VERSION "HNNBNNNYNNNNNNNNNNNNNNNNNNNNNNNNNNNNNNNNNN/4/%%%/4/'%**4NNN///"

NS_ :

BS_:

BU_: BAP_Tester Gateway_Max Getriebe_DQ Motor_konv Parksperre Schaltbetaetigung

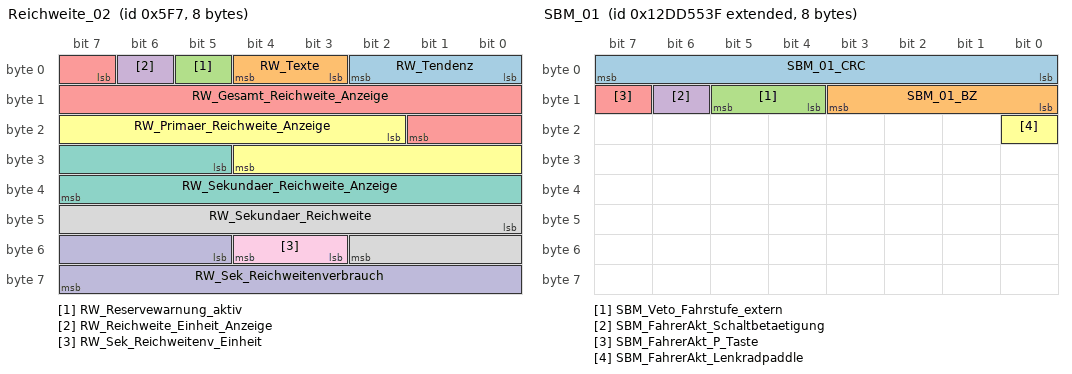
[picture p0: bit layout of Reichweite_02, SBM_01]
BO_ 1527 Reichweite_02: 8 Gateway_Max
 SG_ RW_Tendenz : 0|3@1+ (1.0,0.0) [0.0|7] ""  Vector__XXX
 SG_ RW_Texte : 3|2@1+ (1.0,0.0) [0.0|3] ""  Vector__XXX
 SG_ RW_Reservewarnung_aktiv : 5|1@1+ (1.0,0.0) [0.0|1] ""  Vector__XXX
 SG_ RW_Reichweite_Einheit_Anzeige : 6|1@1+ (1.0,0.0) [0.0|1] ""  Vector__XXX
 SG_ RW_Gesamt_Reichweite_Anzeige : 7|11@1+ (1,0) [0|2044] "Unit_None"  Vector__XXX
 SG_ RW_Primaer_Reichweite_Anzeige : 18|11@1+ (1,0) [0|2044] "Unit_None"  Vector__XXX
 SG_ RW_Sekundaer_Reichweite_Anzeige : 29|11@1+ (1,0) [0|2044] "Unit_None"  Vector__XXX
 SG_ RW_Sekundaer_Reichweite : 40|11@1+ (1,0) [0|2044] "Unit_KiloMeter"  Vector__XXX
 SG_ RW_Sek_Reichweitenv_Einheit : 51|2@1+ (1.0,0.0) [0.0|3] ""  Vector__XXX
 SG_ RW_Sek_Reichweitenverbrauch : 53|11@1+ (0.1,0) [0.0|204.4] "Unit_None"  Vector__XXX

BO_ 2264486920 RHP_01: 32 Gateway_Max
 SG_ RHP_01_CRC : 0|8@1+ (1,0) [0|255] ""  Motor_konv
 SG_ RHP_01_BZ : 8|4@1+ (1,0) [0|15] ""  Motor_konv
 SG_ RHP_QFK_AnfStat : 12|4@1+ (1.0,0.0) [0.0|15] ""  Vector__XXX
 SG_ RHP_QFK_Spuerb : 16|8@1+ (0.4,0) [0.0|100.0] "Unit_PerCent"  Vector__XXX
 SG_ RHP_QFK_KruemmSoll : 24|15@1+ (0.0000067,0) [0E-7|0.2195389] "Unit_MeterInver"  Vector__XXX
 SG_ RHP_TV_Trigger : 39|1@1+ (1.0,0.0) [0.0|1] ""  Vector__XXX
 SG_ RHP_QFK_Signal1 : 40|10@1+ (1,0) [0|1023] ""  Vector__XXX
 SG_ RHP_QFK_Art1 : 50|3@1+ (1,0) [0|7] ""  Vector__XXX
 SG_ RHP_QFK_Art2 : 53|3@1+ (1,0) [0|7] ""  Vector__XXX
 SG_ RHP_QFK_Signal2 : 56|10@1+ (1,0) [0|1023] ""  Vector__XXX
 SG_ RHP_QFK_KruemmSoll_VZ : 66|1@1+ (1.0,0.0) [0.0|1] ""  Vector__XXX
 SG_ RHP_Status_Long : 67|3@1+ (1.0,0.0) [0.0|7] ""  Vector__XXX
 SG_ RHP_Ruckfreigabe : 70|1@1+ (1.0,0.0) [0.0|1] ""  Vector__XXX
 SG_ RHP_Warnruckeln_Anf : 71|3@1+ (1.0,0.0) [0.0|7] ""  Vector__XXX
 SG_ RHP_Anf_ASIL : 74|3@1+ (1.0,0.0) [0.0|7] ""  Vector__XXX
 SG_ RHP_Anforderung_HMS : 77|3@1+ (1.0,0.0) [0.0|7] ""  Vector__XXX
 SG_ RHP_pos_Sollbeschl_Grad : 80|8@1+ (0.05,0) [0.00|12.75] "Unit_MeterPerCubicSecon"  Motor_konv
 SG_ RHP_neg_Sollbeschl_Grad : 88|8@1+ (0.05,0) [0.00|12.75] "Unit_MeterPerCubicSecon"  Motor_konv
 SG_ RHP_Sollbeschleunigung : 96|11@1+ (0.005,-7.22) [-7.220|3.005] "Unit_MeterPerSeconSquar"  Motor_konv
 SG_ RHP_zul_Regelabw_oben : 107|5@1+ (0.0625,0) [0.0000|1.9375] "Unit_MeterPerSeconSquar"  Motor_konv
 SG_ RHP_zul_Regelabw_unten : 112|6@1+ (0.024,0) [0.000|1.512] "Unit_MeterPerSeconSquar"  Motor_konv
 SG_ RHP_TSK_Status : 118|3@1+ (1.0,0.0) [0.0|7] ""  Motor_konv
 SG_ RHP_Minimale_Bremsung : 121|1@1+ (1.0,0.0) [0.0|1] ""  Motor_konv
 SG_ RHP_Uss_Anforderung : 122|2@1+ (1.0,0.0) [0.0|3] ""  Vector__XXX
 SG_ RHP_Verz_Anf : 124|10@1+ (0.024,-20.016) [-20.016|4.512] "Unit_MeterPerSeconSquar"  Vector__XXX
 SG_ RHP_Verz_Freigabe : 134|1@1+ (1.0,0.0) [0.0|1] ""  Vector__XXX
 SG_ RHP_Status_Lat : 135|3@1+ (1.0,0.0) [0.0|7] ""  Vector__XXX
 SG_ RHP_StartStopp_Info : 138|2@1+ (1.0,0.0) [0.0|3] ""  Motor_konv
 SG_ RHP_nachtr_Stopp_Anf : 140|1@1+ (1.0,0.0) [0.0|1] ""  Motor_konv
 SG_ RHP_Freilaufstrategie_TSK : 141|1@1+ (1.0,0.0) [0.0|1] ""  Motor_konv
 SG_ RHP_SCAM_HeatingRequest : 142|2@1+ (1.0,0.0) [0.0|3] ""  Vector__XXX
 SG_ RHP_Fahrzeughupe_Anf : 144|1@1+ (1.0,0.0) [0.0|1] ""  Vector__XXX
 SG_ RHP_HOS : 145|2@1+ (1.0,0.0) [0.0|3] ""  Vector__XXX
 SG_ RHP_Status_Function : 147|3@1+ (1.0,0.0) [0.0|7] ""  Motor_konv
 SG_ RHP_EA_AnfStat : 150|2@1+ (1.0,0.0) [0.0|3] ""  Vector__XXX
 SG_ RHP_QFK_KrSoll : 152|16@1+ (0.0000067,0) [0E-7|0.4390845] "Unit_MeterInver"  Vector__XXX
 SG_ RHP_QFK_KrSoll_VZ : 168|1@1+ (1.0,0.0) [0.0|1] ""  Vector__XXX
 SG_ RHP_Warnblinken : 169|1@1+ (1.0,0.0) [0.0|1] ""  Vector__XXX
 SG_ RHP_Innenraumlicht_Anf : 170|1@1+ (1.0,0.0) [0.0|1] ""  Vector__XXX
 SG_ RHP_Spurwechsel_Ready : 171|3@1+ (1.0,0.0) [0.0|7] ""  Vector__XXX
 SG_ RHP_RBF_Available : 174|2@1+ (1.0,0.0) [0.0|3] ""  Vector__XXX
 SG_ RHP_PreCrash_Anf : 176|3@1+ (1.0,0.0) [0.0|7] ""  Vector__XXX
 SG_ RHP_EA_PreCrash : 179|3@1+ (1.0,0.0) [0.0|7] ""  Vector__XXX
 SG_ RHP_Parking_St : 182|2@1+ (1.0,0.0) [0.0|3] ""  Vector__XXX
 SG_ RHP_EA_Innenraumlicht : 184|1@1+ (1.0,0.0) [0.0|1] ""  Vector__XXX
 SG_ RHP_EA_eCall : 185|1@1+ (1.0,0.0) [0.0|1] ""  Vector__XXX
 SG_ RHP_OPSEnable : 186|2@1+ (1.0,0.0) [0.0|3] ""  Vector__XXX
 SG_ RHP_eCall_Anf : 188|1@1+ (1.0,0.0) [0.0|1] ""  Vector__XXX
 SG_ RHP_EA_Tueren : 189|1@1+ (1.0,0.0) [0.0|1] ""  Vector__XXX

BO_ 2463978815 SBM_01: 8 Getriebe_DQ
 SG_ SBM_01_CRC : 0|8@1+ (1,0) [0|255] ""  Gateway_Max
 SG_ SBM_01_BZ : 8|4@1+ (1,0) [0|15] ""  Gateway_Max
 SG_ SBM_Veto_Fahrstufe_extern : 12|2@1+ (1.0,0.0) [0.0|3] ""  Gateway_Max
 SG_ SBM_FahrerAkt_Schaltbetaetigung : 14|1@1+ (1.0,0.0) [0.0|1] ""  Gateway_Max
 SG_ SBM_FahrerAkt_P_Taste : 15|1@1+ (1.0,0.0) [0.0|1] ""  Gateway_Max
 SG_ SBM_FahrerAkt_Lenkradpaddle : 16|1@1+ (1.0,0.0) [0.0|1] ""  Gateway_Max

BO_ 980 SMLS_01: 8 Gateway_Max
 SG_ SMLS_01_CRC : 0|8@1+ (1,0) [0|255] ""  Vector__XXX
 SG_ SMLS_01_BZ : 8|4@1+ (1,0) [0|15] ""  Vector__XXX
 SG_ BH_Blinker_li : 12|1@1+ (1.0,0.0) [0.0|1] ""  Motor_konv
 SG_ BH_Blinker_re : 13|1@1+ (1.0,0.0) [0.0|1] ""  Motor_konv
 SG_ BH_Lichthupe : 14|1@1+ (1.0,0.0) [0.0|1] ""  Vector__XXX
 SG_ BH_Fernlicht : 15|1@1+ (1.0,0.0) [0.0|1] ""  Vector__XXX
 SG_ WH_Tipwischen : 16|1@1+ (1.0,0.0) [0.0|1] ""  Vector__XXX
 SG_ WH_Intervall : 17|1@1+ (1.0,0.0) [0.0|1] ""  Vector__XXX
 SG_ WH_WischerStufe1 : 18|1@1+ (1.0,0.0) [0.0|1] ""  Vector__XXX
 SG_ WH_WischerStufe2 : 19|1@1+ (1.0,0.0) [0.0|1] ""  Vector__XXX
 SG_ WH_Frontwaschen : 20|1@1+ (1.0,0.0) [0.0|1] ""  Vector__XXX
 SG_ WH_Heckintervall : 21|1@1+ (1.0,0.0) [0.0|1] ""  Vector__XXX
 SG_ WH_Heckwaschen : 22|1@1+ (1.0,0.0) [0.0|1] ""  Vector__XXX
 SG_ WH_Intervallstufen : 23|4@1+ (1.0,0.0) [0.0|15] ""  Vector__XXX
 SG_ FAS_Taster : 27|1@1+ (1.0,0.0) [0.0|1] ""  Vector__XXX
 SG_ FAS_Taster_Fehler : 28|1@1+ (1.0,0.0) [0.0|1] ""  Vector__XXX
 SG_ SMLS_Hupe : 29|1@1+ (1.0,0.0) [0.0|1] ""  Vector__XXX
 SG_ LRH_On_Off : 30|2@1+ (1.0,0.0) [0.0|3] ""  Vector__XXX
 SG_ LSS_Tastencode : 32|8@1+ (1.0,0.0) [0.0|255] ""  Vector__XXX
 SG_ LRH_aktiv : 40|1@1+ (1.0,0.0) [0.0|1] ""  Vector__XXX
 SG_ SMLS_P_verriegelt : 41|2@1+ (1.0,0.0) [0.0|3] ""  Vector__XXX
 SG_ SMLS_P_verriegelt_plausibel : 43|1@1+ (1.0,0.0) [0.0|1] ""  Vector__XXX
 SG_ WH_SRA : 44|1@1+ (1.0,0.0) [0.0|1] ""  Vector__XXX
 SG_ WH_Wischer_Fehler : 45|1@1+ (1.0,0.0) [0.0|1] ""  Vector__XXX
 SG_ BH_Blinker_Fehler : 46|1@1+ (1.0,0.0) [0.0|1] ""  Vector__XXX
 SG_ SMLS_PTT : 47|1@1+ (1.0,0.0) [0.0|1] ""  Vector__XXX
 SG_ WH_Tipwischen_lang : 48|1@1+ (1.0,0.0) [0.0|1] ""  Vector__XXX

BO_ 2589283756 SOK_NoAuthenticTime_01: 8 Gateway_Max
 SG_ SOK_ungeschuetzte_Zeit : 8|56@1+ (1,0) [1|72057594037927935] "Unit_None"  Getriebe_DQ,Motor_konv

BO_ 2464153724 SOK_Zeit_EMotor_01_Chal_01: 8 Vector__XXX
 SG_ SOK_Zeit_EMotor_01_Challenge : 0|64@1+ (1,0) [0|18446744073709551615] "Unit_None"  Gateway_Max

BO_ 2464284796 SOK_Zeit_EMotor_01_Resp_01: 16 Gateway_Max
 SG_ SOK_Zeit_EMotor_01_Zeit : 0|56@1+ (1,0) [0|72057594037927935] "Unit_None"  Vector__XXX
 SG_ SOK_Zeit_EMotor_01_Signatur : 64|64@1+ (1,0) [0|18446744073709551615] "Unit_None"  Vector__XXX

BO_ 2464153784 SOK_Zeit_EMotor_02_Chal_01: 8 Vector__XXX
 SG_ SOK_Zeit_EMotor_02_Challenge : 0|64@1+ (1,0) [0|18446744073709551615] "Unit_None"  Gateway_Max

BO_ 2464284856 SOK_Zeit_EMotor_02_Resp_01: 16 Gateway_Max
 SG_ SOK_Zeit_EMotor_02_Zeit : 0|56@1+ (1,0) [0|72057594037927935] "Unit_None"  Vector__XXX
 SG_ SOK_Zeit_EMotor_02_Signatur : 64|64@1+ (1,0) [0|18446744073709551615] "Unit_None"  Vector__XXX

BO_ 2464153719 SOK_Zeit_Getriebe_01_Chal_01: 8 Getriebe_DQ
 SG_ SOK_Zeit_Getriebe_01_Challenge : 0|64@1+ (1,0) [0|18446744073709551615] "Unit_None"  Gateway_Max

BO_ 2464284791 SOK_Zeit_Getriebe_01_Resp_01: 16 Gateway_Max
 SG_ SOK_Zeit_Getriebe_01_Zeit : 0|56@1+ (1,0) [0|72057594037927935] "Unit_None"  Getriebe_DQ
 SG_ SOK_Zeit_Getriebe_01_Signatur : 64|64@1+ (1,0) [0|18446744073709551615] "Unit_None"  Getriebe_DQ

BO_ 2464153913 SOK_Zeit_LCU_SMH_Chal_01: 8 Vector__XXX
 SG_ SOK_Zeit_LCU_SMH_Challenge : 0|64@1+ (1,0) [0|18446744073709551615] "Unit_None"  Gateway_Max

BO_ 2464284985 SOK_Zeit_LCU_SMH_Resp_01: 16 Gateway_Max
 SG_ SOK_Zeit_LCU_SMH_Zeit : 0|56@1+ (1,0) [0|72057594037927935] "Unit_None"  Vector__XXX
 SG_ SOK_Zeit_LCU_SMH_Signatur : 64|64@1+ (1,0) [0|18446744073709551615] ""  Vector__XXX

BO_ 2464157814 SOK_Zeit_MO_01_Chal_02: 8 Motor_konv
 SG_ SOK_Zeit_MO_01_Challenge : 0|64@1+ (1,0) [0|18446744073709551615] "Unit_None"  Gateway_Max

BO_ 2464288886 SOK_Zeit_MO_01_Resp_02: 16 Gateway_Max
 SG_ SOK_Zeit_MO_01_Zeit : 0|56@1+ (1,0) [0|72057594037927935] "Unit_None"  Motor_konv
 SG_ SOK_Zeit_MO_01_Signatur : 64|64@1+ (1,0) [0|18446744073709551615] "Unit_None"  Motor_konv

BO_ 2464153733 SOK_Zeit_RSG_Chal_01: 8 Vector__XXX
 SG_ SOK_Zeit_RSG_Challenge : 0|64@1+ (1,0) [0|18446744073709551615] "Unit_None"  Gateway_Max

BO_ 2464284805 SOK_Zeit_RSG_Resp_01: 16 Gateway_Max
 SG_ SOK_Zeit_RSG_Zeit : 0|56@1+ (1,0) [0|72057594037927935] "Unit_None"  Vector__XXX
 SG_ SOK_Zeit_RSG_Signatur : 64|64@1+ (1,0) [0|18446744073709551615] ""  Vector__XXX

BO_ 1313 STH_01: 8 Gateway_Max
 SG_ STH_Funk_ein : 0|1@1+ (1.0,0.0) [0.0|1] ""  Vector__XXX
 SG_ STH_Funk_aus : 1|1@1+ (1.0,0.0) [0.0|1] ""  Vector__XXX
 SG_ STH_Zusatzheizung : 2|1@1+ (1.0,0.0) [0.0|1] ""  Motor_konv
 SG_ STH_LED : 3|1@1+ (1.0,0.0) [0.0|1] ""  Motor_konv
 SG_ STH_Pumpe_ein : 4|1@1+ (1,0) [0|1] ""  Motor_konv
 SG_ STH_Geblaese : 5|1@1+ (1.0,0.0) [0.0|1] ""  Vector__XXX
 SG_ STH_EKP_Anst : 6|1@1+ (1.0,0.0) [0.0|1] ""  Motor_konv
 SG_ STH_Start_folgt : 7|1@1+ (1.0,0.0) [0.0|1] ""  Vector__XXX
 SG_ STH_Ventiloeffnungszeit : 8|6@1+ (1,0) [0|63] "Unit_Minut"  Vector__XXX
 SG_ STH_Ventil_Status : 14|1@1+ (1.0,0.0) [0.0|1] ""  Motor_konv
 SG_ STH_Fehler_ElWaPu : 15|1@1+ (1.0,0.0) [0.0|1] ""  Motor_konv
 SG_ STH_Waermeeintrag : 16|6@1+ (1,0) [0|63] "Unit_None"  Motor_konv
 SG_ STH_Pumpen_Anf_extern : 22|1@1+ (1.0,0.0) [0.0|1] ""  Motor_konv
 SG_ STH_KL_HUP : 23|1@1+ (1.0,0.0) [0.0|1] ""  Vector__XXX
 SG_ STH_KVS : 24|13@1+ (1,0) [0|8191] "Unit_MilliLiter"  Vector__XXX
 SG_ STH_Fehlerstatus : 37|3@1+ (1.0,0.0) [0.0|7] ""  Vector__XXX
 SG_ STH_Heizleistung : 40|8@1+ (1,0) [0|255] ""  Vector__XXX
 SG_ STH_Wassertemp : 48|8@1+ (0.75,-40) [-40.00|142.25] "Unit_DegreCelsi"  Motor_konv
 SG_ STH_Texte : 56|3@1+ (1.0,0.0) [0.0|7] ""  Vector__XXX
 SG_ STH_Motorvorwaermung : 59|1@1+ (1.0,0.0) [0.0|1] ""  Motor_konv
 SG_ STH_Servicemode : 60|1@1+ (1.0,0.0) [0.0|1] ""  Vector__XXX
 SG_ STH_war_aktiv : 61|1@1+ (1.0,0.0) [0.0|1] ""  Motor_konv
 SG_ STH_KVS_Ueberlauf : 62|1@1+ (1.0,0.0) [0.0|1] ""  Vector__XXX
 SG_ STH_SH_ZH : 63|1@1+ (1.0,0.0) [0.0|1] ""  Vector__XXX

BO_ 1413 Systeminfo_01: 8 Gateway_Max
 SG_ SI_Sammel_SG_Fehler : 0|6@1+ (1,0) [0|60] ""  Vector__XXX
 SG_ SI_P_Mode_gueltig : 6|1@1+ (1.0,0.0) [0.0|1] ""  Getriebe_DQ,Motor_konv
 SG_ SI_Diagnose_Aktiv : 7|1@1+ (1.0,0.0) [0.0|1] ""  Vector__XXX
 SG_ SI_QRS_Mode : 8|1@1+ (1.0,0.0) [0.0|1] ""  Getriebe_DQ,Motor_konv
 SG_ SI_T_Mode : 9|1@1+ (1.0,0.0) [0.0|1] ""  Getriebe_DQ,Motor_konv
 SG_ SI_NWDF : 10|1@1+ (1.0,0.0) [0.0|1] ""  Getriebe_DQ
 SG_ SI_NWDF_gueltig : 11|1@1+ (1.0,0.0) [0.0|1] ""  Getriebe_DQ
 SG_ SI_Sammelfehler : 12|1@1+ (1.0,0.0) [0.0|1] ""  Vector__XXX
 SG_ GW_KD_Fehler : 13|1@1+ (1.0,0.0) [0.0|1] ""  Vector__XXX
 SG_ SI_T_Schutz : 14|1@1+ (1.0,0.0) [0.0|1] ""  Getriebe_DQ,Motor_konv
 SG_ SI_P_Mode : 15|1@1+ (1.0,0.0) [0.0|1] ""  Getriebe_DQ,Motor_konv
 SG_ SI_BUS_01 : 16|1@1+ (1.0,0.0) [0.0|1] ""  Vector__XXX
 SG_ SI_BUS_02 : 17|1@1+ (1.0,0.0) [0.0|1] ""  Getriebe_DQ
 SG_ SI_BUS_03 : 18|1@1+ (1.0,0.0) [0.0|1] ""  Getriebe_DQ,Motor_konv
 SG_ SI_BUS_04 : 19|1@1+ (1.0,0.0) [0.0|1] ""  Vector__XXX
 SG_ SI_BUS_05 : 20|1@1+ (1.0,0.0) [0.0|1] ""  Vector__XXX
 SG_ SI_BUS_06 : 21|1@1+ (1.0,0.0) [0.0|1] ""  Getriebe_DQ
 SG_ SI_BUS_07 : 22|1@1+ (1.0,0.0) [0.0|1] ""  Vector__XXX
 SG_ SI_BUS_08 : 23|1@1+ (1.0,0.0) [0.0|1] ""  Vector__XXX
 SG_ SI_BUS_09 : 24|1@1+ (1.0,0.0) [0.0|1] ""  Vector__XXX
 SG_ SI_BUS_10 : 25|1@1+ (1.0,0.0) [0.0|1] ""  Vector__XXX
 SG_ SI_BUS_11 : 26|1@1+ (1.0,0.0) [0.0|1] ""  Vector__XXX
 SG_ SI_BUS_12 : 27|1@1+ (1.0,0.0) [0.0|1] ""  Vector__XXX
 SG_ SI_BUS_13 : 28|1@1+ (1.0,0.0) [0.0|1] ""  Vector__XXX
 SG_ SI_BUS_14 : 29|1@1+ (1.0,0.0) [0.0|1] ""  Vector__XXX
 SG_ SI_BUS_15 : 30|1@1+ (1.0,0.0) [0.0|1] ""  Vector__XXX
 SG_ SI_NWDF_30 : 31|1@1+ (1.0,0.0) [0.0|1] ""  Vector__XXX
 SG_ SI_Bus_Identifikation : 32|8@1+ (1.0,0.0) [0.0|255] ""  Vector__XXX
 SG_ SI_CAB_V14 : 40|24@1+ (1.0,0.0) [0.0|16777215] ""  Motor_konv

BO_ 2589283571 TLI_03: 16 Gateway_Max
 SG_ TLI_LSA1_Info_Backlog : 12|2@1+ (1.0,0.0) [0.0|3] ""  Motor_konv
 SG_ TLI_LSA1_GLOSA_Unit : 14|2@1+ (1.0,0.0) [0.0|3] ""  Motor_konv
 SG_ TLI_LSA1_TTG : 16|8@1+ (1,0) [0|250] "Unit_Secon"  Motor_konv
 SG_ TLI_LSA1_GLOSA : 24|8@1+ (1,0) [0|200] "Unit_None"  Motor_konv
 SG_ TLI_LSA1_GLOSA_Display : 32|8@1+ (1,0) [0|200] "Unit_None"  Motor_konv
 SG_ TLI_LSA1_Data_Age : 40|12@1+ (0.1,0) [0.0|400.0] "Unit_Secon"  Motor_konv
 SG_ TLI_LSA1_Data_Source : 52|3@1+ (1.0,0.0) [0.0|7] ""  Motor_konv
 SG_ TLI_LSA1_Distance_Backlog : 55|9@1+ (1,0) [0|500] "Unit_Meter"  Motor_konv
 SG_ TLI_LSA1_Distance_Stop_Line : 64|13@1+ (0.1,0) [0.0|500.0] "Unit_Meter"  Motor_konv
 SG_ TLI_LSA1_Direction_N : 78|2@1+ (1.0,0.0) [0.0|3] ""  Motor_konv
 SG_ TLI_LSA1_Direction_NE : 80|2@1+ (1.0,0.0) [0.0|3] ""  Motor_konv
 SG_ TLI_LSA1_Direction_E : 82|2@1+ (1.0,0.0) [0.0|3] ""  Motor_konv
 SG_ TLI_LSA1_Direction_SE : 84|2@1+ (1.0,0.0) [0.0|3] ""  Motor_konv
 SG_ TLI_LSA1_Direction_SW : 86|2@1+ (1.0,0.0) [0.0|3] ""  Motor_konv
 SG_ TLI_LSA1_Direction_W : 88|2@1+ (1.0,0.0) [0.0|3] ""  Motor_konv
 SG_ TLI_LSA1_Direction_NW : 90|2@1+ (1.0,0.0) [0.0|3] ""  Motor_konv
 SG_ TLI_LSA1_Direction_U_Turn_NE : 92|2@1+ (1.0,0.0) [0.0|3] ""  Motor_konv
 SG_ TLI_LSA1_Direction_U_Turn_NW : 94|2@1+ (1.0,0.0) [0.0|3] ""  Motor_konv

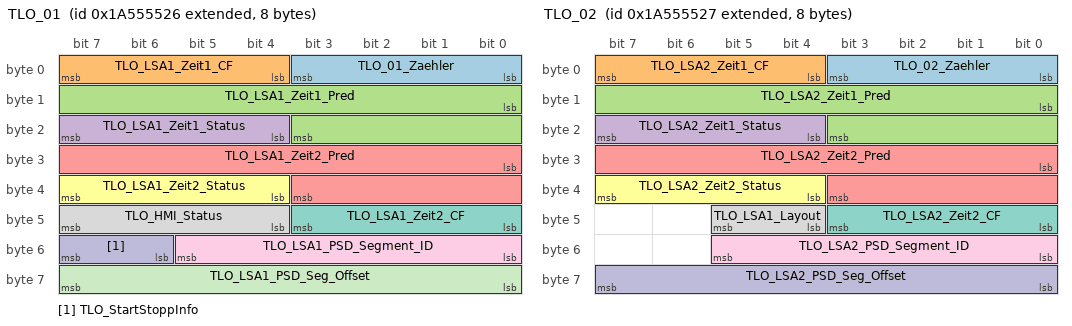
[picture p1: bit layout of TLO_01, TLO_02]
BO_ 2589283622 TLO_01: 8 Gateway_Max
 SG_ TLO_01_Zaehler : 0|4@1+ (1,0) [0|15] ""  Motor_konv
 SG_ TLO_LSA1_Zeit1_CF : 4|4@1+ (1,0) [0|15] "Unit_None"  Motor_konv
 SG_ TLO_LSA1_Zeit1_Pred : 8|12@1+ (0.1,-0.1) [0.0|409.4] "Unit_Secon"  Motor_konv
 SG_ TLO_LSA1_Zeit1_Status : 20|4@1+ (1.0,0.0) [0.0|15] ""  Motor_konv
 SG_ TLO_LSA1_Zeit2_Pred : 24|12@1+ (0.1,-0.1) [0.0|409.4] "Unit_Secon"  Motor_konv
 SG_ TLO_LSA1_Zeit2_Status : 36|4@1+ (1.0,0.0) [0.0|15] ""  Motor_konv
 SG_ TLO_LSA1_Zeit2_CF : 40|4@1+ (1,0) [0|15] "Unit_None"  Motor_konv
 SG_ TLO_HMI_Status : 44|4@1+ (1.0,0.0) [0.0|15] ""  Motor_konv
 SG_ TLO_LSA1_PSD_Segment_ID : 48|6@1+ (1,0) [2|63] "Unit_None"  Motor_konv
 SG_ TLO_StartStoppInfo : 54|2@1+ (1.0,0.0) [0.0|3] ""  Motor_konv
 SG_ TLO_LSA1_PSD_Seg_Offset : 56|8@1+ (1,0) [0|254] "Unit_Meter"  Motor_konv

BO_ 2589283623 TLO_02: 8 Gateway_Max
 SG_ TLO_02_Zaehler : 0|4@1+ (1,0) [0|15] ""  Motor_konv
 SG_ TLO_LSA2_Zeit1_CF : 4|4@1+ (1,0) [0|15] "Unit_None"  Motor_konv
 SG_ TLO_LSA2_Zeit1_Pred : 8|12@1+ (0.1,-0.1) [0.0|409.4] "Unit_Secon"  Motor_konv
 SG_ TLO_LSA2_Zeit1_Status : 20|4@1+ (1.0,0.0) [0.0|15] ""  Motor_konv
 SG_ TLO_LSA2_Zeit2_Pred : 24|12@1+ (0.1,-0.1) [0.0|409.4] "Unit_Secon"  Motor_konv
 SG_ TLO_LSA2_Zeit2_Status : 36|4@1+ (1.0,0.0) [0.0|15] ""  Motor_konv
 SG_ TLO_LSA2_Zeit2_CF : 40|4@1+ (1,0) [0|15] "Unit_None"  Motor_konv
 SG_ TLO_LSA1_Layout : 44|2@1+ (1.0,0.0) [0.0|3] ""  Motor_konv
 SG_ TLO_LSA2_PSD_Segment_ID : 48|6@1+ (1,0) [2|63] "Unit_None"  Motor_konv
 SG_ TLO_LSA2_PSD_Seg_Offset : 56|8@1+ (1,0) [0|254] "Unit_Meter"  Motor_konv

BO_ 1447 TM_01: 8 Gateway_Max
 SG_ ORU_KombiTimer : 20|2@1+ (1.0,0.0) [0.0|3] ""  Vector__XXX
 SG_ MOD_Energie_Anf : 22|2@1+ (1.0,0.0) [0.0|3] ""  Vector__XXX
 SG_ FaceRec_Enroll_Challenge_Request : 24|1@1+ (1.0,0.0) [0.0|1] ""  Vector__XXX
 SG_ eCall_Mute_Anf : 25|1@1+ (1.0,0.0) [0.0|1] ""  Vector__XXX
 SG_ eCall_MCC : 26|10@1+ (1,0) [0|999] "Unit_None"  Vector__XXX
 SG_ FoD_Anz_Funktionsabschaltung : 36|2@1+ (1.0,0.0) [0.0|3] ""  Vector__XXX
 SG_ iCall_active : 38|1@1+ (1.0,0.0) [0.0|1] ""  Vector__XXX
 SG_ bCall_active : 39|1@1+ (1.0,0.0) [0.0|1] ""  Vector__XXX
 SG_ MOD_Request_ServiceKey : 40|1@1+ (1.0,0.0) [0.0|1] ""  Vector__XXX
 SG_ eCall_Funktionsstatus_02 : 41|3@1+ (1.0,0.0) [0.0|7] ""  Vector__XXX
 SG_ eCall_Funktionsstatus : 44|3@1+ (1.0,0.0) [0.0|7] ""  Vector__XXX
 SG_ TM_Spiegel_Anklappen : 47|1@1+ (1.0,0.0) [0.0|1] ""  Vector__XXX
 SG_ TM_Nur_Hupen : 48|1@1+ (1.0,0.0) [0.0|1] ""  Vector__XXX
 SG_ TM_Door_Lock : 49|1@1+ (1.0,0.0) [0.0|1] ""  Vector__XXX
 SG_ TM_Door_Unlock : 50|1@1+ (1.0,0.0) [0.0|1] ""  Vector__XXX
 SG_ TM_Warnblinken : 51|1@1+ (1.0,0.0) [0.0|1] ""  Vector__XXX
 SG_ TM_Panik_Alarm : 52|1@1+ (1.0,0.0) [0.0|1] ""  Vector__XXX
 SG_ TM_ZV_Signatur : 53|11@1+ (1,0) [1|2047] "Unit_None"  Vector__XXX

BO_ 976 TSG_FT_01: 8 Gateway_Max
 SG_ FT_Tuer_geoeffnet : 0|1@1+ (1.0,0.0) [0.0|1] ""  Vector__XXX
 SG_ FT_verriegelt : 1|1@1+ (1.0,0.0) [0.0|1] ""  Vector__XXX
 SG_ FT_gesafet : 2|1@1+ (1.0,0.0) [0.0|1] ""  Vector__XXX
 SG_ FT_Schluesselschalter_auf : 3|1@1+ (1.0,0.0) [0.0|1] ""  Vector__XXX
 SG_ FT_Schluesselschalter_zu : 4|1@1+ (1.0,0.0) [0.0|1] ""  Vector__XXX
 SG_ FT_Unlock_Taster : 5|1@1+ (1.0,0.0) [0.0|1] ""  Vector__XXX
 SG_ FT_Lock_Taster : 6|1@1+ (1.0,0.0) [0.0|1] ""  Vector__XXX
 SG_ FT_Sperrklinke : 7|1@1+ (1.0,0.0) [0.0|1] ""  Vector__XXX
 SG_ FT_TAG_betaetigt : 8|1@1+ (1.0,0.0) [0.0|1] ""  Vector__XXX
 SG_ FT_TIG_betaetigt : 9|1@1+ (1.0,0.0) [0.0|1] ""  Vector__XXX
 SG_ FT_IRUE_Taste : 10|1@1+ (1.0,0.0) [0.0|1] ""  Vector__XXX
 SG_ FT_HD_Taste : 11|1@1+ (1.0,0.0) [0.0|1] ""  Vector__XXX
 SG_ FT_TD_Taste_Fehler : 12|1@1+ (1.0,0.0) [0.0|1] ""  Vector__XXX
 SG_ FT_TD_Taste : 13|1@1+ (1.0,0.0) [0.0|1] ""  Vector__XXX
 SG_ SSR_Temp_Freigabe : 14|1@1+ (1.0,0.0) [0.0|1] ""  Vector__XXX
 SG_ FT_Sp_Heizung_Anf : 15|1@1+ (100,0) [0|100] "Unit_PerCent"  Vector__XXX
 SG_ FT_HD_Taste_2 : 16|1@1+ (1.0,0.0) [0.0|1] ""  Vector__XXX
 SG_ FT_Lock_Unlock_Taster : 17|1@1+ (1.0,0.0) [0.0|1] ""  Vector__XXX
 SG_ FT_TSG_hinten_verbaut : 18|1@1+ (1.0,0.0) [0.0|1] ""  Vector__XXX
 SG_ FT_Sp_Blk_def : 19|1@1+ (1.0,0.0) [0.0|1] ""  Vector__XXX
 SG_ FT_FH_S_ManHoch : 20|1@1+ (1.0,0.0) [0.0|1] ""  Vector__XXX
 SG_ FT_FH_S_AutoHoch : 21|1@1+ (1.0,0.0) [0.0|1] ""  Vector__XXX
 SG_ FT_FH_S_ManTief : 22|1@1+ (1.0,0.0) [0.0|1] ""  Vector__XXX
 SG_ FT_FH_S_AutoTief : 23|1@1+ (1.0,0.0) [0.0|1] ""  Vector__XXX
 SG_ FT_FH_Oeffnung : 24|8@1+ (0.5,0) [0.0|100.0] "Unit_PerCent"  Vector__XXX
 SG_ FT_FH_Bew_hoch : 32|1@1+ (1.0,0.0) [0.0|1] ""  Vector__XXX
 SG_ FT_FH_Bew_tief : 33|1@1+ (1.0,0.0) [0.0|1] ""  Vector__XXX
 SG_ FT_FH_Fang : 34|1@1+ (1.0,0.0) [0.0|1] ""  Vector__XXX
 SG_ FT_FH_Block : 35|1@1+ (1.0,0.0) [0.0|1] ""  Vector__XXX
 SG_ FT_FH_Thermo : 36|1@1+ (1.0,0.0) [0.0|1] ""  Vector__XXX
 SG_ FT_UEKB_aktiviert : 37|1@1+ (1.0,0.0) [0.0|1] ""  Vector__XXX
 SG_ ASW_HMI_defekt : 38|1@1+ (1.0,0.0) [0.0|1] ""  Vector__XXX
 SG_ FT_FH_normiert : 39|1@1+ (1.0,0.0) [0.0|1] ""  Vector__XXX
 SG_ FT_Schliesstaster : 40|1@1+ (1.0,0.0) [0.0|1] ""  Vector__XXX
 SG_ FT_Zuziehhilfe_aktiv : 41|1@1+ (1.0,0.0) [0.0|1] ""  Vector__XXX
 SG_ FT_SP_ausgerastet : 42|1@1+ (1.0,0.0) [0.0|1] ""  Vector__XXX
 SG_ FT_SP_lr_aktiv : 43|1@1+ (1.0,0.0) [0.0|1] ""  Vector__XXX
 SG_ FT_SP_ht_aktiv : 44|1@1+ (1.0,0.0) [0.0|1] ""  Vector__XXX
 SG_ ASW_wakeup : 45|1@1+ (1.0,0.0) [0.0|1] ""  Vector__XXX
 SG_ FT_Oben_Block_erw : 46|1@1+ (1.0,0.0) [0.0|1] ""  Vector__XXX
 SG_ FT_Unten_Block_erw : 47|1@1+ (1.0,0.0) [0.0|1] ""  Vector__XXX
 SG_ FT_Kisi_li_aktiv : 48|1@1+ (1.0,0.0) [0.0|1] ""  Vector__XXX
 SG_ FT_Kisi_re_aktiv : 49|1@1+ (1.0,0.0) [0.0|1] ""  Vector__XXX
 SG_ FT_Kisi_Taster_li : 50|1@1+ (1.0,0.0) [0.0|1] ""  Vector__XXX
 SG_ FT_Kisi_Taster_re : 51|1@1+ (1.0,0.0) [0.0|1] ""  Vector__XXX
 SG_ FT_BFS_Fond_Freigabe : 52|1@1+ (1.0,0.0) [0.0|1] ""  Vector__XXX
 SG_ FT_Kisi_Fehler : 53|1@1+ (1.0,0.0) [0.0|1] ""  Vector__XXX
 SG_ FT_Daemmglas : 54|1@1+ (1.0,0.0) [0.0|1] ""  Vector__XXX
 SG_ FT_SP_Heizung_Status : 55|1@1+ (1.0,0.0) [0.0|1] ""  Vector__XXX
 SG_ ASW_Warnung_aktiv_FS : 56|1@1+ (1.0,0.0) [0.0|1] ""  Vector__XXX
 SG_ FT_FH_Pos_oben : 57|1@1+ (1.0,0.0) [0.0|1] ""  Vector__XXX
 SG_ FT_Tuerschloss_defekt : 58|1@1+ (1.0,0.0) [0.0|1] ""  Vector__XXX
 SG_ FT_SWA_Taster : 59|1@1+ (1.0,0.0) [0.0|1] ""  Vector__XXX
 SG_ SWA_HMI_Diagnose : 60|2@1+ (1.0,0.0) [0.0|3] ""  Vector__XXX
 SG_ FS_Status_eTAG : 62|2@1+ (1.0,0.0) [0.0|3] ""  Vector__XXX

BO_ 997 TSG_FT_02: 8 Gateway_Max
 SG_ TSG_FT_02_CRC : 0|8@1+ (1,0) [0|255] ""  Motor_konv
 SG_ TSG_FT_02_BZ : 8|4@1+ (1,0) [0|15] ""  Motor_konv
 SG_ FT_Tuer_Status : 12|2@1+ (1.0,0.0) [0.0|3] ""  Motor_konv
 SG_ FT_Tuer_Status_QBit : 14|1@1+ (1.0,0.0) [0.0|1] ""  Vector__XXX
 SG_ FT_Lock_Taster_02 : 15|1@1+ (1.0,0.0) [0.0|1] ""  Vector__XXX
 SG_ FT_Schluesselschalter_zu_02 : 16|1@1+ (1.0,0.0) [0.0|1] ""  Vector__XXX
 SG_ FT_BFS_Tuer_Status : 17|2@1+ (1.0,0.0) [0.0|3] ""  Vector__XXX
 SG_ FT_HBFS_Tuer_Status : 19|2@1+ (1.0,0.0) [0.0|3] ""  Vector__XXX
 SG_ FT_HFS_Tuer_Status : 21|2@1+ (1.0,0.0) [0.0|3] ""  Vector__XXX
 SG_ FT_Tueroeffnen_Warnung : 23|1@1+ (1.0,0.0) [0.0|1] ""  Vector__XXX
 SG_ FT_SP_Heizung_ein : 24|1@1+ (1.0,0.0) [0.0|1] ""  Vector__XXX
 SG_ FT_Kisi_Taster_li_02 : 25|1@1+ (1.0,0.0) [0.0|1] ""  Vector__XXX
 SG_ FT_Kisi_Taster_re_02 : 26|1@1+ (1.0,0.0) [0.0|1] ""  Vector__XXX
 SG_ FT_TD_Taste_Status : 27|2@1+ (1.0,0.0) [0.0|3] ""  Vector__XXX
 SG_ FT_TCR_Mode_aktiv : 29|1@1+ (1.0,0.0) [0.0|1] ""  Vector__XXX
 SG_ TBF_FS_Touch_Event : 30|4@1+ (1.0,0.0) [0.0|15] ""  Vector__XXX
 SG_ FT_KiSi_Status_Soll_HBFS : 34|1@1+ (1.0,0.0) [0.0|1] ""  Vector__XXX
 SG_ FT_KiSi_Status_Soll_HFS : 35|1@1+ (1.0,0.0) [0.0|1] ""  Vector__XXX
 SG_ FS_Push_Tuergriff : 36|1@1+ (1.0,0.0) [0.0|1] ""  Vector__XXX
 SG_ TSG_FS_Spiegel_angeklappt : 37|1@1+ (1.0,0.0) [0.0|1] ""  Vector__XXX
 SG_ FT_Cargolock_bet : 38|1@1+ (1.0,0.0) [0.0|1] ""  Vector__XXX
 SG_ FT_kisi_asynchron : 40|1@1+ (1.0,0.0) [0.0|1] ""  Vector__XXX
 SG_ eTAB_FS_Bowdenzug_Auswerfen : 41|1@1+ (1.0,0.0) [0.0|1] ""  Vector__XXX
 SG_ FS_Status_eTAG_ext : 42|3@1+ (1.0,0.0) [0.0|7] ""  Vector__XXX
 SG_ FT_ASW_Warnton : 45|2@1+ (1.0,0.0) [0.0|3] ""  Vector__XXX
 SG_ SSA_FT_ASW_Status : 47|2@1+ (1.0,0.0) [0.0|3] ""  Vector__XXX

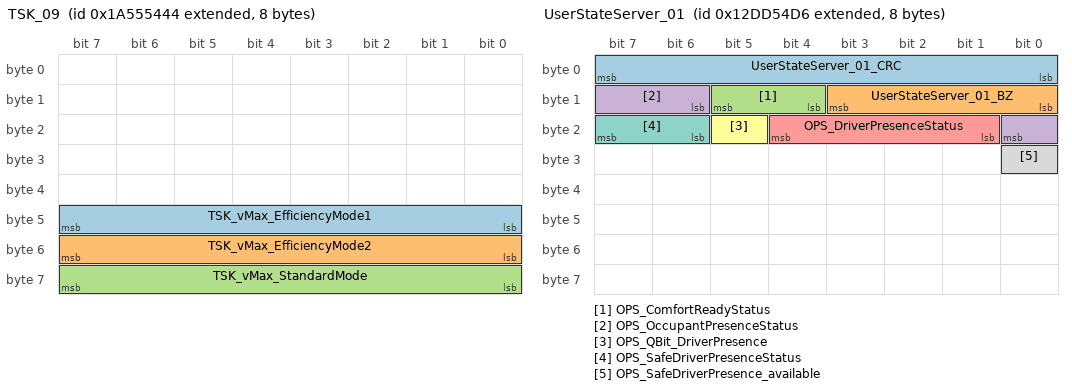
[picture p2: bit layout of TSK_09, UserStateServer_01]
BO_ 2589283396 TSK_09: 8 Motor_konv
 SG_ TSK_vMax_EfficiencyMode1 : 40|8@1+ (1,0) [0|253] "Unit_KiloMeterPerHour"  Gateway_Max
 SG_ TSK_vMax_EfficiencyMode2 : 48|8@1+ (1,0) [0|253] "Unit_KiloMeterPerHour"  Gateway_Max
 SG_ TSK_vMax_StandardMode : 56|8@1+ (1,0) [0|253] "Unit_KiloMeterPerHour"  Gateway_Max

BO_ 1019 TSK_Ausrollkurve_01: 8 Motor_konv
 SG_ TSK_Ausrollkurve_Schub_Reku_01 m0  : 0|7@1+ (2,0) [0|252] "Unit_KiloMeterPerHour"  Gateway_Max
 SG_ TSK_Ausrollkurve_Schub_Reku_05 m1  : 0|7@1+ (2,0) [0|252] "Unit_KiloMeterPerHour"  Gateway_Max
 SG_ TSK_Ausrollkurve_Schub_Reku_09 m2  : 0|7@1+ (2,0) [0|252] "Unit_KiloMeterPerHour"  Gateway_Max
 SG_ TSK_Ausrollkurve_Schub_Reku_13 m3  : 0|7@1+ (2,0) [0|252] "Unit_KiloMeterPerHour"  Gateway_Max
 SG_ TSK_Ausrollkurve_Schub_Reku_17 m4  : 0|7@1+ (2,0) [0|252] "Unit_KiloMeterPerHour"  Gateway_Max
 SG_ TSK_Ausrollkurve_Schub_Reku_02 m0  : 7|7@1+ (2,0) [0|252] "Unit_KiloMeterPerHour"  Gateway_Max
 SG_ TSK_Ausrollkurve_Schub_Reku_06 m1  : 7|7@1+ (2,0) [0|252] "Unit_KiloMeterPerHour"  Gateway_Max
 SG_ TSK_Ausrollkurve_Schub_Reku_10 m2  : 7|7@1+ (2,0) [0|252] "Unit_KiloMeterPerHour"  Gateway_Max
 SG_ TSK_Ausrollkurve_Schub_Reku_14 m3  : 7|7@1+ (2,0) [0|252] "Unit_KiloMeterPerHour"  Gateway_Max
 SG_ TSK_Ausrollkurve_Schub_Reku_18 m4  : 7|7@1+ (2,0) [0|252] "Unit_KiloMeterPerHour"  Gateway_Max
 SG_ TSK_Ausrollkurve_Schub_Reku_03 m0  : 14|7@1+ (2,0) [0|252] "Unit_KiloMeterPerHour"  Gateway_Max
 SG_ TSK_Ausrollkurve_Schub_Reku_07 m1  : 14|7@1+ (2,0) [0|252] "Unit_KiloMeterPerHour"  Gateway_Max
 SG_ TSK_Ausrollkurve_Schub_Reku_11 m2  : 14|7@1+ (2,0) [0|252] "Unit_KiloMeterPerHour"  Gateway_Max
 SG_ TSK_Ausrollkurve_Schub_Reku_15 m3  : 14|7@1+ (2,0) [0|252] "Unit_KiloMeterPerHour"  Gateway_Max
 SG_ TSK_Ausrollkurve_Schub_Reku_19 m4  : 14|7@1+ (2,0) [0|252] "Unit_KiloMeterPerHour"  Gateway_Max
 SG_ TSK_Ausrollkurve_Schub_Reku_04 m0  : 21|7@1+ (2,0) [0|252] "Unit_KiloMeterPerHour"  Gateway_Max
 SG_ TSK_Ausrollkurve_Schub_Reku_08 m1  : 21|7@1+ (2,0) [0|252] "Unit_KiloMeterPerHour"  Gateway_Max
 SG_ TSK_Ausrollkurve_Schub_Reku_12 m2  : 21|7@1+ (2,0) [0|252] "Unit_KiloMeterPerHour"  Gateway_Max
 SG_ TSK_Ausrollkurve_Schub_Reku_16 m3  : 21|7@1+ (2,0) [0|252] "Unit_KiloMeterPerHour"  Gateway_Max
 SG_ TSK_Ausrollkurve_Schub_Reku_20 m4  : 21|7@1+ (2,0) [0|252] "Unit_KiloMeterPerHour"  Gateway_Max
 SG_ TSK_Ausrollkurve_Segeln_01 m0  : 28|7@1+ (2,0) [0|252] "Unit_KiloMeterPerHour"  Gateway_Max
 SG_ TSK_Ausrollkurve_Segeln_05 m1  : 28|7@1+ (2,0) [0|252] "Unit_KiloMeterPerHour"  Gateway_Max
 SG_ TSK_Ausrollkurve_Segeln_09 m2  : 28|7@1+ (2,0) [0|252] "Unit_KiloMeterPerHour"  Gateway_Max
 SG_ TSK_Ausrollkurve_Segeln_13 m3  : 28|7@1+ (2,0) [0|252] "Unit_KiloMeterPerHour"  Gateway_Max
 SG_ TSK_Ausrollkurve_Segeln_17 m4  : 28|7@1+ (2,0) [0|252] "Unit_KiloMeterPerHour"  Gateway_Max
 SG_ TSK_Ausrollkurve_Segeln_02 m0  : 35|7@1+ (2,0) [0|252] "Unit_KiloMeterPerHour"  Gateway_Max
 SG_ TSK_Ausrollkurve_Segeln_06 m1  : 35|7@1+ (2,0) [0|252] "Unit_KiloMeterPerHour"  Gateway_Max
 SG_ TSK_Ausrollkurve_Segeln_10 m2  : 35|7@1+ (2,0) [0|252] "Unit_KiloMeterPerHour"  Gateway_Max
 SG_ TSK_Ausrollkurve_Segeln_14 m3  : 35|7@1+ (2,0) [0|252] "Unit_KiloMeterPerHour"  Gateway_Max
 SG_ TSK_Ausrollkurve_Segeln_18 m4  : 35|7@1+ (2,0) [0|252] "Unit_KiloMeterPerHour"  Gateway_Max
 SG_ TSK_Ausrollkurve_Segeln_03 m0  : 42|7@1+ (2,0) [0|252] "Unit_KiloMeterPerHour"  Gateway_Max
 SG_ TSK_Ausrollkurve_Segeln_07 m1  : 42|7@1+ (2,0) [0|252] "Unit_KiloMeterPerHour"  Gateway_Max
 SG_ TSK_Ausrollkurve_Segeln_11 m2  : 42|7@1+ (2,0) [0|252] "Unit_KiloMeterPerHour"  Gateway_Max
 SG_ TSK_Ausrollkurve_Segeln_15 m3  : 42|7@1+ (2,0) [0|252] "Unit_KiloMeterPerHour"  Gateway_Max
 SG_ TSK_Ausrollkurve_Segeln_19 m4  : 42|7@1+ (2,0) [0|252] "Unit_KiloMeterPerHour"  Gateway_Max
 SG_ TSK_Ausrollkurve_Segeln_04 m0  : 49|7@1+ (2,0) [0|252] "Unit_KiloMeterPerHour"  Gateway_Max
 SG_ TSK_Ausrollkurve_Segeln_08 m1  : 49|7@1+ (2,0) [0|252] "Unit_KiloMeterPerHour"  Gateway_Max
 SG_ TSK_Ausrollkurve_Segeln_12 m2  : 49|7@1+ (2,0) [0|252] "Unit_KiloMeterPerHour"  Gateway_Max
 SG_ TSK_Ausrollkurve_Segeln_16 m3  : 49|7@1+ (2,0) [0|252] "Unit_KiloMeterPerHour"  Gateway_Max
 SG_ TSK_Ausrollkurve_Segeln_20 m4  : 49|7@1+ (2,0) [0|252] "Unit_KiloMeterPerHour"  Gateway_Max
 SG_ TSK_Ausrollkurve_Mux M  : 56|3@1+ (1,0) [0|7] ""  Gateway_Max
 SG_ TSK_Ausrollkurve_Reku : 59|1@1+ (1.0,0.0) [0.0|1] ""  Gateway_Max
 SG_ TSK_Ausrollkurve_Schrittweite : 60|1@1+ (1.0,0.0) [0.0|1] ""  Gateway_Max
 SG_ TSK_Ausrollkurve_Zaehler : 61|2@1+ (1,0) [0|3] ""  Gateway_Max

BO_ 2463978710 UserStateServer_01: 8 Gateway_Max
 SG_ UserStateServer_01_CRC : 0|8@1+ (1,0) [0|255] ""  Getriebe_DQ,Motor_konv
 SG_ UserStateServer_01_BZ : 8|4@1+ (1,0) [0|15] ""  Getriebe_DQ,Motor_konv
 SG_ OPS_ComfortReadyStatus : 12|2@1+ (1.0,0.0) [0.0|3] ""  Vector__XXX
 SG_ OPS_OccupantPresenceStatus : 14|3@1+ (1.0,0.0) [0.0|7] ""  Vector__XXX
 SG_ OPS_DriverPresenceStatus : 17|4@1+ (1.0,0.0) [0.0|15] ""  Vector__XXX
 SG_ OPS_QBit_DriverPresence : 21|1@1+ (1.0,0.0) [0.0|1] ""  Vector__XXX
 SG_ OPS_SafeDriverPresenceStatus : 22|2@1+ (1.0,0.0) [0.0|3] ""  Getriebe_DQ,Motor_konv
 SG_ OPS_SafeDriverPresence_available : 24|1@1+ (1.0,0.0) [0.0|1] ""  Getriebe_DQ,Motor_konv

BO_ 995 Verdeck_01: 8 Gateway_Max
 SG_ VS_VD_zu_ver : 16|1@1+ (1.0,0.0) [0.0|1] ""  Vector__XXX
 SG_ VS_VD_entriegelt : 17|1@1+ (1.0,0.0) [0.0|1] ""  Vector__XXX
 SG_ VS_VD_offen_ver : 18|1@1+ (1.0,0.0) [0.0|1] ""  Vector__XXX
 SG_ VS_VD_Zwischenposition : 19|1@1+ (1.0,0.0) [0.0|1] ""  Vector__XXX
 SG_ VS_VD_Bew_auf : 20|1@1+ (1.0,0.0) [0.0|1] ""  Vector__XXX
 SG_ VS_VD_Bew_zu : 21|1@1+ (1.0,0.0) [0.0|1] ""  Vector__XXX
 SG_ VS_Verdeck_Anf : 22|1@1+ (1.0,0.0) [0.0|1] ""  Vector__XXX
 SG_ VS_Hardtop : 23|1@1+ (1.0,0.0) [0.0|1] ""  Vector__XXX
 SG_ VS_VD_Fehler : 24|1@1+ (1.0,0.0) [0.0|1] ""  Vector__XXX
 SG_ VS_Lampe_Blk : 25|1@1+ (1.0,0.0) [0.0|1] ""  Vector__XXX
 SG_ VS_Buzzer : 26|1@1+ (1.0,0.0) [0.0|1] ""  Vector__XXX
 SG_ VS_HD_sperren : 27|1@1+ (1.0,0.0) [0.0|1] ""  Vector__XXX
 SG_ VS_HHS_enable : 28|1@1+ (1.0,0.0) [0.0|1] ""  Vector__XXX
 SG_ VD_SpannungsAnf : 29|2@1+ (1.0,0.0) [0.0|3] ""  Vector__XXX
 SG_ VS_VDKD_auf : 31|1@1+ (1.0,0.0) [0.0|1] ""  Vector__XXX
 SG_ VS_FS_AutoHoch : 32|1@1+ (1.0,0.0) [0.0|1] ""  Vector__XXX
 SG_ VS_FS_AutoTief : 33|1@1+ (1.0,0.0) [0.0|1] ""  Vector__XXX
 SG_ VS_FS_ManHoch : 34|1@1+ (1.0,0.0) [0.0|1] ""  Vector__XXX
 SG_ VS_FS_ManTief : 35|1@1+ (1.0,0.0) [0.0|1] ""  Vector__XXX
 SG_ VS_BFS_AutoHoch : 36|1@1+ (1.0,0.0) [0.0|1] ""  Vector__XXX
 SG_ VS_BFS_AutoTief : 37|1@1+ (1.0,0.0) [0.0|1] ""  Vector__XXX
 SG_ VS_BFS_ManHoch : 38|1@1+ (1.0,0.0) [0.0|1] ""  Vector__XXX
 SG_ VS_BFS_ManTief : 39|1@1+ (1.0,0.0) [0.0|1] ""  Vector__XXX
 SG_ VS_HFS_AutoHoch : 40|1@1+ (1.0,0.0) [0.0|1] ""  Vector__XXX
 SG_ VS_HFS_AutoTief : 41|1@1+ (1.0,0.0) [0.0|1] ""  Vector__XXX
 SG_ VS_HFS_ManHoch : 42|1@1+ (1.0,0.0) [0.0|1] ""  Vector__XXX
 SG_ VS_HFS_ManTief : 43|1@1+ (1.0,0.0) [0.0|1] ""  Vector__XXX
 SG_ VS_HBFS_AutoHoch : 44|1@1+ (1.0,0.0) [0.0|1] ""  Vector__XXX
 SG_ VS_HBFS_AutoTief : 45|1@1+ (1.0,0.0) [0.0|1] ""  Vector__XXX
 SG_ VS_HBFS_ManHoch : 46|1@1+ (1.0,0.0) [0.0|1] ""  Vector__XXX
 SG_ VS_HBFS_ManTief : 47|1@1+ (1.0,0.0) [0.0|1] ""  Vector__XXX
 SG_ VS_FH_FT_Langhub : 49|1@1+ (1.0,0.0) [0.0|1] ""  Vector__XXX
 SG_ VS_Windschott_nicht_abgelegt : 50|1@1+ (1.0,0.0) [0.0|1] ""  Vector__XXX
 SG_ VS_FH_BT_Langhub : 51|1@1+ (1.0,0.0) [0.0|1] ""  Vector__XXX
 SG_ VS_FH_HFS_Langhub : 53|1@1+ (1.0,0.0) [0.0|1] ""  Vector__XXX
 SG_ VS_Heckschloss_auf : 54|1@1+ (1.0,0.0) [0.0|1] ""  Vector__XXX
 SG_ VS_FH_HBFS_Langhub : 55|1@1+ (1.0,0.0) [0.0|1] ""  Vector__XXX
 SG_ VSG_Meldungen : 56|6@1+ (1,0) [1|63] "Unit_None"  Vector__XXX
 SG_ VS_StartStopp_Info : 62|2@1+ (1.0,0.0) [0.0|3] ""  Vector__XXX

BO_ 1716 VIN_01: 8 Gateway_Max
 SG_ VIN_01_MUX M  : 0|2@1+ (1,0) [0|3] ""  Motor_konv
 SG_ KS_Geheimnis_1 m0  : 8|8@1+ (1,0) [0|255] ""  Vector__XXX
 SG_ VIN_4 m1  : 8|8@1+ (1,0) [0|255] ""  Motor_konv
 SG_ VIN_11 m2  : 8|8@1+ (1,0) [0|255] ""  Motor_konv
 SG_ KS_Geheimnis_2 m0  : 16|8@1+ (1,0) [0|255] ""  Vector__XXX
 SG_ VIN_5 m1  : 16|8@1+ (1,0) [0|255] ""  Motor_konv
 SG_ VIN_12 m2  : 16|8@1+ (1,0) [0|255] ""  Motor_konv
 SG_ KS_Geheimnis_3 m0  : 24|8@1+ (1,0) [0|255] ""  Vector__XXX
 SG_ VIN_6 m1  : 24|8@1+ (1,0) [0|255] ""  Motor_konv
 SG_ VIN_13 m2  : 24|8@1+ (1,0) [0|255] ""  Motor_konv
 SG_ KS_Geheimnis_4 m0  : 32|8@1+ (1,0) [0|255] ""  Vector__XXX
 SG_ VIN_7 m1  : 32|8@1+ (1,0) [0|255] ""  Motor_konv
 SG_ VIN_14 m2  : 32|8@1+ (1,0) [0|255] ""  Motor_konv
 SG_ VIN_1 m0  : 40|8@1+ (1,0) [0|255] ""  Motor_konv
 SG_ VIN_8 m1  : 40|8@1+ (1,0) [0|255] ""  Motor_konv
 SG_ VIN_15 m2  : 40|8@1+ (1,0) [0|255] ""  Motor_konv
 SG_ VIN_2 m0  : 48|8@1+ (1,0) [0|255] ""  Motor_konv
 SG_ VIN_9 m1  : 48|8@1+ (1,0) [0|255] ""  Motor_konv
 SG_ VIN_16 m2  : 48|8@1+ (1,0) [0|255] ""  Motor_konv
 SG_ VIN_3 m0  : 56|8@1+ (1,0) [0|255] ""  Motor_konv
 SG_ VIN_10 m1  : 56|8@1+ (1,0) [0|255] ""  Motor_konv
 SG_ VIN_17 m2  : 56|8@1+ (1,0) [0|255] ""  Motor_konv

CM_ BO_ 980 "Ab MQB 7.2";
CM_ BO_ 1413 "MQB, MLBevo";
CM_ BO_ 976 "ab MQB 7.05";
CM_ BO_ 995 "ab MQB IS5";
CM_ BO_ 1716 "200ms bei D4 und folgende";

CM_ SG_ 1527 RW_Gesamt_Reichweite_Anzeige "Reichweite für primär und sekundär Reichweite (eventuell Gewichtet) zur Anzeige im Kombi. Die Einheit dieser Signal ist über RW_Reichweite_Einheit_Anzeige bereitgestellt.";
CM_ SG_ 1527 RW_Primaer_Reichweite_Anzeige "Reichweite der primären Antriebsart zur Anzeige im Kombi";
CM_ SG_ 1527 RW_Reichweite_Einheit_Anzeige "Einheit für Primaer-/Sekundaer-/Gesamt- Reichweite zur Anzeige im Kombi";
CM_ SG_ 1527 RW_Reservewarnung_aktiv "Ansteuerung der Reservewarnung im Kombiinstrument (Leuchte und MFA-Warnhinweis). Wird gesetzt bei Erreichen / Unterschreiten eines unteren Reichweitenschwellwerts und zurückgenommen bei Erreichen / Überschreiten eines oberen Reichweitenschwellwerts.";
CM_ SG_ 1527 RW_Sek_Reichweitenv_Einheit "Für sekundäre Reichweitenberechnung (KBI_Sek_Reichweitenverbrauch) zugrunde gelegte Einheit";
CM_ SG_ 1527 RW_Sek_Reichweitenverbrauch "Für sekundäre Reichweitenberechnung zugrunde gelegter Verbrauch";
CM_ SG_ 1527 RW_Sekundaer_Reichweite "Reichweite der sekundaeren Antriebsart";
CM_ SG_ 1527 RW_Sekundaer_Reichweite_Anzeige "Reichweite der sekundaeren Antriebsart zur Anzeige im Kombi";
CM_ SG_ 1527 RW_Tendenz "Signalisierung der RW-Tendenz auf Basis der aktuellen Fahrweise. ";
CM_ SG_ 1527 RW_Texte "Signal zum Steuern von reichweitenbezogenen Hinweistexten für Pop-Up Anzeigen im Kombiinstrument";

CM_ SG_ 2264486920 RHP_01_BZ "4bit Botschaftszähler, wird mit jeder Sendebotschaft inkrementiert";
CM_ SG_ 2264486920 RHP_01_CRC "Für MLB:
Berechnung siehe Lastenheft 'Kommunikationsabsicherung für FlexRay und CAN'
Ab MQB und MLBevo:
Berechnung siehe Lastenheft 'End-to-End Kommunikationsabsicherung'

Endwerte siehe Begleitdokument 'S-PDU Kennungsfolgen'";
CM_ SG_ 2264486920 RHP_Anf_ASIL "Definiert das Anforderungssignal von RHP an VZM mit dem dynamischen ASIL";
CM_ SG_ 2264486920 RHP_Anforderung_HMS "Bremsanforderung an den Haltemanager";
CM_ SG_ 2264486920 RHP_EA_AnfStat "This signal indicates the activation status information from RHP to EA";
CM_ SG_ 2264486920 RHP_EA_eCall "RHP triggers eCall via sending the requirements on EA";
CM_ SG_ 2264486920 RHP_EA_Innenraumlicht "RHP turning on interior lights via sending the requirements on EA";
CM_ SG_ 2264486920 RHP_EA_PreCrash "RHP triggers PreCrash via sending the requirements on EA";
CM_ SG_ 2264486920 RHP_EA_Tueren "RHP triggers door unlocking via sending the requirements on EA";
CM_ SG_ 2264486920 RHP_eCall_Anf "RHP triggers eCall";
CM_ SG_ 2264486920 RHP_Fahrzeughupe_Anf "Rush Hour Pilot Anforderung Fahrzeughupe";
CM_ SG_ 2264486920 RHP_Freilaufstrategie_TSK "Das Signal definiert im aktiven RHP - Betrieb, ob ein Freilauf direkt über das RHP angefordert wird oder ein Freilauf über den Triebstrangkoordinator (TSK) angefordert wird, falls das RHP den Freilauf freigibt.";
CM_ SG_ 2264486920 RHP_HOS "Rush Hour Pilot hands-off status";
CM_ SG_ 2264486920 RHP_Innenraumlicht_Anf "RHP turns on interior lights.";
CM_ SG_ 2264486920 RHP_Minimale_Bremsung "Im Falle eines gesetzten Bits wird vom RHP dem TSK angezeigt, dass es sich im Resume_Suspend_Mode befindet. In diesem Mode darf der TSK keine ECD-Bremsung anfordern, unabhängig von der 'RHP_Sollbeschleunigungsanforderung'. Eine Fahrzeugverzögerung darf nu";
CM_ SG_ 2264486920 RHP_nachtr_Stopp_Anf "Dieses Signal dient dem Motor als Trigger, dass ein nachträglicher Motorstopp eingeleitet werden kann, wenn es die Bedingungen des StSt Koordinators dies zulassen.";
CM_ SG_ 2264486920 RHP_neg_Sollbeschl_Grad "Empfehlung an den Triebstrangkoordinator , mit welchem betragsmäßig maximalen negativen Gradienten eine RHP-Anforderung 'RHP_Sollbeschleunigung' einzuregeln ist.";
CM_ SG_ 2264486920 RHP_OPSEnable "The OPS function receives the following signal to enable the function";
CM_ SG_ 2264486920 RHP_Parking_St "The signal shows the parking function status, if the parking function is Slot Detect or Guidance, the parking space should output.";
CM_ SG_ 2264486920 RHP_pos_Sollbeschl_Grad "Empfehlung an den Triebstrangkoordinator , mit welchem betragsmäßig maximalen positiven Gradienten eine RHP-Anforderung 'RHP_Sollbeschleunigung' einzuregeln ist.";
CM_ SG_ 2264486920 RHP_PreCrash_Anf "RHP triggers PreCrash";
CM_ SG_ 2264486920 RHP_QFK_AnfStat "Statusinformationen des Anforderers";
CM_ SG_ 2264486920 RHP_QFK_Art1 "Auswahlsignal für RHP_QFK_Signal1";
CM_ SG_ 2264486920 RHP_QFK_Art2 "Auswahlsignal für RHP_QFK_Signal2";
CM_ SG_ 2264486920 RHP_QFK_KrSoll "Krümmungsanforderung";
CM_ SG_ 2264486920 RHP_QFK_KrSoll_VZ "Vorzeichen für die Krümmungsanforderung";
CM_ SG_ 2264486920 RHP_QFK_KruemmSoll "Krümmungsanforderung";
CM_ SG_ 2264486920 RHP_QFK_KruemmSoll_VZ "Vorzeichen für die Krümmungsanforderung";
CM_ SG_ 2264486920 RHP_QFK_Signal1 "Inhalt RHP_QFK_Signal1 wird durch das Signal RHP_QFK_Art1 gesteuert.
Nähere Informationen im LAH Querführungskoordinator.";
CM_ SG_ 2264486920 RHP_QFK_Signal2 "Inhalt RHP_QFK_Signal2 wird durch das Signal RHP_QFK_Art2 gesteuert.
Nähere Informationen im LAH Querführungskoordinator.";
CM_ SG_ 2264486920 RHP_QFK_Spuerb "Spürbarkeitsanforderung. Legt fest, mit welchem Handmoment die angeforderte Krümmung überlenkt werden muss.";
CM_ SG_ 2264486920 RHP_RBF_Available "This signal is used for info RBF for RHP can support RBF forward or not";
CM_ SG_ 2264486920 RHP_Ruckfreigabe "Anforderung Bremsruck für Funktion Rush Hour Pilot";
CM_ SG_ 2264486920 RHP_SCAM_HeatingRequest "Gibt an, ob eine Beeinträchtigung der Kamerasicht durch Eis oder Beschlag vorliegt und diese durch Anschalten der Scheibenheizung behoben werden kann.";
CM_ SG_ 2264486920 RHP_Sollbeschleunigung "Anforderung an den Triebstrangkoordinator , eine 'RHP_Sollbeschleunigung' umzusetzen.";
CM_ SG_ 2264486920 RHP_Spurwechsel_Ready "Angabe der assistierten Spurwechselmöglichkeiten durch die Funktion 'Rush Hour Pilot'";
CM_ SG_ 2264486920 RHP_StartStopp_Info "Freigabe bzw. Startanforderung für Start/Stopp";
CM_ SG_ 2264486920 RHP_Status_Function "RHP status signal";
CM_ SG_ 2264486920 RHP_Status_Lat "RHP status signal for the lateral control";
CM_ SG_ 2264486920 RHP_Status_Long "RHP status signal for the longitudinal control";
CM_ SG_ 2264486920 RHP_TSK_Status "RHP status signal to TSK";
CM_ SG_ 2264486920 RHP_TV_Trigger "This signal is used for switching on/off TVeMid stream data output for RHP parking function.";
CM_ SG_ 2264486920 RHP_Uss_Anforderung "Control signal from RHP to front side PLA (VLS, VRS) and APS (VL, VR) sensors";
CM_ SG_ 2264486920 RHP_Verz_Anf "Verzögerungsanforderung der Funktionen Zielbremsung und Teilbremsung an das VZM";
CM_ SG_ 2264486920 RHP_Verz_Freigabe "Freigabe-Bit der RHP Verzögerung an das VZM";
CM_ SG_ 2264486920 RHP_Warnblinken "Ansteuerung des Warnblinkers für die Funktion Rush Hour Pilot";
CM_ SG_ 2264486920 RHP_Warnruckeln_Anf "Anforderung an VZM, welches Warnruckeln umgesetzt werden soll.";
CM_ SG_ 2264486920 RHP_zul_Regelabw_oben "Anforderung an den Triebstrangkoordinator. Zulässiger Betrag der Abweichung zwischen angeforderter 'RHP_Sollbeschleunigung' und umzusetzender Sollbeschleunigung  im TSK. Im TSK wird, abhängig vom Arbeitspunkt die Toleranz und die Sollbeschleunigung für da";
CM_ SG_ 2264486920 RHP_zul_Regelabw_unten "Anforderung an den Triebstrangkoordinator. Zulässiger Betrag der Abweichung zwischen angeforderter 'RHP_Sollbeschleunigung' und umzusetzender Sollbeschleunigung  im TSK. Im TSK wird, abhängig vom Arbeitspunkt die Toleranz und die Sollbeschleunigung für da";

CM_ SG_ 2463978815 SBM_01_BZ "4bit Botschaftszähler, wird mit jeder Sendebotschaft inkrementiert";
CM_ SG_ 2463978815 SBM_01_CRC "Für MLB:
Berechnung siehe Lastenheft 'Kommunikationsabsicherung für FlexRay und CAN'
Ab MQB und MLBevo:
Berechnung siehe Lastenheft 'End-to-End Kommunikationsabsicherung'

Endwerte siehe Begleitdokument 'S-PDU Kennungsfolgen'";
CM_ SG_ 2463978815 SBM_FahrerAkt_Lenkradpaddle "Eine Fahreraktion an den Lenkrad-Paddles wurde erkannt (unabhängig davon, ob die Fahrstufe dadurch gewechselt wurde).";
CM_ SG_ 2463978815 SBM_FahrerAkt_P_Taste "Eine Fahreraktion an der P-Taste wurde erkannt (unabhängig davon, ob die Fahrstufe dadurch gewechselt wurde).";
CM_ SG_ 2463978815 SBM_FahrerAkt_Schaltbetaetigung "Eine Fahreraktion an der Schaltbetätigung wurde erkannt (unabhängig davon, ob die Fahrstufe dadurch gewechselt wurde).";
CM_ SG_ 2463978815 SBM_Veto_Fahrstufe_extern "Veto des Schaltbetätigungsmasters hinsichtlich der Umsetzung externer Fahrstufenanforderungen.";

CM_ SG_ 980 BH_Blinker_Fehler "Anzeige, ob am Lenkstockschalter ein Fehler anliegt.
Notwendig aufgrund ASIL-Einstufung";
CM_ SG_ 980 BH_Blinker_li "Blinkerhebel Richtung links";
CM_ SG_ 980 BH_Blinker_re "Blinkerhebel Richtung rechts";
CM_ SG_ 980 BH_Fernlicht "Betaetigung Fernlicht
";
CM_ SG_ 980 BH_Lichthupe "Betaetigung Lichthupe
";
CM_ SG_ 980 FAS_Taster "Betaetigung FAS Taster
";
CM_ SG_ 980 FAS_Taster_Fehler "Fehlerstatus FAS Taster
";
CM_ SG_ 980 LRH_aktiv "Signal gibt an, ob ein Heizstrom durch die Lenkradheizung fließt. Es dient der Auswertung durch das Energiemanagement.";
CM_ SG_ 980 LRH_On_Off "Status Lenkradheizung";
CM_ SG_ 980 LSS_Tastencode "0x00 = No key pressed / key released
0x01 = Menu
0x02 = Menu Up / Next Screen
0x03 = Menu Down / Previous Screen
0x04 = Up
0x05 = Down
0x06 = Up / Down ThumbWheel
0x07 = OK (ThumbWheel-Button)
0x08 = Cancel / Escape
0x09..0x0F = reserved for furt";
CM_ SG_ 980 SMLS_01_BZ "4bit Botschaftszaehler, wird mit jeder Sendebotschaft inkrementiert";
CM_ SG_ 980 SMLS_01_CRC "Für MLB:
'Berechnung siehe Lastenheft 'Kommunikationsabsicherung für FlexRay und CAN''

Ab MQB und MLBevo:
'Berechnung siehe Lastenheft 'End-to-End Kommunikationsabsicherung''

Endwerte siehe Begleitdokument 'S-PDU Kennungsfolgen'";
CM_ SG_ 980 SMLS_Hupe "Betaetigung Hupe
";
CM_ SG_ 980 SMLS_P_verriegelt "Signal stellt den Status des Signals P-verriegelt auf den Fahrzeugbus zur Verfügung. Nutzer sind z.B. die ELV, die das Signal für die Verriegelung benötigt und die Funktion Verlassenswarnung, die den Fahrer beim Verrollen des Fahrzeugs warnt.";
CM_ SG_ 980 SMLS_P_verriegelt_plausibel "Signal stellt den Plausibilisierungstatus des Signals p_verriegelt auf den Fahrzeugbus zur Verfügung. Eine Plausibilität muss explizit erkannt werden. Initial wird 'unplausibel' gesendet. Ein plausibles Signal wird erkannt, wenn p_verriegelt plausibel geg";
CM_ SG_ 980 SMLS_PTT "Betaetigung PTT";
CM_ SG_ 980 WH_Frontwaschen "Wischerhebel: Stellung Wisch Wasch vorne
";
CM_ SG_ 980 WH_Heckintervall "Wischerhebel: Stellung Heckintervall
";
CM_ SG_ 980 WH_Heckwaschen "Wischerhebel: Stellung Wisch Wasch hinten
";
CM_ SG_ 980 WH_Intervall "Wischerhebel: Stellung Intervall
";
CM_ SG_ 980 WH_Intervallstufen "Wischerhebel: Stellung Intervallstufen";
CM_ SG_ 980 WH_SRA "Scheinwerferreinigungsanlage

derzeit nur bei PAG umgesetzt";
CM_ SG_ 980 WH_Tipwischen "Wischerhebel: Tippwischen

MQB A0/ PQ26: Bei Verbau LSS (kein SMLS): gespiegelter Wert zu Signal WH_WischerStufe1";
CM_ SG_ 980 WH_Tipwischen_lang "Wischerhebel: Tippwischen lang
(dient zur Auswertung für die Unterscheidung Tippwischen oder Serviceposition Wischer)";
CM_ SG_ 980 WH_Wischer_Fehler "Anzeige, ob am Lenkstockschalter ein Fehler anliegt.
Notwendig aufgrund ASIL-Einstufung";
CM_ SG_ 980 WH_WischerStufe1 "Wischerhebel: Stufe Wischen 1
";
CM_ SG_ 980 WH_WischerStufe2 "Wischerhebel: Stufe Wischen 2
";

CM_ SG_ 2589283756 SOK_ungeschuetzte_Zeit "Periodisch verschickter SOK Zeitwert des SOK Zeitmasters als Referenzzeit zur Erkennung von Clockjitter durch andere SOK Teilnehmer.

Der Empfang dieses Signals ist verpflichtend für jedes Steuergerät, das durch die authentische Broadcast Funktionalität";

CM_ SG_ 2464153724 SOK_Zeit_EMotor_01_Challenge "Triebstrang GEN challenge";

CM_ SG_ 2464284796 SOK_Zeit_EMotor_01_Signatur "SOK_Time_TSGEN_Signature";
CM_ SG_ 2464284796 SOK_Zeit_EMotor_01_Zeit "Response signal of SOK time server to challenge of an SOK participant, containing SOK time";

CM_ SG_ 2464153784 SOK_Zeit_EMotor_02_Challenge "Challenge of SOK participant LE_V_VR to SOK time server for requesting authentic SOK time";

CM_ SG_ 2464284856 SOK_Zeit_EMotor_02_Signatur "Signature to protect authentic SOK time";
CM_ SG_ 2464284856 SOK_Zeit_EMotor_02_Zeit "Response signal of SOK time server to challenge of an SOK participant, containing SOK time";

CM_ SG_ 2464153719 SOK_Zeit_Getriebe_01_Challenge "SOK_Zeit_Getriebe_01_Challenge";

CM_ SG_ 2464284791 SOK_Zeit_Getriebe_01_Signatur "SOK_Zeit_Getriebe_01_Signatur";
CM_ SG_ 2464284791 SOK_Zeit_Getriebe_01_Zeit "SOK_Zeit_Getriebe_01_Zeit";

CM_ SG_ 2464153913 SOK_Zeit_LCU_SMH_Challenge "Challenge im Rahmen des SOK Challenge-Response Protokolls.

Geschützte Funktion: Empfang der SOK-Zeit vom SOK-Zeitmaster; verbindlich für Steuergeräte, welche mit der durch SOK geschützten Broadcast Nachrichten empfangen oder versenden";

CM_ SG_ 2464284985 SOK_Zeit_LCU_SMH_Signatur "Signatur im Rahmen des SOK Challenge-Response Protokolls.

Geschützte Funktion: Empfang der SOK-Zeit vom SOK-Zeitmaster; verbindlich für Steuergeräte, welche mit der durch SOK geschützten Broadcast Nachrichten empfangen oder versenden";
CM_ SG_ 2464284985 SOK_Zeit_LCU_SMH_Zeit "Aktueller Wert der SOK-Zeit des SOK-Zeitmasters; geschützt durch das SOK Challenge-Response Protokoll";

CM_ SG_ 2464157814 SOK_Zeit_MO_01_Challenge "Challenge im Rahmen des SOK Challenge-Response Protokolls.

Geschützte Funktion: Empfang der SOK-Zeit vom SOK-Zeitmaster; verbindlich für Steuergeräte, welche mit der durch SOK geschützten Broadcast Nachrichten empfangen oder versenden";

CM_ SG_ 2464288886 SOK_Zeit_MO_01_Signatur "SOK_Time_VKM_Signature";
CM_ SG_ 2464288886 SOK_Zeit_MO_01_Zeit "Aktueller Wert der SOK-Zeit des SOK-Zeitmasters; geschützt durch das SOK Challenge-Response Protokoll";

CM_ SG_ 2464153733 SOK_Zeit_RSG_Challenge "Challenge im Rahmen des SOK Challenge-Response Protokolls.

Geschützte Funktion: Empfang der SOK-Zeit vom SOK-Zeitmaster; verbindlich für Steuergeräte, welche mit der durch SOK geschützten Broadcast Nachrichten empfangen oder versenden";

CM_ SG_ 2464284805 SOK_Zeit_RSG_Signatur "Signatur im Rahmen des SOK Challenge-Response Protokolls.

Geschützte Funktion: Empfang der SOK-Zeit vom SOK-Zeitmaster; verbindlich für Steuergeräte, welche mit der durch SOK geschützten Broadcast Nachrichten empfangen oder versenden";
CM_ SG_ 2464284805 SOK_Zeit_RSG_Zeit "Aktueller Wert der SOK-Zeit des SOK-Zeitmasters; geschützt durch das SOK Challenge-Response Protokoll";

CM_ SG_ 1313 STH_EKP_Anst "STH sendet die Anforderung zur Ansteuerung der EKP an den Motor, um Kraftstoffbehälter der STH zu befüllen.";
CM_ SG_ 1313 STH_Fehler_ElWaPu "Fehler der el. Zusatzwasserpumpe der zur Deaktivierung der Wasserpumpe führt ";
CM_ SG_ 1313 STH_Fehlerstatus "Übermittlung der unterschiedlichen Fehlerzustände der Standheizung";
CM_ SG_ 1313 STH_Funk_aus "Funkbefehl über Funkfernbedienung zum Ausschalten Standheizung";
CM_ SG_ 1313 STH_Funk_ein "Funkbefehl über Funkfernbedienung zum Einschalten Standheizung";
CM_ SG_ 1313 STH_Geblaese "Ein-/ Ausschaltbefehl an die Klimaanlage, Gebläse";
CM_ SG_ 1313 STH_Heizleistung "Heizleistung in %";
CM_ SG_ 1313 STH_KL_HUP "Signal HUP Aktivierung an Klima

0 = HUP aus
1 = HUP ein";
CM_ SG_ 1313 STH_KVS "Kraftstoffverbrauch";
CM_ SG_ 1313 STH_KVS_Ueberlauf "Kraftstoffverbrauch, Überlauf hat stattgefunden";
CM_ SG_ 1313 STH_LED "Funktionslampe";
CM_ SG_ 1313 STH_Motorvorwaermung "Info an der Motor, dass der Aufheizvorgang mit Motorvorwärmung erfolgt ist";
CM_ SG_ 1313 STH_Pumpen_Anf_extern "Anforderung der motorseitigen elektr. (externen) Wasserpumpe zur Kreislaufunterstützung im Standheizbetrieb";
CM_ SG_ 1313 STH_Servicemode "Rückmeldung, dass die Standheizung sich gerade im Diagnosemodus befindet, gestartet über Diagnosetester";
CM_ SG_ 1313 STH_SH_ZH "0 = Heizgerät ist Standheizung
1 = Heizgerät ist Zuheizer
Gerätekennung WZH oder ZH
";
CM_ SG_ 1313 STH_Start_folgt "Thema Start/Stop: Im Stop-Modus muß das KBT einen Wiederstart anfordern, da ein STH-Start notwendig ist.";
CM_ SG_ 1313 STH_Texte "Anforderung der unterschiedlichen Anzeigetexte im Mitteldisplay des Kombi.

0: Keine Anzeige
1: Kein Standheizungs- bzw Lueftungsbetrieb wegen Batteriemanagementeinschraenkung
2: Kein Standheizungs- bzw Lueftungsbetrieb wegen Kraftstoffmangels
3: Kei";
CM_ SG_ 1313 STH_Ventil_Status "Statusrückmeldung Ansteuerung 3/2 Wege-Ventil";
CM_ SG_ 1313 STH_Ventiloeffnungszeit "Die Standheizung sendet an den Motor die Information darüber wie lange das Magnetventil die Wasserkreisläufe von 'klein' aus 'gross' geschaltet hat. ";
CM_ SG_ 1313 STH_Waermeeintrag "Signal enthält die Brenndauer in 1min-Schritten, über welche die Standheizung gelaufen ist";
CM_ SG_ 1313 STH_war_aktiv "Bit beeinhaltet die Info, dass die Standheizung während der letzten halbe Stunde aktiv war.";
CM_ SG_ 1313 STH_Wassertemp "Kühlmitteltemperatur der Standheizung";
CM_ SG_ 1313 STH_Zusatzheizung "Kraftstoffzuheizer aktiv";

CM_ SG_ 1413 GW_KD_Fehler "Kundendienstfehlerbit Gateway zur Anzeige eines im Gateway abgelegten Fehlerspeichereintrages.";
CM_ SG_ 1413 SI_BUS_01 "MQB/MQB_A0/PQ26: ACAN
MQB2020: ACAN(FD)
MLBevo: HCAN
E3_Volumen: ACAN(FD)
MQBw_Baseline: ACAN(FD)";
CM_ SG_ 1413 SI_BUS_02 "MQB/MQB A0 Standard+, High: FCAN
MQB2020: FCAN(FD)
MLBevo: Frei
E3_Volumen: FCAN(FD)
MQBw_Baseline: FCAN(FD)";
CM_ SG_ 1413 SI_BUS_03 "MQB/MQB A0/PQ26: KCAN
MQB2020: KCAN
MLBevo: KCAN
E3_Volumen: KCAN(HS) / K2CAN(FD) (Buskopplung)
MQBw_Baseline: KCAN(HS)";
CM_ SG_ 1413 SI_BUS_04 "MQB/MQB A0 Standard+, High: ICAN
MQB2020: ICAN(HS)
MLBevo: ICAN
E3_Volumen: ABCAN(FD)
MQBw_Baseline: ICAN(HS)";
CM_ SG_ 1413 SI_BUS_05 "MQB/MQB A0/PQ26: DiagCAN
MQB2020: DiagCAN(FD)
MLBevo: DiagCAN
E3_Volumen: DiagCAN(FD)
MQBw_Baseline: DiagCAN(FD)";
CM_ SG_ 1413 SI_BUS_06 "MQB/MQB A0/PQ26: ECAN
MQB2020: FASCAN(FD)
MLBevo: ECAN
E3_Volumen: FASCAN_1(FD)
MQBw_Baseline: FASCAN_1(FD)";
CM_ SG_ 1413 SI_BUS_07 "MQB: LIN1 (Energie)
MQB2020: LIN1 (Energie)
MLBevo: LIN1 (Energie)
E3_Volumen: LIN 1 (Energie)
MQBw_Baseline: LIN1 (Energie)";
CM_ SG_ 1413 SI_BUS_08 "MQB: LIN2 (MFL)
MQB2020: LIN2 (MFL)
MLBevo: LIN2 (MFL)
E3_Volumen: LIN2 (MFL)
MQBw_Baseline: LIN2 (MFL)";
CM_ SG_ 1413 SI_BUS_09 "MQB: LIN3 (unbelegt)
MQB2020: LIN3 (Uhr/FES)
MLBevo: LIN3 (Energie2)
MEB: LIN3
E³ 1.1 UNECE: MDKCAN";
CM_ SG_ 1413 SI_BUS_10 "MLBevo: Flexray
MQB2020: MCAN
MQBw_Baseline: FASCAN_2(FD)
E³ 1.1 UNECE: FASCAN_2(FD)";
CM_ SG_ 1413 SI_BUS_11 "MLBevo: Ethernet
MEB: LIN4";
CM_ SG_ 1413 SI_BUS_12 "MQB: unbelegt
MLBevo: K2CAN
E3_Volumen: MFLCAN
MQBw_Baseline: K2CAN(FD)";
CM_ SG_ 1413 SI_BUS_13 "MQB: unbelegt
MLBevo: DCAN
MEB: CCAN
MQBw_Baseline: K3CAN(FD)";
CM_ SG_ 1413 SI_BUS_14 "MQB/MQB A0: unbelegt
MQB2020: HCAN
MLBevo: CCAN
E3_Volumen: EVCAN(FD)
MQBw_Baseline: EVCANFD(FD)";
CM_ SG_ 1413 SI_BUS_15 "MQB: frei
MQB2020: frei
MLBevo: frei
MEB: AFSCAN";
CM_ SG_ 1413 SI_Bus_Identifikation "Das Signal identifiziert den Bus eindeutig. Das Signal ist konstant auf jedem Bus.
Der Signalwert entspricht dem Wert 'Busnummer' aus der VW80127 Gateway_component_list_databus_identification (0x2A2D) 'Bus-Identifier'.";
CM_ SG_ 1413 SI_CAB_V14 "CAB = Clusteraktivbits (V14)";
CM_ SG_ 1413 SI_Diagnose_Aktiv "Gibt an ob Diagnose-Botschaften empfangen werden und somit eine Diagnose aktiv ist.
MQB: Gibt an ob Diagnose-Bus Botschaften empfangen werden und somit eine Diagnose aktiv ist.";
CM_ SG_ 1413 SI_NWDF "Netzwerk-Diagnose Freigebe zur zentralen Aktivierung der Netzwerkdiagnose";
CM_ SG_ 1413 SI_NWDF_30 "Netzwerk-Diagnose Freigabe zur zentralen Aktivierung der Netzwerkdiagnose (keine Ausblendbedingung aktiv)";
CM_ SG_ 1413 SI_NWDF_gueltig "Gültigkeitsbit zu SI_NWDF gemäß Lastenheft: Zentrale Aktivierung Netzwerkdiagnose";
CM_ SG_ 1413 SI_P_Mode "Zentrale Steuerung des Produktionsmodes gemäß Q-LAH-Produktionsmode (LAH.DUM.907.AS)";
CM_ SG_ 1413 SI_P_Mode_gueltig "zeigt an, ob es sich um ein Fahrzeug mit zentraler oder dezentraler Steu-erung des Produktionsmodes handelt
Siehe Q-LAH Produktionsmode (LAH.DUM.907.AS)";
CM_ SG_ 1413 SI_QRS_Mode "Messmodus Quick-Ruhestrom";
CM_ SG_ 1413 SI_Sammel_SG_Fehler "Anzahl der gesetzten KD-Fehler direkt angeschlossener Steuergeräte der DK3 und DK4 gemäß 80127.
Hinweis: Ein Subbusmaster stellt nur die gesammelte Information der an ihn angeschlossenen Steuergeräte der DK3 und DK4 zur Verfügung.

Für ServiceKey Auswe";
CM_ SG_ 1413 SI_Sammelfehler "Sammelfehlermeldung zur Anzeige im Kombi - siehe Spez. Sammelfehlermeldung
Hinweis: Einzelne Steuergeräte können zur Anpassung an den Produktionsprozess im Gateway auskodiert werden!";
CM_ SG_ 1413 SI_T_Mode "0x0: Transportmodus nicht aktiv
0x1: Transportmodus aktiv";
CM_ SG_ 1413 SI_T_Schutz "Transportschutz-Signal, das bei Transportmodus und Motorlauf aktiv bleibt
0x0: Transportschutz nicht aktiv
0x1: Transportschutz aktiv";

CM_ SG_ 2589283571 TLI_LSA1_Data_Age "Alter, der für die TLI-Berechnungen verwendeten Daten";
CM_ SG_ 2589283571 TLI_LSA1_Data_Source "Datenquelle, die für die TLI-Berechnung genutzt wird";
CM_ SG_ 2589283571 TLI_LSA1_Direction_E "Gibt an, ob das Manöver 'rechts abbiegen' an der relevanten Ampel erlaubt ist oder nicht";
CM_ SG_ 2589283571 TLI_LSA1_Direction_N "Gibt an, ob das Manöver 'geradeaus fahren' an der relevanten Ampel erlaubt ist oder nicht";
CM_ SG_ 2589283571 TLI_LSA1_Direction_NE "Gibt an, ob das Manöver 'leicht rechts abbiegen' an der relevanten Ampel erlaubt ist oder nicht";
CM_ SG_ 2589283571 TLI_LSA1_Direction_NW "Gibt an, ob das Manöver 'leicht links abbiegen' an der relevanten Ampel erlaubt ist oder nicht";
CM_ SG_ 2589283571 TLI_LSA1_Direction_SE "Gibt an, ob das Manöver 'scharf rechts abbiegen' an der relevanten Ampel erlaubt ist oder nicht";
CM_ SG_ 2589283571 TLI_LSA1_Direction_SW "Gibt an, ob das Manöver 'scharf links abbiegen' an der relevanten Ampel erlaubt ist oder nicht";
CM_ SG_ 2589283571 TLI_LSA1_Direction_U_Turn_NE "Gibt an, ob das Manöver 'U-Turn rechts' an der relevanten Ampel erlaubt ist oder nicht";
CM_ SG_ 2589283571 TLI_LSA1_Direction_U_Turn_NW "Gibt an, ob das Manöver 'U-Turn links' an der relevanten Ampel erlaubt ist oder nicht";
CM_ SG_ 2589283571 TLI_LSA1_Direction_W "Gibt an, ob das Manöver 'links abbiegen' an der relevanten Ampel erlaubt ist oder nicht";
CM_ SG_ 2589283571 TLI_LSA1_Distance_Backlog "Länge des Rückstau an der relevanten Ampel 

Hinweis: Die Länge bezeichnet die Entfernung von der Haltelinie der relevanten Ampel bis zum Ende des Rückstau. Bitte auch das Signal TLI_LSA1_Info_Backlog beachten.";
CM_ SG_ 2589283571 TLI_LSA1_Distance_Stop_Line "Entfernung des Ego-Fahrzeuges zur Haltelinie der relevanten Ampel";
CM_ SG_ 2589283571 TLI_LSA1_GLOSA "Optimale Annäherungsgeschwindigkeit (GLOSA) für die relevante Ampel 

Hinweis: Signal TLI_LSA1_GLOSA_Unit beachten.";
CM_ SG_ 2589283571 TLI_LSA1_GLOSA_Display "Optimale Annäherungsgeschwindigkeit (GLOSA) für die relevante Ampel 

Hinweis: Das Signal dient zur Anzeige der optimalen Annähreungsgeschwindigkeit für den Kunden und enthält eine Begrenzung auf die maximal gültige Höchstgeschwindigkeit. Signal TLI_LSA";
CM_ SG_ 2589283571 TLI_LSA1_GLOSA_Unit "Einheit der optimalen Annäherungsgeschwindigkeit (GLOSA) für die relevante Ampel

Hinweis: Signal TLI_LSA1_GLOSA beachten";
CM_ SG_ 2589283571 TLI_LSA1_Info_Backlog "Information über einen Rückstau an der relevanten Ampel

Hinweis: Länge des Rückstau ist dem Signal TLI_LSA1_Distance_Backlog zu entnehmen";
CM_ SG_ 2589283571 TLI_LSA1_TTG "Restrotzeit an der relevanten Ampel";

CM_ SG_ 2589283622 TLO_01_Zaehler "Zaehler wird inkrementiert, wenn sich die Zuordnung zu den Signalgruppen aendert.
z.B. Neuer MPP, Kreuzungsueberfahrt, neuer AIO Pfad";
CM_ SG_ 2589283622 TLO_HMI_Status "Aktueller Anzeigestatus";
CM_ SG_ 2589283622 TLO_LSA1_PSD_Seg_Offset "Offset auf PSD Segment";
CM_ SG_ 2589283622 TLO_LSA1_PSD_Segment_ID "PSD Segment ID auf den die Haltelinie verortet wurde";
CM_ SG_ 2589283622 TLO_LSA1_Zeit1_CF "Güte der prädizierten LSA1 Zeit1";
CM_ SG_ 2589283622 TLO_LSA1_Zeit1_Pred "Prädizierte LSA1 Zeit1";
CM_ SG_ 2589283622 TLO_LSA1_Zeit1_Status "Status der aktuellen LSA1 Zeit1";
CM_ SG_ 2589283622 TLO_LSA1_Zeit2_CF "Güte der prädizierten LSA1 Zeit2";
CM_ SG_ 2589283622 TLO_LSA1_Zeit2_Pred "Prädizierte LSA1 Zeit2";
CM_ SG_ 2589283622 TLO_LSA1_Zeit2_Status "Status der aktuellen LSA1 Zeit2";
CM_ SG_ 2589283622 TLO_StartStoppInfo "Stopp-Freigabe und Start-Anforderung an den Start-Stopp-Koordinator";

CM_ SG_ 2589283623 TLO_02_Zaehler "Zaehler wird inkrementiert, wenn sich die Zuordnung zu den Signalgruppen aendert.
z.B. Neuer MPP, Kreuzungsueberfahrt, neuer AIO Pfad";
CM_ SG_ 2589283623 TLO_LSA1_Layout "Ampelausrichtung für die Ampel, auf die man zufährt (Schaltzeiten in TLO_01).";
CM_ SG_ 2589283623 TLO_LSA2_PSD_Seg_Offset "Offset auf PSD Segment";
CM_ SG_ 2589283623 TLO_LSA2_PSD_Segment_ID "PSD Segment ID auf den die Haltelinie verortet wurde";
CM_ SG_ 2589283623 TLO_LSA2_Zeit1_CF "Güte der prädizierten LSA2 Zeit1";
CM_ SG_ 2589283623 TLO_LSA2_Zeit1_Pred "Prädizierte LSA2 Zeit1";
CM_ SG_ 2589283623 TLO_LSA2_Zeit1_Status "Status der aktuellen LSA2 Zeit1";
CM_ SG_ 2589283623 TLO_LSA2_Zeit2_CF "Güte der prädizierten LSA2 Zeit2";
CM_ SG_ 2589283623 TLO_LSA2_Zeit2_Pred "Prädizierte LSA2 Zeit2";
CM_ SG_ 2589283623 TLO_LSA2_Zeit2_Status "Status der aktuellen LSA2 Zeit2";

CM_ SG_ 1447 bCall_active "1: Breakdown call is active
0: BreakdownCall is inactive";
CM_ SG_ 1447 eCall_Funktionsstatus "HMI-Aufruf im Kombi (Broadcast)
Fehlerfälle die im Kombi angezeigt werden können";
CM_ SG_ 1447 eCall_Funktionsstatus_02 "Erweiterung des Funktionsstatus für andere Funktionen
ACN aktiv, MEC aktiv
MEC = manual emergency call = maueller Notruf
ACN = automatic emergency call = automatischer Notruf";
CM_ SG_ 1447 eCall_MCC "Mobile Country Code of the current mobile network
ITU-T E.212";
CM_ SG_ 1447 eCall_Mute_Anf "Signalisiert die Aufforderungen alle Soundquellen im Fahrzeug während eines aktiven Notrufs zu muten";
CM_ SG_ 1447 FaceRec_Enroll_Challenge_Request "When FaceRec on MIK receives this signal it will provide a challenge via SOK_FR_Enroll_MIK_Challenge.";
CM_ SG_ 1447 FoD_Anz_Funktionsabschaltung "Signal triggert Aufschaltung eines Popups, um dem Fahrer die Abschaltung einer Funktion zu melden.";
CM_ SG_ 1447 iCall_active "Statusrückmeldung von OCU über Infocall aktiv/inaktiv";
CM_ SG_ 1447 MOD_Energie_Anf "Anforderung Energieversorgung MOD-Job an das NVEM";
CM_ SG_ 1447 MOD_Request_ServiceKey "Sendet ein Signal zum ServiceKey-Master, welcher daraufhin einen aktuellen ServiceKey1c auf den Bus legt.";
CM_ SG_ 1447 ORU_KombiTimer "Ankündigung eines ORU OCU zum Kombi zur Darstellung entsprechender Symbole";
CM_ SG_ 1447 TM_Door_Lock "Remote Door lock angefordert: ZV zu/verriegeln";
CM_ SG_ 1447 TM_Door_Unlock "Remote Door unlock angefordert: ZV auf/entriegeln";
CM_ SG_ 1447 TM_Nur_Hupen "Remote Hupen (ohne Blinken) aktiviert";
CM_ SG_ 1447 TM_Panik_Alarm "Remote Hupen und Blinken aktiv";
CM_ SG_ 1447 TM_Spiegel_Anklappen "Anklappen der Außenspiegel über Remote MOD Anforderung";
CM_ SG_ 1447 TM_Warnblinken "Remote Blinken aktiviert";
CM_ SG_ 1447 TM_ZV_Signatur "Gespeicherte Signatur der ZV für Authentifizierung";

CM_ SG_ 976 ASW_HMI_defekt "HMI Status der Funktion AusstiegsWarnung (ASW). HMI wird durch das TSG angesteuert.";
CM_ SG_ 976 ASW_wakeup "Trigger Start Nachlaufzeit t_1 für die Funktion Ausstieswarnung (ASW)";
CM_ SG_ 976 ASW_Warnung_aktiv_FS "Abschaltung der Ambientefunktion Fahrertür bei aktiver ASW Warnung an der Fahrertür";
CM_ SG_ 976 FS_Status_eTAG "Status des elektrischen Tueraussengriffes Fahrertuer";
CM_ SG_ 976 FT_BFS_Fond_Freigabe "Freigabe für Fondverstellung";
CM_ SG_ 976 FT_Daemmglas "Daemmglas verbaut";
CM_ SG_ 976 FT_FH_Bew_hoch "Fensterheber in Bewegung Richtung hoch";
CM_ SG_ 976 FT_FH_Bew_tief "Fensterheber in Bewegung Richtung tief";
CM_ SG_ 976 FT_FH_Block "Fensterscheibe befindet sich im mechanischen Block (oben oder unten)";
CM_ SG_ 976 FT_FH_Fang "Fangbereich ist 4mm von oberer Lippendichtung";
CM_ SG_ 976 FT_FH_normiert "Die Position der Fensterheberscheibe ist bekannt";
CM_ SG_ 976 FT_FH_Oeffnung "Gibt den Fensteröffnungswert in % an.";
CM_ SG_ 976 FT_FH_S_AutoHoch "FH Schalter automatisch hoch gedrückt";
CM_ SG_ 976 FT_FH_S_AutoTief "FH Schalter automatisch tief gedrückt";
CM_ SG_ 976 FT_FH_S_ManHoch "FH Schalter manuell hoch gedrückt";
CM_ SG_ 976 FT_FH_S_ManTief "FH Schalter manuell tief gedrückt";
CM_ SG_ 976 FT_FH_Thermo "gibt an ob Fensterheber im Thermoschutz ist";
CM_ SG_ 976 FT_gesafet "Im Zustand Safe wird auch das Signal FT_verriegelt = 1 gesendet";
CM_ SG_ 976 FT_HD_Taste "Taste in der Fahrertür zum Öffnen des Heckschlosses";
CM_ SG_ 976 FT_HD_Taste_2 "2. HD-Taste im Bedienfeld 
Funktion: Heckdeckel schließen";
CM_ SG_ 976 FT_IRUE_Taste "Betätigung IRUE-Taster (Innenraumüberwachung)
MQB: Bei Verbau eines einzelnen Taster zur Deaktivierung von IRUE und NGS wird dieses Signal als Deaktivierungsanforderung beider DWA-Alarmquellen gesendet.";
CM_ SG_ 976 FT_Kisi_Fehler "Fehlerstatus Kindersicherungsfunktion";
CM_ SG_ 976 FT_Kisi_li_aktiv "Aktivierungsstatus der Kindersicherung links";
CM_ SG_ 976 FT_Kisi_re_aktiv "Aktivierungsstatus der Kindersicherung rechts";
CM_ SG_ 976 FT_Kisi_Taster_li "Linker Kisi Taster betaetigt";
CM_ SG_ 976 FT_Kisi_Taster_re "Rechter Kisi Taster betaetigt";
CM_ SG_ 976 FT_Lock_Taster "Verriegelungstaster betätigt";
CM_ SG_ 976 FT_Lock_Unlock_Taster "ZV Funktion Lock Unlock mit Toggle-Logik";
CM_ SG_ 976 FT_Oben_Block_erw "Fensterheber in Blockerwartung oben";
CM_ SG_ 976 FT_Schliesstaster "Vorhalt";
CM_ SG_ 976 FT_Schluesselschalter_auf "Schlüsselschalter Richtung auf betätigt";
CM_ SG_ 976 FT_SP_ausgerastet "Spiegel ausgerastet";
CM_ SG_ 976 FT_Sp_Blk_def "Blinker am Spiegel defekt";
CM_ SG_ 976 FT_Sp_Heizung_Anf "Kundenanforderung der Außenspiegelheizung Fahrertür";
CM_ SG_ 976 FT_SP_Heizung_Status "Status der Spiegelheizung";
CM_ SG_ 976 FT_SP_ht_aktiv "Spiegelverstellung in Richtung hoch/tief aktiv";
CM_ SG_ 976 FT_SP_lr_aktiv "Spiegelverstellung in Richtung links/rechts aktiv";
CM_ SG_ 976 FT_Sperrklinke "Vorraste für Schloß

zwischen Vor- und Hauptraste Signal kurz auf 1, danach wieder auf 0 wenn Tür in Hauptraste (Tür ist sicher zu wenn Sperrklinke und Türkontakt auf 0 sind)";
CM_ SG_ 976 FT_SWA_Taster "SWA/ASW Taster Fahrertür";
CM_ SG_ 976 FT_TAG_betaetigt "Türaussengriff

wird nicht im MLB-B8 verwendet";
CM_ SG_ 976 FT_TD_Taste "Tankdeckelentriegelungs-Taste betätigt";
CM_ SG_ 976 FT_TD_Taste_Fehler "Fehlerstatus des Tankdeckelentriegelungstasters. Wird bei Drucktankkonzepten vom MSG zusammen mit dem Signal FT_TD_Taste ausgewertet, um Tankbereitschaft herzustellen.
Der Fehler beschreibt einen hängenden TD_Taster. Ein Kurzschluss oder Leitungsunterbre";
CM_ SG_ 976 FT_TIG_betaetigt "Türinnengriff

wird nicht im MLB-B8 verwendet";
CM_ SG_ 976 FT_Tuer_geoeffnet "Zeigt eine geöffnete Tür an";
CM_ SG_ 976 FT_Tuerschloss_defekt "Das Fahrertürschloss ist nicht mehr funktionsfähig.";
CM_ SG_ 976 FT_UEKB_aktiviert "Überschutzbegrenzungskraft bei Reversieren";
CM_ SG_ 976 FT_Unlock_Taster "Entriegelungstaster betätigt";
CM_ SG_ 976 FT_Unten_Block_erw "Fensterheber in Blockerwartung unten";
CM_ SG_ 976 FT_verriegelt "Zeigt eine verriegelte Tür an ( Status wird erst nach vollständiger Schlossansteuerung ausgegeben (<=1,5sek))";
CM_ SG_ 976 FT_Zuziehhilfe_aktiv "Zuziehhilfe aktiv";
CM_ SG_ 976 SSR_Temp_Freigabe "Freigabe des Seitenscheibenrollos. Bit wird  für die Deaktivierung des SSR bei Innenraumtemperaturen kleiner -10 Grad verwendet.";
CM_ SG_ 976 SWA_HMI_Diagnose "SWA HMI Diagnose beim TSG";

CM_ SG_ 997 eTAB_FS_Bowdenzug_Auswerfen "Soll den Bowdenzug für die mechanische Redundanz";
CM_ SG_ 997 FS_Push_Tuergriff "Push zum Ausfahren der Flush-Tuergriffe";
CM_ SG_ 997 FS_Status_eTAG_ext "erweitert um den Wert 'verfährt'";
CM_ SG_ 997 FT_ASW_Warnton "erzeugt ein Warnton bei AS Warnung";
CM_ SG_ 997 FT_BFS_Tuer_Status "Gesammelte Türstatusbotschaft";
CM_ SG_ 997 FT_Cargolock_bet "CargoLock-Taste betätigt";
CM_ SG_ 997 FT_HBFS_Tuer_Status "Türstatus mit Fehler und Initwert";
CM_ SG_ 997 FT_HFS_Tuer_Status "Türstatus mit Fehler und Initwert";
CM_ SG_ 997 FT_kisi_asynchron "Signal erzeugt eine seperate Warnmeldung bei ungewollter Asynchronität der 'elektrische Kindersicherung' der Schlösser.";
CM_ SG_ 997 FT_KiSi_Status_Soll_HBFS "Soll KiSi Status HBFS";
CM_ SG_ 997 FT_KiSi_Status_Soll_HFS "Soll Status der KiSi HFS";
CM_ SG_ 997 FT_Kisi_Taster_li_02 "Der Kindersicherungstaster hinten links aktiv.";
CM_ SG_ 997 FT_Kisi_Taster_re_02 "Der Kindersicherungstaster hinten rechts aktiv.";
CM_ SG_ 997 FT_Lock_Taster_02 "Lock-Taster betätigt";
CM_ SG_ 997 FT_Schluesselschalter_zu_02 "Schlüsselschalter für Schließen betätigt";
CM_ SG_ 997 FT_SP_Heizung_ein "Dieses Signal zeigt die tatsächliche Ansteuerung der  Spiegelheizung incl. PWM an. 
Zudem wird aufgrund des Teilnetzbetriebs das Signal zur Ansteuerung der Beifahrer-Spiegelheizung benutzt.

";
CM_ SG_ 997 FT_TCR_Mode_aktiv "Signal zeigt eine aktive mechanische Redundanz am Türschloss an.";
CM_ SG_ 997 FT_TD_Taste_Status "Status Taste für Tankdeckel";
CM_ SG_ 997 FT_Tuer_Status "Tür geöffnet oder Tür geschlossen";
CM_ SG_ 997 FT_Tuer_Status_QBit "Dieses Bit gibt die Zuverlässigkeit des Türkontakts an. Ein auf dieses Bit folgender Fehlereintrag ist mit dem Sender des Bits abzustimmen (gültig ab PPE).";
CM_ SG_ 997 FT_Tueroeffnen_Warnung "Bit wird gesetzt, wenn Tür während der Fahrt geoeffnet werden soll.";
CM_ SG_ 997 SSA_FT_ASW_Status "SmartSensorActor:
Rückmeldung des Status der ASW Anzeige.";
CM_ SG_ 997 TBF_FS_Touch_Event "Touch_Events für Informationen einer Funktionsauslösung auf dem TBF, welche dann für bspw. ein akustisches Signal zentral umgesetzt werden können.";
CM_ SG_ 997 TSG_FS_Spiegel_angeklappt "Funktionsrückmeldung TSG_FS über Spiegelstellung angeklappt";
CM_ SG_ 997 TSG_FT_02_BZ "4bit Botschaftszaehler, wird mit jeder Sendebotschaft inkrementiert";
CM_ SG_ 997 TSG_FT_02_CRC "Für MLB:
'Berechnung siehe Lastenheft 'Kommunikationsabsicherung für FlexRay und CAN''

Ab MQB und MLBevo:
'Berechnung siehe Lastenheft 'End-to-End Kommunikationsabsicherung''

Endwerte siehe Begleitdokument 'S-PDU Kennungsfolgen'";

CM_ SG_ 2589283396 TSK_vMax_EfficiencyMode1 "Globales Limit im Effizienz1 Fahrprofil/ Fahrmodus (e.g. 'ECO').";
CM_ SG_ 2589283396 TSK_vMax_EfficiencyMode2 "Globales Limit im Efficiency 2 Fahrprofil/ Fahrprogramm (e.g. 'ECO+' oder 'Range plus').";
CM_ SG_ 2589283396 TSK_vMax_StandardMode "Globales Limit im Standard Fahrprofil/ Fahrprogramm Modus (e.g. 'normal' oder 'comfort').";

CM_ SG_ 1019 TSK_Ausrollkurve_Mux "Dieses Signal dient als Multiplexzähler für die Segel- bzw. Schub-/RekuAusrollkurve";
CM_ SG_ 1019 TSK_Ausrollkurve_Reku "Dieses Signal zeigt an, ob bei der Schub-/Rekuausrollkurve aktuell Rekuperation berücksichtigt wird.";
CM_ SG_ 1019 TSK_Ausrollkurve_Schrittweite "Dieses Signal dient dient zur Umschaltung der Stützstellenschrittweite der Segel- bzw. Schub-/Rekuausrollkurve";
CM_ SG_ 1019 TSK_Ausrollkurve_Schub_Reku_01 "Dieses Signal sendet die Stützstelle 1 der Schub-/Rekuausrollkurve.";
CM_ SG_ 1019 TSK_Ausrollkurve_Schub_Reku_02 "Dieses Signal sendet die Stützstelle 2 der Schub-/Rekuausrollkurve.";
CM_ SG_ 1019 TSK_Ausrollkurve_Schub_Reku_03 "Dieses Signal sendet die Stützstelle 3 der Schub-/Rekuausrollkurve.";
CM_ SG_ 1019 TSK_Ausrollkurve_Schub_Reku_04 "Dieses Signal sendet die Stützstelle 4 der Schub-/Rekuausrollkurve.";
CM_ SG_ 1019 TSK_Ausrollkurve_Schub_Reku_05 "Dieses Signal sendet die Stützstelle 5 der Schub-/Rekuausrollkurve.";
CM_ SG_ 1019 TSK_Ausrollkurve_Schub_Reku_06 "Dieses Signal sendet die Stützstelle 6 der Schub-/Rekuausrollkurve.";
CM_ SG_ 1019 TSK_Ausrollkurve_Schub_Reku_07 "Dieses Signal sendet die Stützstelle 7 der Schub-/Rekuausrollkurve.";
CM_ SG_ 1019 TSK_Ausrollkurve_Schub_Reku_08 "Dieses Signal sendet die Stützstelle 8 der Schub-/Rekuausrollkurve.";
CM_ SG_ 1019 TSK_Ausrollkurve_Schub_Reku_09 "Dieses Signal sendet die Stützstelle 9 der Schub-/Rekuausrollkurve.";
CM_ SG_ 1019 TSK_Ausrollkurve_Schub_Reku_10 "Dieses Signal sendet die Stützstelle 10 der Schub-/Rekuausrollkurve.";
CM_ SG_ 1019 TSK_Ausrollkurve_Schub_Reku_11 "Dieses Signal sendet die Stützstelle 11 der Schub-/Rekuausrollkurve.";
CM_ SG_ 1019 TSK_Ausrollkurve_Schub_Reku_12 "Dieses Signal sendet die Stützstelle 12 der Schub-/Rekuausrollkurve.";
CM_ SG_ 1019 TSK_Ausrollkurve_Schub_Reku_13 "Dieses Signal sendet die Stützstelle 13 der Schub-/Rekuausrollkurve.";
CM_ SG_ 1019 TSK_Ausrollkurve_Schub_Reku_14 "Dieses Signal sendet die Stützstelle 14 der Schub-/Rekuausrollkurve.";
CM_ SG_ 1019 TSK_Ausrollkurve_Schub_Reku_15 "Dieses Signal sendet die Stützstelle 15 der Schub-/Rekuausrollkurve.";
CM_ SG_ 1019 TSK_Ausrollkurve_Schub_Reku_16 "Dieses Signal sendet die Stützstelle 16 der Schub-/Rekuausrollkurve.";
CM_ SG_ 1019 TSK_Ausrollkurve_Schub_Reku_17 "Dieses Signal sendet die Stützstelle 17 der Schub-/Rekuausrollkurve.";
CM_ SG_ 1019 TSK_Ausrollkurve_Schub_Reku_18 "Dieses Signal sendet die Stützstelle 18 der Schub-/Rekuausrollkurve.";
CM_ SG_ 1019 TSK_Ausrollkurve_Schub_Reku_19 "Dieses Signal sendet die Stützstelle 19 der Schub-/Rekuausrollkurve.";
CM_ SG_ 1019 TSK_Ausrollkurve_Schub_Reku_20 "Dieses Signal sendet die Stützstelle 20 der Schub-/Rekuausrollkurve.";
CM_ SG_ 1019 TSK_Ausrollkurve_Segeln_01 "Dieses Signal sendet die Stützstelle 1 der Segelausrollkurve.";
CM_ SG_ 1019 TSK_Ausrollkurve_Segeln_02 "Dieses Signal sendet die Stützstelle 2 der Segelausrollkurve.";
CM_ SG_ 1019 TSK_Ausrollkurve_Segeln_03 "Dieses Signal sendet die Stützstelle 3 der Segelausrollkurve.";
CM_ SG_ 1019 TSK_Ausrollkurve_Segeln_04 "Dieses Signal sendet die Stützstelle 4 der Segelausrollkurve.";
CM_ SG_ 1019 TSK_Ausrollkurve_Segeln_05 "Dieses Signal sendet die Stützstelle 5 der Segelausrollkurve.";
CM_ SG_ 1019 TSK_Ausrollkurve_Segeln_06 "Dieses Signal sendet die Stützstelle 6 der Segelausrollkurve.";
CM_ SG_ 1019 TSK_Ausrollkurve_Segeln_07 "Dieses Signal sendet die Stützstelle 7 der Segelausrollkurve.";
CM_ SG_ 1019 TSK_Ausrollkurve_Segeln_08 "Dieses Signal sendet die Stützstelle 8 der Segelausrollkurve.";
CM_ SG_ 1019 TSK_Ausrollkurve_Segeln_09 "Dieses Signal sendet die Stützstelle 9 der Segelausrollkurve.";
CM_ SG_ 1019 TSK_Ausrollkurve_Segeln_10 "Dieses Signal sendet die Stützstelle 10 der Segelausrollkurve.";
CM_ SG_ 1019 TSK_Ausrollkurve_Segeln_11 "Dieses Signal sendet die Stützstelle 11 der Segelausrollkurve.";
CM_ SG_ 1019 TSK_Ausrollkurve_Segeln_12 "Dieses Signal sendet die Stützstelle 12 der Segelausrollkurve.";
CM_ SG_ 1019 TSK_Ausrollkurve_Segeln_13 "Dieses Signal sendet die Stützstelle 13 der Segelausrollkurve.";
CM_ SG_ 1019 TSK_Ausrollkurve_Segeln_14 "Dieses Signal sendet die Stützstelle 14 der Segelausrollkurve.";
CM_ SG_ 1019 TSK_Ausrollkurve_Segeln_15 "Dieses Signal sendet die Stützstelle 15 der Segelausrollkurve.";
CM_ SG_ 1019 TSK_Ausrollkurve_Segeln_16 "Dieses Signal sendet die Stützstelle 16 der Segelausrollkurve.";
CM_ SG_ 1019 TSK_Ausrollkurve_Segeln_17 "Dieses Signal sendet die Stützstelle 17 der Segelausrollkurve.";
CM_ SG_ 1019 TSK_Ausrollkurve_Segeln_18 "Dieses Signal sendet die Stützstelle 18 der Segelausrollkurve.";
CM_ SG_ 1019 TSK_Ausrollkurve_Segeln_19 "Dieses Signal sendet die Stützstelle 19 der Segelausrollkurve.";
CM_ SG_ 1019 TSK_Ausrollkurve_Segeln_20 "Dieses Signal sendet die Stützstelle 20 der Segelausrollkurve.";
CM_ SG_ 1019 TSK_Ausrollkurve_Zaehler "Dieses Signal ermöglicht die Unterscheidung der Ausrollkurven. Es wird nach der vollständigen Übertragung einer Kennlinie inkrementiert.";

CM_ SG_ 2463978710 OPS_ComfortReadyStatus "Das Signal wird durch den Basisdienst User State Server (Technikvariante: OccupantPresenceService) erzeugt und bildet einen neuen Zustand, bestehend aus einer Verknüpfung der Fahreranwesenheit (Fahrer abwesend / Fahrer anwesend) und der Klemmensteuerung (";
CM_ SG_ 2463978710 OPS_DriverPresenceStatus "Das Signal wird durch den Basisdienst User State Server (Service: OccupantPresenceService) erzeugt und bildet die Fahrerzustände im Fahrzeug ab.";
CM_ SG_ 2463978710 OPS_OccupantPresenceStatus "Das Signal wird durch den Basisdienst User State Server (Service: OccupantPresenceService) erzeugt und bildet die Anwesenheit und Abwesenheit aller Insassen im Fahrzeug ab.";
CM_ SG_ 2463978710 OPS_QBit_DriverPresence "Das Signal wird durch den Basisdienst User State Server (Service: OccupantPresenceService) erzeugt und signalisiert die Qualität der Fahrerzustände.";
CM_ SG_ 2463978710 OPS_SafeDriverPresence_available "Das Signal signalisiert inwiefern alle vorgesehene Sensoren  für die Anwesenheit verwendet werden oder möglichweise bestimmte Sensoren nicht verfügbar sind.
In beiden Fällen wird eine Anwesenheit berechnet, jedoch bei Ausfall bestimmter Sensoren kann zu ";
CM_ SG_ 2463978710 OPS_SafeDriverPresenceStatus "Signalisierung einer sicheren Fahreranwesenheit nach ASIL B";
CM_ SG_ 2463978710 UserStateServer_01_BZ "4bit Botschaftszähler, wird mit jeder Sendebotschaft inkrementiert";
CM_ SG_ 2463978710 UserStateServer_01_CRC "Für MLB:
Berechnung siehe Lastenheft 'Kommunikationsabsicherung für FlexRay und CAN'
Ab MQB und MLBevo:
Berechnung siehe Lastenheft 'End-to-End Kommunikationsabsicherung'

Endwerte siehe Begleitdokument 'S-PDU Kennungsfolgen'";

CM_ SG_ 995 VD_SpannungsAnf "Anforderung Forderung des Verdecks zur Spannungsanhebung des Bordnetzes.";
CM_ SG_ 995 VS_BFS_AutoHoch "automatischer Hochlauf des BFS Fenster ausgelöst durch die Verdecksteuerung";
CM_ SG_ 995 VS_BFS_AutoTief "automatischer Tieflauf des BFS Fenster ausgelöst durch die Verdecksteuerung";
CM_ SG_ 995 VS_BFS_ManHoch "manueller Hochlauf des BFS Fenster ausgelöst durch die Verdecksteuerung";
CM_ SG_ 995 VS_BFS_ManTief "manueller Tieflauf des BFS Fenster ausgelöst durch die Verdecksteuerung";
CM_ SG_ 995 VS_Buzzer "Buzzeransteuerung: 'Buzzeransteuerung' für Gong 200ms (Kombi)";
CM_ SG_ 995 VS_FH_BT_Langhub "Ansteuerung Fensterheber vom Verdecksteuergeraet";
CM_ SG_ 995 VS_FH_FT_Langhub "Ansteuerung Fensterheber vom Verdecksteuergeraet";
CM_ SG_ 995 VS_FH_HBFS_Langhub "Ansteuerung Fensterheber vom Verdecksteuergeraet";
CM_ SG_ 995 VS_FH_HFS_Langhub "Ansteuerung Fensterheber vom Verdecksteuergeraet";
CM_ SG_ 995 VS_FS_AutoHoch "automatischer Hochlauf des FS Fenster ausgelöst durch die Verdecksteuerung";
CM_ SG_ 995 VS_FS_AutoTief "automatischer Tieflauf des FS Fenster ausgelöst durch die Verdecksteuerung";
CM_ SG_ 995 VS_FS_ManHoch "manueller Hochlauf des FS Fenster ausgelöst durch die Verdecksteuerung";
CM_ SG_ 995 VS_FS_ManTief "manueller Tieflauf des FS Fenster ausgelöst durch die Verdecksteuerung";
CM_ SG_ 995 VS_Hardtop "Hardtop montiert";
CM_ SG_ 995 VS_HBFS_AutoHoch "automatischer Hochlauf des HBFS Fenster ausgelöst durch die Verdecksteuerung";
CM_ SG_ 995 VS_HBFS_AutoTief "automatischer Tieflauf des HBFS Fenster ausgelöst durch die Verdecksteuerung";
CM_ SG_ 995 VS_HBFS_ManHoch "manueller Hochlauf des HBFS Fenster ausgelöst durch die Verdecksteuerung";
CM_ SG_ 995 VS_HBFS_ManTief "manueller Tieflauf des HBFS Fenster ausgelöst durch die Verdecksteuerung";
CM_ SG_ 995 VS_HD_sperren "Bei gesetztem Signal wird der Kofferraum/Heckdeckel durch den BCM2 nicht entriegelt werden.";
CM_ SG_ 995 VS_Heckschloss_auf "Signal wird gesetzt, wenn fuer einen Verdeckbetrieb das Öffnen des Heckschlosses erforderlich ist.";
CM_ SG_ 995 VS_HFS_AutoHoch "automatischer Hochlauf des HFS Fenster ausgelöst durch die Verdecksteuerung";
CM_ SG_ 995 VS_HFS_AutoTief "automatischer Tieflauf des HFS Fenster ausgelöst durch die Verdecksteuerung";
CM_ SG_ 995 VS_HFS_ManHoch "manueller Hochlauf des HFS Fenster ausgelöst durch die Verdecksteuerung";
CM_ SG_ 995 VS_HFS_ManTief "manueller Tieflauf des HFS Fenster ausgelöst durch die Verdecksteuerung";
CM_ SG_ 995 VS_HHS_enable "Fehlende Beschreibung (Import)";
CM_ SG_ 995 VS_Lampe_Blk "Ansteuerung Lampe im Kombi

Wird aktiviert bei Aufprüfen, Verdecklauf und Fehlerfall (blinkend).


";
CM_ SG_ 995 VS_StartStopp_Info "Stopp-Freigabe und Start-Anforderung an den Start-Stopp-Koordinator";
CM_ SG_ 995 VS_VD_Bew_auf "



";
CM_ SG_ 995 VS_VD_Bew_zu "


";
CM_ SG_ 995 VS_VD_entriegelt "Zustand des Verdeck entriegelt";
CM_ SG_ 995 VS_VD_Fehler "Fehlerzustand Verdeck";
CM_ SG_ 995 VS_VD_offen_ver "Zustand des Verdecks verriegelt und offen";
CM_ SG_ 995 VS_VD_zu_ver "
";
CM_ SG_ 995 VS_VD_Zwischenposition "Verdeck in Zwischenposition";
CM_ SG_ 995 VS_VDKD_auf "Signal wird gesetzt, wenn der Verdeckkastendeckel vollstaendig geoeffnet ist



";
CM_ SG_ 995 VS_Verdeck_Anf "Verdeckanforderung (Signalisierung der Bereitschaft zur Verdeckbetaetigung ueber Komfortfunktion)";
CM_ SG_ 995 VS_Windschott_nicht_abgelegt "Windschott ist aufgestellt, in Zwischenposition oder die Position ist unbekannt";
CM_ SG_ 995 VSG_Meldungen "Meldungen fuers Kombi lt. konzernübergreifender Abstimmung

0 -> keine Meldung
1 -> 'Verdeckbetrieb RDW aktiv'
2 -> 'Verdeckbetrieb NAR aktiv'
3 -> 'stehendes Verdeck in Zwischenposition (ZP)'
4 -> 'autom. Verdeck in ZP und KL15 aus'
5 -> 'manuelle";

CM_ SG_ 1716 VIN_01_MUX "Achtung:
Die Botschaft ist nicht linear gemultiplext!!!
Sondern 0,1,0,2,0, usw.";
CM_ SG_ 1716 VIN_1 "Initwert:
0x2D bei Fahrzeugen mit Wegfahrsperrengeneration >= 5 
0x58 bei Fahrzeugen mit Wegfahrsperrengeneration < 5 (z.B. WFS-4)";
CM_ SG_ 1716 VIN_10 "Initwert:
0x2D bei Fahrzeugen mit Wegfahrsperrengeneration >= 5 
0x58 bei Fahrzeugen mit Wegfahrsperrengeneration < 5 (z.B. WFS-4)";
CM_ SG_ 1716 VIN_11 "Initwert:
0x2D bei Fahrzeugen mit Wegfahrsperrengeneration >= 5 
0x58 bei Fahrzeugen mit Wegfahrsperrengeneration < 5 (z.B. WFS-4)";
CM_ SG_ 1716 VIN_12 "Initwert:
0x2D bei Fahrzeugen mit Wegfahrsperrengeneration >= 5 
0x58 bei Fahrzeugen mit Wegfahrsperrengeneration < 5 (z.B. WFS-4)";
CM_ SG_ 1716 VIN_13 "Initwert:
0x2D bei Fahrzeugen mit Wegfahrsperrengeneration >= 5 
0x58 bei Fahrzeugen mit Wegfahrsperrengeneration < 5 (z.B. WFS-4)";
CM_ SG_ 1716 VIN_14 "Initwert:
0x2D bei Fahrzeugen mit Wegfahrsperrengeneration >= 5 
0x58 bei Fahrzeugen mit Wegfahrsperrengeneration < 5 (z.B. WFS-4)";
CM_ SG_ 1716 VIN_15 "Initwert:
0x2D bei Fahrzeugen mit Wegfahrsperrengeneration >= 5 
0x58 bei Fahrzeugen mit Wegfahrsperrengeneration < 5 (z.B. WFS-4)";
CM_ SG_ 1716 VIN_16 "Initwert:
0x2D bei Fahrzeugen mit Wegfahrsperrengeneration >= 5 
0x58 bei Fahrzeugen mit Wegfahrsperrengeneration < 5 (z.B. WFS-4)";
CM_ SG_ 1716 VIN_17 "Initwert:
0x2D bei Fahrzeugen mit Wegfahrsperrengeneration >= 5 
0x58 bei Fahrzeugen mit Wegfahrsperrengeneration < 5 (z.B. WFS-4)";
CM_ SG_ 1716 VIN_2 "Initwert:
0x2D bei Fahrzeugen mit Wegfahrsperrengeneration >= 5 
0x58 bei Fahrzeugen mit Wegfahrsperrengeneration < 5 (z.B. WFS-4)";
CM_ SG_ 1716 VIN_3 "Initwert:
0x2D bei Fahrzeugen mit Wegfahrsperrengeneration >= 5 
0x58 bei Fahrzeugen mit Wegfahrsperrengeneration < 5 (z.B. WFS-4)";
CM_ SG_ 1716 VIN_4 "Initwert:
0x2D bei Fahrzeugen mit Wegfahrsperrengeneration >= 5 
0x58 bei Fahrzeugen mit Wegfahrsperrengeneration < 5 (z.B. WFS-4)";
CM_ SG_ 1716 VIN_5 "Initwert:
0x2D bei Fahrzeugen mit Wegfahrsperrengeneration >= 5 
0x58 bei Fahrzeugen mit Wegfahrsperrengeneration < 5 (z.B. WFS-4)";
CM_ SG_ 1716 VIN_6 "Initwert:
0x2D bei Fahrzeugen mit Wegfahrsperrengeneration >= 5 
0x58 bei Fahrzeugen mit Wegfahrsperrengeneration < 5 (z.B. WFS-4)";
CM_ SG_ 1716 VIN_7 "Initwert:
0x2D bei Fahrzeugen mit Wegfahrsperrengeneration >= 5 
0x58 bei Fahrzeugen mit Wegfahrsperrengeneration < 5 (z.B. WFS-4)";
CM_ SG_ 1716 VIN_8 "Initwert:
0x2D bei Fahrzeugen mit Wegfahrsperrengeneration >= 5 
0x58 bei Fahrzeugen mit Wegfahrsperrengeneration < 5 (z.B. WFS-4)";
CM_ SG_ 1716 VIN_9 "Initwert:
0x2D bei Fahrzeugen mit Wegfahrsperrengeneration >= 5 
0x58 bei Fahrzeugen mit Wegfahrsperrengeneration < 5 (z.B. WFS-4)";
BA_DEF_REL_ BU_SG_REL_  "GenSigTimeoutTime" INT 0 65535;
BA_DEF_ BO_  "DiagRequest" ENUM "No", "Yes";
BA_DEF_ BO_  "DiagResponse" ENUM "No", "Yes";
BA_DEF_ BO_  "DiagState" ENUM "No", "Yes";
BA_DEF_ BO_  "GenMsgChkConstant" HEX 0 4095;
BA_DEF_ BO_  "GenMsgCycleTime" INT 0 65535;
BA_DEF_ BO_  "GenMsgCycleTimeFast" INT 0 65535;
BA_DEF_ BO_  "GenMsgDelayTime" INT 0 100000;
BA_DEF_ BO_  "GenMsgILSupport" ENUM "No", "Yes";
BA_DEF_ BO_  "GenMsgNrOfRepetition" INT 0 100;
BA_DEF_ BO_  "GenMsgPDUConstants" STRING;
BA_DEF_ BO_  "GenMsgSendType" ENUM "Cyclic", "not_used", "not_used", "not_used", "not_used", "not_used", "not_used", "IfActive", "NoMsgSendType";
BA_DEF_ BO_  "GenMsgStartDelayTime" INT 0 100000;
BA_DEF_ BO_  "NmMessage" ENUM "No", "Yes";
BA_DEF_ BO_  "NmhMessage" ENUM "No", "Yes";
BA_DEF_ BO_  "MsgType" ENUM "Application", "NM ", "NMH", "TP2.0", "ISO-TP ", "BAP", "EID", "KS", "XCP_PRE_CONFIGURED", "XCP_RUNTIME_CONFIGURED";
BA_DEF_ BO_  "VAGTP20_API" HEX 0 255;
BA_DEF_ BO_  "VAGTP20_DynConnection" ENUM "No", "Yes";
BA_DEF_ BO_  "VAGTP20_DynSetup" ENUM "No", "Yes";
BA_DEF_ BO_  "VAGTP20_StatConnection" ENUM "No", "Yes";
BA_DEF_ BO_  "CANFD_BRS" ENUM "0", "1";
BA_DEF_ BO_  "VFrameFormat" ENUM "StandardCAN", "ExtendedCAN", "reserved", "reserved", "reserved", "reserved", "reserved", "reserved", "reserved", "reserved", "reserved", "reserved", "reserved", "reserved", "StandardCAN_FD", "ExtendedCAN_FD";
BA_DEF_ SG_  "GenSigActiveRepetitions" INT -2147483648 2147483647;
BA_DEF_ SG_  "GenSigInactiveValue" INT -2147483648 2147483647;
BA_DEF_ SG_  "GenSigSendType" ENUM "Cyclic", "OnWrite", "OnWriteWithRepetition", "OnChange", "OnChangeWithRepetition", "IfActive", "IfActiveWithRepetition", "NoSigSendType", "OnChangeAndIfActive", "OnChangeAndIfActiveWithRepetition";
BA_DEF_ SG_  "GenSigStartValue" INT -2147483648 2147483647;
BA_DEF_ SG_  "NWM-WakeupAllowed" ENUM "No", "Yes";
BA_DEF_ SG_  "GenSigFuncType" ENUM "NoFunction", "MsgCounter", "CRC-8", "XOR", "XOR-2", "DatedBit", "SW-Kl15", "CHK", "Constant", "Protocol", "CRC-8-SAE_J1850", "CRC-32", "DataLength", "DataID", "MsgCounter16", "SOK-Signatur", "Cluster";
BA_DEF_ SG_  "GenSigSwitchedByIgnition" ENUM "No", "Yes";
BA_DEF_ SG_  "Fehlerwert" HEX 0 2147483647;
BA_DEF_ SG_  "GenSigMissingSourceValue" HEX 0 2147483647;
BA_DEF_DEF_REL_  "GenSigTimeoutTime" 0;
BA_DEF_DEF_  "DiagRequest" "No";
BA_DEF_DEF_  "DiagResponse" "No";
BA_DEF_DEF_  "DiagState" "No";
BA_DEF_DEF_  "GenMsgChkConstant" 0;
BA_DEF_DEF_  "GenMsgCycleTime" 0;
BA_DEF_DEF_  "GenMsgCycleTimeFast" 0;
BA_DEF_DEF_  "GenMsgDelayTime" 0;
BA_DEF_DEF_  "GenMsgILSupport" "No";
BA_DEF_DEF_  "GenMsgNrOfRepetition" 0;
BA_DEF_DEF_  "GenMsgPDUConstants" "";
BA_DEF_DEF_  "GenMsgSendType" "NoMsgSendType";
BA_DEF_DEF_  "GenMsgStartDelayTime" 0;
BA_DEF_DEF_  "NmMessage" "No";
BA_DEF_DEF_  "NmhMessage" "No";
BA_DEF_DEF_  "MsgType" "Application";
BA_DEF_DEF_  "VAGTP20_API" 0;
BA_DEF_DEF_  "VAGTP20_DynConnection" "No";
BA_DEF_DEF_  "VAGTP20_DynSetup" "No";
BA_DEF_DEF_  "VAGTP20_StatConnection" "No";
BA_DEF_DEF_  "CANFD_BRS" "1";
BA_DEF_DEF_  "VFrameFormat" "StandardCAN";
BA_DEF_DEF_  "GenSigActiveRepetitions" 0;
BA_DEF_DEF_  "GenSigInactiveValue" 0;
BA_DEF_DEF_  "GenSigSendType" "NoSigSendType";
BA_DEF_DEF_  "GenSigStartValue" 0;
BA_DEF_DEF_  "NWM-WakeupAllowed" "No";
BA_DEF_DEF_  "GenSigFuncType" "NoFunction";
BA_DEF_DEF_  "GenSigSwitchedByIgnition" "Yes";
BA_DEF_DEF_  "Fehlerwert" 0;
BA_DEF_DEF_  "GenSigMissingSourceValue" 0;
BA_ "GenMsgCycleTime" BO_ 1527 1000;
BA_ "GenMsgDelayTime" BO_ 1527 100;
BA_ "GenMsgILSupport" BO_ 1527 1;
BA_ "GenMsgSendType" BO_ 1527 0;
BA_ "VFrameFormat" BO_ 1527 14;
BA_ "GenMsgCycleTime" BO_ 2264486920 20;
BA_ "GenMsgILSupport" BO_ 2264486920 1;
BA_ "GenMsgPDUConstants" BO_ 2264486920 "0x41,0x87,0x40,0x5d,0x39,0xbe,0x1b,0x88,0x76,0xf9,0xb3,0x17,0xb6,0x0a,0xd8,0x84";
BA_ "GenMsgSendType" BO_ 2264486920 0;
BA_ "VFrameFormat" BO_ 2264486920 15;
BA_ "GenMsgCycleTime" BO_ 2463978815 100;
BA_ "GenMsgDelayTime" BO_ 2463978815 10;
BA_ "GenMsgILSupport" BO_ 2463978815 1;
BA_ "GenMsgPDUConstants" BO_ 2463978815 "0x76,0xf4,0x74,0x70,0xb2,0xcd,0xdb,0x06,0xae,0x14,0x25,0x86,0x20,0x24,0x82,0xd0";
BA_ "GenMsgSendType" BO_ 2463978815 0;
BA_ "VFrameFormat" BO_ 2463978815 15;
BA_ "GenMsgCycleTime" BO_ 980 1000;
BA_ "GenMsgCycleTimeFast" BO_ 980 100;
BA_ "GenMsgDelayTime" BO_ 980 50;
BA_ "GenMsgILSupport" BO_ 980 1;
BA_ "GenMsgNrOfRepetition" BO_ 980 5;
BA_ "GenMsgPDUConstants" BO_ 980 "0xc3,0x79,0xbf,0xdb,0xe9,0x11,0x46,0x86,0x69,0xb6,0x9b,0x29,0x15,0x9c,0x45,0x0d";
BA_ "GenMsgSendType" BO_ 980 0;
BA_ "VFrameFormat" BO_ 980 14;
BA_ "GenMsgDelayTime" BO_ 2589283756 100;
BA_ "GenMsgILSupport" BO_ 2589283756 1;
BA_ "VFrameFormat" BO_ 2589283756 15;
BA_ "GenMsgDelayTime" BO_ 2464153724 100;
BA_ "GenMsgILSupport" BO_ 2464153724 1;
BA_ "VFrameFormat" BO_ 2464153724 15;
BA_ "GenMsgDelayTime" BO_ 2464284796 100;
BA_ "GenMsgILSupport" BO_ 2464284796 1;
BA_ "VFrameFormat" BO_ 2464284796 15;
BA_ "GenMsgDelayTime" BO_ 2464153784 100;
BA_ "GenMsgILSupport" BO_ 2464153784 1;
BA_ "VFrameFormat" BO_ 2464153784 15;
BA_ "GenMsgDelayTime" BO_ 2464284856 100;
BA_ "GenMsgILSupport" BO_ 2464284856 1;
BA_ "VFrameFormat" BO_ 2464284856 15;
BA_ "GenMsgDelayTime" BO_ 2464153719 100;
BA_ "GenMsgILSupport" BO_ 2464153719 1;
BA_ "VFrameFormat" BO_ 2464153719 15;
BA_ "GenMsgDelayTime" BO_ 2464284791 100;
BA_ "GenMsgILSupport" BO_ 2464284791 1;
BA_ "VFrameFormat" BO_ 2464284791 15;
BA_ "GenMsgDelayTime" BO_ 2464153913 100;
BA_ "GenMsgILSupport" BO_ 2464153913 1;
BA_ "VFrameFormat" BO_ 2464153913 15;
BA_ "GenMsgDelayTime" BO_ 2464284985 100;
BA_ "GenMsgILSupport" BO_ 2464284985 1;
BA_ "VFrameFormat" BO_ 2464284985 15;
BA_ "GenMsgDelayTime" BO_ 2464157814 100;
BA_ "GenMsgILSupport" BO_ 2464157814 1;
BA_ "VFrameFormat" BO_ 2464157814 15;
BA_ "GenMsgDelayTime" BO_ 2464288886 100;
BA_ "GenMsgILSupport" BO_ 2464288886 1;
BA_ "VFrameFormat" BO_ 2464288886 15;
BA_ "GenMsgDelayTime" BO_ 2464153733 100;
BA_ "GenMsgILSupport" BO_ 2464153733 1;
BA_ "VFrameFormat" BO_ 2464153733 15;
BA_ "GenMsgDelayTime" BO_ 2464284805 100;
BA_ "GenMsgILSupport" BO_ 2464284805 1;
BA_ "VFrameFormat" BO_ 2464284805 15;
BA_ "GenMsgCycleTime" BO_ 1313 200;
BA_ "GenMsgILSupport" BO_ 1313 1;
BA_ "GenMsgSendType" BO_ 1313 0;
BA_ "VFrameFormat" BO_ 1313 14;
BA_ "GenMsgCycleTime" BO_ 1413 1000;
BA_ "GenMsgDelayTime" BO_ 1413 10;
BA_ "GenMsgILSupport" BO_ 1413 1;
BA_ "GenMsgSendType" BO_ 1413 0;
BA_ "VFrameFormat" BO_ 1413 14;
BA_ "GenMsgCycleTime" BO_ 2589283571 1000;
BA_ "GenMsgDelayTime" BO_ 2589283571 200;
BA_ "GenMsgILSupport" BO_ 2589283571 1;
BA_ "GenMsgSendType" BO_ 2589283571 0;
BA_ "VFrameFormat" BO_ 2589283571 15;
BA_ "GenMsgCycleTime" BO_ 2589283622 1000;
BA_ "GenMsgDelayTime" BO_ 2589283622 200;
BA_ "GenMsgILSupport" BO_ 2589283622 1;
BA_ "GenMsgSendType" BO_ 2589283622 0;
BA_ "VFrameFormat" BO_ 2589283622 15;
BA_ "GenMsgCycleTime" BO_ 2589283623 1000;
BA_ "GenMsgDelayTime" BO_ 2589283623 200;
BA_ "GenMsgILSupport" BO_ 2589283623 1;
BA_ "GenMsgSendType" BO_ 2589283623 0;
BA_ "VFrameFormat" BO_ 2589283623 15;
BA_ "GenMsgCycleTime" BO_ 1447 1000;
BA_ "GenMsgCycleTimeFast" BO_ 1447 100;
BA_ "GenMsgDelayTime" BO_ 1447 50;
BA_ "GenMsgILSupport" BO_ 1447 1;
BA_ "GenMsgSendType" BO_ 1447 0;
BA_ "VFrameFormat" BO_ 1447 14;
BA_ "GenMsgCycleTime" BO_ 976 100;
BA_ "GenMsgDelayTime" BO_ 976 20;
BA_ "GenMsgILSupport" BO_ 976 1;
BA_ "GenMsgSendType" BO_ 976 0;
BA_ "VFrameFormat" BO_ 976 14;
BA_ "GenMsgCycleTime" BO_ 997 100;
BA_ "GenMsgDelayTime" BO_ 997 20;
BA_ "GenMsgILSupport" BO_ 997 1;
BA_ "GenMsgPDUConstants" BO_ 997 "0xc4,0x6a,0x69,0x30,0xcf,0x61,0x58,0x51,0x1b,0x86,0x99,0xd3,0xf6,0x1d,0x9a,0x37";
BA_ "GenMsgSendType" BO_ 997 0;
BA_ "VFrameFormat" BO_ 997 14;
BA_ "GenMsgCycleTime" BO_ 2589283396 500;
BA_ "GenMsgILSupport" BO_ 2589283396 1;
BA_ "GenMsgSendType" BO_ 2589283396 0;
BA_ "VFrameFormat" BO_ 2589283396 15;
BA_ "GenMsgCycleTime" BO_ 1019 80;
BA_ "GenMsgILSupport" BO_ 1019 1;
BA_ "GenMsgSendType" BO_ 1019 0;
BA_ "VFrameFormat" BO_ 1019 14;
BA_ "GenMsgCycleTime" BO_ 2463978710 100;
BA_ "GenMsgCycleTimeFast" BO_ 2463978710 10;
BA_ "GenMsgDelayTime" BO_ 2463978710 10;
BA_ "GenMsgILSupport" BO_ 2463978710 1;
BA_ "GenMsgNrOfRepetition" BO_ 2463978710 5;
BA_ "GenMsgPDUConstants" BO_ 2463978710 "0xf3,0xbb,0x4c,0x48,0x05,0x08,0x69,0xc8,0x60,0x76,0x27,0x02,0x3a,0xa8,0x32,0x51";
BA_ "GenMsgSendType" BO_ 2463978710 0;
BA_ "VFrameFormat" BO_ 2463978710 15;
BA_ "GenMsgCycleTime" BO_ 995 100;
BA_ "GenMsgCycleTimeFast" BO_ 995 50;
BA_ "GenMsgDelayTime" BO_ 995 50;
BA_ "GenMsgILSupport" BO_ 995 1;
BA_ "GenMsgNrOfRepetition" BO_ 995 5;
BA_ "GenMsgSendType" BO_ 995 0;
BA_ "VFrameFormat" BO_ 995 14;
BA_ "GenMsgCycleTime" BO_ 1716 200;
BA_ "GenMsgILSupport" BO_ 1716 1;
BA_ "GenMsgSendType" BO_ 1716 0;
BA_ "VFrameFormat" BO_ 1716 14;
BA_ "GenSigSendType" SG_ 1527 RW_Gesamt_Reichweite_Anzeige 0;
BA_ "GenSigStartValue" SG_ 1527 RW_Gesamt_Reichweite_Anzeige 2046;
BA_ "GenSigSwitchedByIgnition" SG_ 1527 RW_Gesamt_Reichweite_Anzeige 0;
BA_ "Fehlerwert" SG_ 1527 RW_Gesamt_Reichweite_Anzeige 2047;
BA_ "GenSigSendType" SG_ 1527 RW_Primaer_Reichweite_Anzeige 0;
BA_ "GenSigStartValue" SG_ 1527 RW_Primaer_Reichweite_Anzeige 2046;
BA_ "GenSigSwitchedByIgnition" SG_ 1527 RW_Primaer_Reichweite_Anzeige 0;
BA_ "Fehlerwert" SG_ 1527 RW_Primaer_Reichweite_Anzeige 2047;
BA_ "GenSigSendType" SG_ 1527 RW_Reichweite_Einheit_Anzeige 0;
BA_ "GenSigSwitchedByIgnition" SG_ 1527 RW_Reichweite_Einheit_Anzeige 0;
BA_ "GenSigSendType" SG_ 1527 RW_Reservewarnung_aktiv 0;
BA_ "GenSigSwitchedByIgnition" SG_ 1527 RW_Reservewarnung_aktiv 0;
BA_ "GenSigSendType" SG_ 1527 RW_Sek_Reichweitenv_Einheit 0;
BA_ "GenSigStartValue" SG_ 1527 RW_Sek_Reichweitenv_Einheit 3;
BA_ "GenSigSwitchedByIgnition" SG_ 1527 RW_Sek_Reichweitenv_Einheit 0;
BA_ "GenSigSendType" SG_ 1527 RW_Sek_Reichweitenverbrauch 0;
BA_ "GenSigStartValue" SG_ 1527 RW_Sek_Reichweitenverbrauch 2047;
BA_ "GenSigSwitchedByIgnition" SG_ 1527 RW_Sek_Reichweitenverbrauch 0;
BA_ "GenSigSendType" SG_ 1527 RW_Sekundaer_Reichweite 0;
BA_ "GenSigStartValue" SG_ 1527 RW_Sekundaer_Reichweite 2046;
BA_ "GenSigSwitchedByIgnition" SG_ 1527 RW_Sekundaer_Reichweite 0;
BA_ "Fehlerwert" SG_ 1527 RW_Sekundaer_Reichweite 2047;
BA_ "GenSigSendType" SG_ 1527 RW_Sekundaer_Reichweite_Anzeige 0;
BA_ "GenSigStartValue" SG_ 1527 RW_Sekundaer_Reichweite_Anzeige 2046;
BA_ "GenSigSwitchedByIgnition" SG_ 1527 RW_Sekundaer_Reichweite_Anzeige 0;
BA_ "Fehlerwert" SG_ 1527 RW_Sekundaer_Reichweite_Anzeige 2047;
BA_ "GenSigSendType" SG_ 1527 RW_Tendenz 0;
BA_ "GenSigSwitchedByIgnition" SG_ 1527 RW_Tendenz 0;
BA_ "GenSigSendType" SG_ 1527 RW_Texte 3;
BA_ "GenSigSwitchedByIgnition" SG_ 1527 RW_Texte 0;
BA_ "GenSigSendType" SG_ 2264486920 RHP_01_BZ 0;
BA_ "GenSigFuncType" SG_ 2264486920 RHP_01_BZ 1;
BA_ "GenSigSwitchedByIgnition" SG_ 2264486920 RHP_01_BZ 0;
BA_ "GenSigSendType" SG_ 2264486920 RHP_01_CRC 0;
BA_ "GenSigFuncType" SG_ 2264486920 RHP_01_CRC 2;
BA_ "GenSigSwitchedByIgnition" SG_ 2264486920 RHP_01_CRC 0;
BA_ "GenSigSendType" SG_ 2264486920 RHP_Anf_ASIL 0;
BA_ "GenSigSendType" SG_ 2264486920 RHP_Anforderung_HMS 0;
BA_ "GenSigSwitchedByIgnition" SG_ 2264486920 RHP_Anforderung_HMS 0;
BA_ "GenSigSendType" SG_ 2264486920 RHP_EA_AnfStat 0;
BA_ "GenSigSendType" SG_ 2264486920 RHP_EA_eCall 0;
BA_ "GenSigSendType" SG_ 2264486920 RHP_EA_Innenraumlicht 0;
BA_ "GenSigSendType" SG_ 2264486920 RHP_EA_PreCrash 0;
BA_ "GenSigSendType" SG_ 2264486920 RHP_EA_Tueren 0;
BA_ "GenSigSendType" SG_ 2264486920 RHP_eCall_Anf 0;
BA_ "GenSigSwitchedByIgnition" SG_ 2264486920 RHP_eCall_Anf 0;
BA_ "GenSigSendType" SG_ 2264486920 RHP_Fahrzeughupe_Anf 0;
BA_ "GenSigSwitchedByIgnition" SG_ 2264486920 RHP_Fahrzeughupe_Anf 0;
BA_ "GenSigSendType" SG_ 2264486920 RHP_Freilaufstrategie_TSK 0;
BA_ "GenSigSendType" SG_ 2264486920 RHP_HOS 0;
BA_ "GenSigSendType" SG_ 2264486920 RHP_Innenraumlicht_Anf 0;
BA_ "GenSigSendType" SG_ 2264486920 RHP_Minimale_Bremsung 0;
BA_ "GenSigSendType" SG_ 2264486920 RHP_nachtr_Stopp_Anf 0;
BA_ "GenSigSwitchedByIgnition" SG_ 2264486920 RHP_nachtr_Stopp_Anf 0;
BA_ "GenSigSendType" SG_ 2264486920 RHP_neg_Sollbeschl_Grad 0;
BA_ "GenSigSendType" SG_ 2264486920 RHP_OPSEnable 0;
BA_ "GenSigSwitchedByIgnition" SG_ 2264486920 RHP_OPSEnable 0;
BA_ "GenSigSendType" SG_ 2264486920 RHP_Parking_St 0;
BA_ "GenSigSwitchedByIgnition" SG_ 2264486920 RHP_Parking_St 0;
BA_ "GenSigSendType" SG_ 2264486920 RHP_pos_Sollbeschl_Grad 0;
BA_ "GenSigSwitchedByIgnition" SG_ 2264486920 RHP_pos_Sollbeschl_Grad 0;
BA_ "GenSigSendType" SG_ 2264486920 RHP_PreCrash_Anf 0;
BA_ "GenSigSendType" SG_ 2264486920 RHP_QFK_AnfStat 0;
BA_ "GenSigStartValue" SG_ 2264486920 RHP_QFK_AnfStat 1;
BA_ "GenSigSendType" SG_ 2264486920 RHP_QFK_Art1 0;
BA_ "GenSigSwitchedByIgnition" SG_ 2264486920 RHP_QFK_Art1 0;
BA_ "GenSigSendType" SG_ 2264486920 RHP_QFK_Art2 0;
BA_ "GenSigSendType" SG_ 2264486920 RHP_QFK_KrSoll 0;
BA_ "GenSigSendType" SG_ 2264486920 RHP_QFK_KrSoll_VZ 0;
BA_ "GenSigSendType" SG_ 2264486920 RHP_QFK_KruemmSoll 0;
BA_ "GenSigSendType" SG_ 2264486920 RHP_QFK_KruemmSoll_VZ 0;
BA_ "GenSigSendType" SG_ 2264486920 RHP_QFK_Signal1 0;
BA_ "GenSigSwitchedByIgnition" SG_ 2264486920 RHP_QFK_Signal1 0;
BA_ "GenSigSendType" SG_ 2264486920 RHP_QFK_Signal2 0;
BA_ "GenSigSendType" SG_ 2264486920 RHP_QFK_Spuerb 0;
BA_ "GenSigSendType" SG_ 2264486920 RHP_RBF_Available 0;
BA_ "GenSigSwitchedByIgnition" SG_ 2264486920 RHP_RBF_Available 0;
BA_ "GenSigSendType" SG_ 2264486920 RHP_Ruckfreigabe 0;
BA_ "GenSigSwitchedByIgnition" SG_ 2264486920 RHP_Ruckfreigabe 0;
BA_ "GenSigSendType" SG_ 2264486920 RHP_SCAM_HeatingRequest 0;
BA_ "GenSigSendType" SG_ 2264486920 RHP_Sollbeschleunigung 0;
BA_ "GenSigStartValue" SG_ 2264486920 RHP_Sollbeschleunigung 2046;
BA_ "Fehlerwert" SG_ 2264486920 RHP_Sollbeschleunigung 2047;
BA_ "GenSigSendType" SG_ 2264486920 RHP_Spurwechsel_Ready 0;
BA_ "GenSigSwitchedByIgnition" SG_ 2264486920 RHP_Spurwechsel_Ready 0;
BA_ "GenSigSendType" SG_ 2264486920 RHP_StartStopp_Info 0;
BA_ "GenSigSendType" SG_ 2264486920 RHP_Status_Function 0;
BA_ "GenSigSwitchedByIgnition" SG_ 2264486920 RHP_Status_Function 0;
BA_ "GenSigSendType" SG_ 2264486920 RHP_Status_Lat 0;
BA_ "GenSigSendType" SG_ 2264486920 RHP_Status_Long 0;
BA_ "GenSigSendType" SG_ 2264486920 RHP_TSK_Status 0;
BA_ "GenSigStartValue" SG_ 2264486920 RHP_TSK_Status 1;
BA_ "GenSigSendType" SG_ 2264486920 RHP_TV_Trigger 0;
BA_ "GenSigSwitchedByIgnition" SG_ 2264486920 RHP_TV_Trigger 0;
BA_ "GenSigSendType" SG_ 2264486920 RHP_Uss_Anforderung 0;
BA_ "GenSigSwitchedByIgnition" SG_ 2264486920 RHP_Uss_Anforderung 0;
BA_ "GenSigSendType" SG_ 2264486920 RHP_Verz_Anf 0;
BA_ "GenSigStartValue" SG_ 2264486920 RHP_Verz_Anf 1023;
BA_ "GenSigSendType" SG_ 2264486920 RHP_Verz_Freigabe 0;
BA_ "GenSigSendType" SG_ 2264486920 RHP_Warnblinken 0;
BA_ "GenSigSwitchedByIgnition" SG_ 2264486920 RHP_Warnblinken 0;
BA_ "GenSigSendType" SG_ 2264486920 RHP_Warnruckeln_Anf 0;
BA_ "GenSigSendType" SG_ 2264486920 RHP_zul_Regelabw_oben 0;
BA_ "GenSigSendType" SG_ 2264486920 RHP_zul_Regelabw_unten 0;
BA_ "GenSigSendType" SG_ 2463978815 SBM_01_BZ 0;
BA_ "GenSigFuncType" SG_ 2463978815 SBM_01_BZ 1;
BA_ "GenSigSwitchedByIgnition" SG_ 2463978815 SBM_01_BZ 0;
BA_ "GenSigSendType" SG_ 2463978815 SBM_01_CRC 0;
BA_ "GenSigFuncType" SG_ 2463978815 SBM_01_CRC 2;
BA_ "GenSigSwitchedByIgnition" SG_ 2463978815 SBM_01_CRC 0;
BA_ "GenSigSendType" SG_ 2463978815 SBM_FahrerAkt_Lenkradpaddle 3;
BA_ "GenSigSwitchedByIgnition" SG_ 2463978815 SBM_FahrerAkt_Lenkradpaddle 0;
BA_ "GenSigSendType" SG_ 2463978815 SBM_FahrerAkt_P_Taste 3;
BA_ "GenSigSwitchedByIgnition" SG_ 2463978815 SBM_FahrerAkt_P_Taste 0;
BA_ "GenSigSendType" SG_ 2463978815 SBM_FahrerAkt_Schaltbetaetigung 3;
BA_ "GenSigSwitchedByIgnition" SG_ 2463978815 SBM_FahrerAkt_Schaltbetaetigung 0;
BA_ "GenSigSendType" SG_ 2463978815 SBM_Veto_Fahrstufe_extern 3;
BA_ "GenSigSwitchedByIgnition" SG_ 2463978815 SBM_Veto_Fahrstufe_extern 0;
BA_ "Fehlerwert" SG_ 2463978815 SBM_Veto_Fahrstufe_extern 3;
BA_ "GenSigSendType" SG_ 980 BH_Blinker_Fehler 4;
BA_ "GenSigSwitchedByIgnition" SG_ 980 BH_Blinker_Fehler 0;
BA_ "Fehlerwert" SG_ 980 BH_Blinker_Fehler 1;
BA_ "GenSigSendType" SG_ 980 BH_Blinker_li 4;
BA_ "GenSigSwitchedByIgnition" SG_ 980 BH_Blinker_li 0;
BA_ "GenSigSendType" SG_ 980 BH_Blinker_re 4;
BA_ "GenSigSwitchedByIgnition" SG_ 980 BH_Blinker_re 0;
BA_ "GenSigSendType" SG_ 980 BH_Fernlicht 3;
BA_ "GenSigSwitchedByIgnition" SG_ 980 BH_Fernlicht 0;
BA_ "GenSigSendType" SG_ 980 BH_Lichthupe 4;
BA_ "GenSigSwitchedByIgnition" SG_ 980 BH_Lichthupe 0;
BA_ "GenSigSendType" SG_ 980 FAS_Taster 3;
BA_ "GenSigSwitchedByIgnition" SG_ 980 FAS_Taster 0;
BA_ "GenSigSendType" SG_ 980 FAS_Taster_Fehler 3;
BA_ "GenSigSwitchedByIgnition" SG_ 980 FAS_Taster_Fehler 0;
BA_ "Fehlerwert" SG_ 980 FAS_Taster_Fehler 1;
BA_ "GenSigSendType" SG_ 980 LRH_aktiv 3;
BA_ "GenSigSwitchedByIgnition" SG_ 980 LRH_aktiv 0;
BA_ "GenSigSendType" SG_ 980 LRH_On_Off 3;
BA_ "GenSigSwitchedByIgnition" SG_ 980 LRH_On_Off 0;
BA_ "Fehlerwert" SG_ 980 LRH_On_Off 3;
BA_ "GenSigSendType" SG_ 980 LSS_Tastencode 3;
BA_ "GenSigSwitchedByIgnition" SG_ 980 LSS_Tastencode 0;
BA_ "GenSigSendType" SG_ 980 SMLS_01_BZ 0;
BA_ "GenSigFuncType" SG_ 980 SMLS_01_BZ 1;
BA_ "GenSigSwitchedByIgnition" SG_ 980 SMLS_01_BZ 0;
BA_ "GenSigSendType" SG_ 980 SMLS_01_CRC 0;
BA_ "GenSigFuncType" SG_ 980 SMLS_01_CRC 2;
BA_ "GenSigSwitchedByIgnition" SG_ 980 SMLS_01_CRC 0;
BA_ "GenSigSendType" SG_ 980 SMLS_Hupe 4;
BA_ "GenSigSwitchedByIgnition" SG_ 980 SMLS_Hupe 0;
BA_ "GenSigSendType" SG_ 980 SMLS_P_verriegelt 4;
BA_ "GenSigSwitchedByIgnition" SG_ 980 SMLS_P_verriegelt 0;
BA_ "Fehlerwert" SG_ 980 SMLS_P_verriegelt 3;
BA_ "GenSigSendType" SG_ 980 SMLS_P_verriegelt_plausibel 3;
BA_ "GenSigSwitchedByIgnition" SG_ 980 SMLS_P_verriegelt_plausibel 0;
BA_ "GenSigSendType" SG_ 980 SMLS_PTT 4;
BA_ "GenSigSendType" SG_ 980 WH_Frontwaschen 3;
BA_ "GenSigSwitchedByIgnition" SG_ 980 WH_Frontwaschen 0;
BA_ "GenSigSendType" SG_ 980 WH_Heckintervall 3;
BA_ "GenSigSwitchedByIgnition" SG_ 980 WH_Heckintervall 0;
BA_ "GenSigSendType" SG_ 980 WH_Heckwaschen 3;
BA_ "GenSigSwitchedByIgnition" SG_ 980 WH_Heckwaschen 0;
BA_ "GenSigSendType" SG_ 980 WH_Intervall 3;
BA_ "GenSigSwitchedByIgnition" SG_ 980 WH_Intervall 0;
BA_ "GenSigSendType" SG_ 980 WH_Intervallstufen 3;
BA_ "GenSigSwitchedByIgnition" SG_ 980 WH_Intervallstufen 0;
BA_ "Fehlerwert" SG_ 980 WH_Intervallstufen 15;
BA_ "GenSigMissingSourceValue" SG_ 980 WH_Intervallstufen 15;
BA_ "GenSigSendType" SG_ 980 WH_SRA 3;
BA_ "GenSigSwitchedByIgnition" SG_ 980 WH_SRA 0;
BA_ "GenSigSendType" SG_ 980 WH_Tipwischen 4;
BA_ "GenSigSwitchedByIgnition" SG_ 980 WH_Tipwischen 0;
BA_ "GenSigSendType" SG_ 980 WH_Tipwischen_lang 4;
BA_ "GenSigSwitchedByIgnition" SG_ 980 WH_Tipwischen_lang 0;
BA_ "GenSigSendType" SG_ 980 WH_Wischer_Fehler 3;
BA_ "GenSigSwitchedByIgnition" SG_ 980 WH_Wischer_Fehler 0;
BA_ "Fehlerwert" SG_ 980 WH_Wischer_Fehler 1;
BA_ "GenSigSendType" SG_ 980 WH_WischerStufe1 3;
BA_ "GenSigSwitchedByIgnition" SG_ 980 WH_WischerStufe1 0;
BA_ "GenSigSendType" SG_ 980 WH_WischerStufe2 3;
BA_ "GenSigSwitchedByIgnition" SG_ 980 WH_WischerStufe2 0;
BA_ "GenSigSendType" SG_ 2589283756 SOK_ungeschuetzte_Zeit 3;
BA_ "GenSigSwitchedByIgnition" SG_ 2589283756 SOK_ungeschuetzte_Zeit 0;
BA_ "GenSigSendType" SG_ 2464153724 SOK_Zeit_EMotor_01_Challenge 3;
BA_ "GenSigSwitchedByIgnition" SG_ 2464153724 SOK_Zeit_EMotor_01_Challenge 0;
BA_ "GenSigSendType" SG_ 2464284796 SOK_Zeit_EMotor_01_Signatur 3;
BA_ "GenSigFuncType" SG_ 2464284796 SOK_Zeit_EMotor_01_Signatur 15;
BA_ "GenSigSwitchedByIgnition" SG_ 2464284796 SOK_Zeit_EMotor_01_Signatur 0;
BA_ "GenSigSendType" SG_ 2464284796 SOK_Zeit_EMotor_01_Zeit 3;
BA_ "GenSigSwitchedByIgnition" SG_ 2464284796 SOK_Zeit_EMotor_01_Zeit 0;
BA_ "GenSigSendType" SG_ 2464153784 SOK_Zeit_EMotor_02_Challenge 3;
BA_ "GenSigSwitchedByIgnition" SG_ 2464153784 SOK_Zeit_EMotor_02_Challenge 0;
BA_ "GenSigSendType" SG_ 2464284856 SOK_Zeit_EMotor_02_Signatur 3;
BA_ "GenSigFuncType" SG_ 2464284856 SOK_Zeit_EMotor_02_Signatur 15;
BA_ "GenSigSwitchedByIgnition" SG_ 2464284856 SOK_Zeit_EMotor_02_Signatur 0;
BA_ "GenSigSendType" SG_ 2464284856 SOK_Zeit_EMotor_02_Zeit 3;
BA_ "GenSigSwitchedByIgnition" SG_ 2464284856 SOK_Zeit_EMotor_02_Zeit 0;
BA_ "GenSigSendType" SG_ 2464153719 SOK_Zeit_Getriebe_01_Challenge 3;
BA_ "GenSigSwitchedByIgnition" SG_ 2464153719 SOK_Zeit_Getriebe_01_Challenge 0;
BA_ "GenSigSendType" SG_ 2464284791 SOK_Zeit_Getriebe_01_Signatur 3;
BA_ "GenSigFuncType" SG_ 2464284791 SOK_Zeit_Getriebe_01_Signatur 15;
BA_ "GenSigSwitchedByIgnition" SG_ 2464284791 SOK_Zeit_Getriebe_01_Signatur 0;
BA_ "GenSigSendType" SG_ 2464284791 SOK_Zeit_Getriebe_01_Zeit 3;
BA_ "GenSigSwitchedByIgnition" SG_ 2464284791 SOK_Zeit_Getriebe_01_Zeit 0;
BA_ "GenSigSendType" SG_ 2464153913 SOK_Zeit_LCU_SMH_Challenge 3;
BA_ "GenSigSwitchedByIgnition" SG_ 2464153913 SOK_Zeit_LCU_SMH_Challenge 0;
BA_ "GenSigSendType" SG_ 2464284985 SOK_Zeit_LCU_SMH_Signatur 3;
BA_ "GenSigFuncType" SG_ 2464284985 SOK_Zeit_LCU_SMH_Signatur 15;
BA_ "GenSigSwitchedByIgnition" SG_ 2464284985 SOK_Zeit_LCU_SMH_Signatur 0;
BA_ "GenSigSendType" SG_ 2464284985 SOK_Zeit_LCU_SMH_Zeit 3;
BA_ "GenSigSwitchedByIgnition" SG_ 2464284985 SOK_Zeit_LCU_SMH_Zeit 0;
BA_ "GenSigSendType" SG_ 2464157814 SOK_Zeit_MO_01_Challenge 3;
BA_ "GenSigSwitchedByIgnition" SG_ 2464157814 SOK_Zeit_MO_01_Challenge 0;
BA_ "GenSigSendType" SG_ 2464288886 SOK_Zeit_MO_01_Signatur 3;
BA_ "GenSigFuncType" SG_ 2464288886 SOK_Zeit_MO_01_Signatur 15;
BA_ "GenSigSwitchedByIgnition" SG_ 2464288886 SOK_Zeit_MO_01_Signatur 0;
BA_ "GenSigSendType" SG_ 2464288886 SOK_Zeit_MO_01_Zeit 3;
BA_ "GenSigSwitchedByIgnition" SG_ 2464288886 SOK_Zeit_MO_01_Zeit 0;
BA_ "GenSigSendType" SG_ 2464153733 SOK_Zeit_RSG_Challenge 3;
BA_ "GenSigSwitchedByIgnition" SG_ 2464153733 SOK_Zeit_RSG_Challenge 0;
BA_ "GenSigSendType" SG_ 2464284805 SOK_Zeit_RSG_Signatur 3;
BA_ "GenSigFuncType" SG_ 2464284805 SOK_Zeit_RSG_Signatur 15;
BA_ "GenSigSwitchedByIgnition" SG_ 2464284805 SOK_Zeit_RSG_Signatur 0;
BA_ "GenSigSendType" SG_ 2464284805 SOK_Zeit_RSG_Zeit 3;
BA_ "GenSigSwitchedByIgnition" SG_ 2464284805 SOK_Zeit_RSG_Zeit 0;
BA_ "GenSigSendType" SG_ 1313 STH_EKP_Anst 0;
BA_ "GenSigSwitchedByIgnition" SG_ 1313 STH_EKP_Anst 0;
BA_ "GenSigSendType" SG_ 1313 STH_Fehler_ElWaPu 0;
BA_ "GenSigSwitchedByIgnition" SG_ 1313 STH_Fehler_ElWaPu 0;
BA_ "Fehlerwert" SG_ 1313 STH_Fehler_ElWaPu 1;
BA_ "GenSigSendType" SG_ 1313 STH_Fehlerstatus 0;
BA_ "GenSigSwitchedByIgnition" SG_ 1313 STH_Fehlerstatus 0;
BA_ "GenSigSendType" SG_ 1313 STH_Funk_aus 0;
BA_ "GenSigSwitchedByIgnition" SG_ 1313 STH_Funk_aus 0;
BA_ "GenSigSendType" SG_ 1313 STH_Funk_ein 0;
BA_ "GenSigSwitchedByIgnition" SG_ 1313 STH_Funk_ein 0;
BA_ "GenSigSendType" SG_ 1313 STH_Geblaese 0;
BA_ "GenSigSwitchedByIgnition" SG_ 1313 STH_Geblaese 0;
BA_ "GenSigSendType" SG_ 1313 STH_Heizleistung 0;
BA_ "GenSigSwitchedByIgnition" SG_ 1313 STH_Heizleistung 0;
BA_ "GenSigSendType" SG_ 1313 STH_KL_HUP 0;
BA_ "GenSigSwitchedByIgnition" SG_ 1313 STH_KL_HUP 0;
BA_ "GenSigSendType" SG_ 1313 STH_KVS 0;
BA_ "GenSigSwitchedByIgnition" SG_ 1313 STH_KVS 0;
BA_ "GenSigSendType" SG_ 1313 STH_KVS_Ueberlauf 0;
BA_ "GenSigSwitchedByIgnition" SG_ 1313 STH_KVS_Ueberlauf 0;
BA_ "GenSigSendType" SG_ 1313 STH_LED 0;
BA_ "GenSigSwitchedByIgnition" SG_ 1313 STH_LED 0;
BA_ "GenSigSendType" SG_ 1313 STH_Motorvorwaermung 0;
BA_ "GenSigSwitchedByIgnition" SG_ 1313 STH_Motorvorwaermung 0;
BA_ "GenSigSendType" SG_ 1313 STH_Pumpe_ein 0;
BA_ "GenSigSwitchedByIgnition" SG_ 1313 STH_Pumpe_ein 0;
BA_ "GenSigSendType" SG_ 1313 STH_Pumpen_Anf_extern 0;
BA_ "GenSigSwitchedByIgnition" SG_ 1313 STH_Pumpen_Anf_extern 0;
BA_ "GenSigSendType" SG_ 1313 STH_Servicemode 0;
BA_ "GenSigSwitchedByIgnition" SG_ 1313 STH_Servicemode 0;
BA_ "GenSigSendType" SG_ 1313 STH_SH_ZH 0;
BA_ "GenSigSwitchedByIgnition" SG_ 1313 STH_SH_ZH 0;
BA_ "GenSigSendType" SG_ 1313 STH_Start_folgt 0;
BA_ "GenSigSwitchedByIgnition" SG_ 1313 STH_Start_folgt 0;
BA_ "GenSigSendType" SG_ 1313 STH_Texte 0;
BA_ "GenSigSwitchedByIgnition" SG_ 1313 STH_Texte 0;
BA_ "GenSigSendType" SG_ 1313 STH_Ventil_Status 0;
BA_ "GenSigSwitchedByIgnition" SG_ 1313 STH_Ventil_Status 0;
BA_ "GenSigSendType" SG_ 1313 STH_Ventiloeffnungszeit 0;
BA_ "GenSigSwitchedByIgnition" SG_ 1313 STH_Ventiloeffnungszeit 0;
BA_ "GenSigSendType" SG_ 1313 STH_Waermeeintrag 0;
BA_ "GenSigSwitchedByIgnition" SG_ 1313 STH_Waermeeintrag 0;
BA_ "GenSigSendType" SG_ 1313 STH_war_aktiv 0;
BA_ "GenSigSwitchedByIgnition" SG_ 1313 STH_war_aktiv 0;
BA_ "GenSigSendType" SG_ 1313 STH_Wassertemp 0;
BA_ "GenSigStartValue" SG_ 1313 STH_Wassertemp 254;
BA_ "GenSigSwitchedByIgnition" SG_ 1313 STH_Wassertemp 0;
BA_ "Fehlerwert" SG_ 1313 STH_Wassertemp 255;
BA_ "GenSigSendType" SG_ 1313 STH_Zusatzheizung 0;
BA_ "GenSigSwitchedByIgnition" SG_ 1313 STH_Zusatzheizung 0;
BA_ "GenSigSendType" SG_ 1413 GW_KD_Fehler 3;
BA_ "GenSigSendType" SG_ 1413 SI_BUS_01 3;
BA_ "GenSigStartValue" SG_ 1413 SI_BUS_01 1;
BA_ "GenSigSwitchedByIgnition" SG_ 1413 SI_BUS_01 0;
BA_ "GenSigSendType" SG_ 1413 SI_BUS_02 3;
BA_ "GenSigStartValue" SG_ 1413 SI_BUS_02 1;
BA_ "GenSigSwitchedByIgnition" SG_ 1413 SI_BUS_02 0;
BA_ "GenSigSendType" SG_ 1413 SI_BUS_03 3;
BA_ "GenSigStartValue" SG_ 1413 SI_BUS_03 1;
BA_ "GenSigSwitchedByIgnition" SG_ 1413 SI_BUS_03 0;
BA_ "GenSigSendType" SG_ 1413 SI_BUS_04 3;
BA_ "GenSigStartValue" SG_ 1413 SI_BUS_04 1;
BA_ "GenSigSwitchedByIgnition" SG_ 1413 SI_BUS_04 0;
BA_ "GenSigSendType" SG_ 1413 SI_BUS_05 3;
BA_ "GenSigStartValue" SG_ 1413 SI_BUS_05 1;
BA_ "GenSigSwitchedByIgnition" SG_ 1413 SI_BUS_05 0;
BA_ "GenSigSendType" SG_ 1413 SI_BUS_06 3;
BA_ "GenSigStartValue" SG_ 1413 SI_BUS_06 1;
BA_ "GenSigSwitchedByIgnition" SG_ 1413 SI_BUS_06 0;
BA_ "GenSigSendType" SG_ 1413 SI_BUS_07 3;
BA_ "GenSigStartValue" SG_ 1413 SI_BUS_07 1;
BA_ "GenSigSwitchedByIgnition" SG_ 1413 SI_BUS_07 0;
BA_ "GenSigSendType" SG_ 1413 SI_BUS_08 3;
BA_ "GenSigStartValue" SG_ 1413 SI_BUS_08 1;
BA_ "GenSigSwitchedByIgnition" SG_ 1413 SI_BUS_08 0;
BA_ "GenSigSendType" SG_ 1413 SI_BUS_09 3;
BA_ "GenSigStartValue" SG_ 1413 SI_BUS_09 1;
BA_ "GenSigSwitchedByIgnition" SG_ 1413 SI_BUS_09 0;
BA_ "GenSigSendType" SG_ 1413 SI_BUS_10 3;
BA_ "GenSigStartValue" SG_ 1413 SI_BUS_10 1;
BA_ "GenSigSwitchedByIgnition" SG_ 1413 SI_BUS_10 0;
BA_ "GenSigSendType" SG_ 1413 SI_BUS_11 3;
BA_ "GenSigStartValue" SG_ 1413 SI_BUS_11 1;
BA_ "GenSigSwitchedByIgnition" SG_ 1413 SI_BUS_11 0;
BA_ "GenSigSendType" SG_ 1413 SI_BUS_12 3;
BA_ "GenSigStartValue" SG_ 1413 SI_BUS_12 1;
BA_ "GenSigSwitchedByIgnition" SG_ 1413 SI_BUS_12 0;
BA_ "GenSigSendType" SG_ 1413 SI_BUS_13 3;
BA_ "GenSigStartValue" SG_ 1413 SI_BUS_13 1;
BA_ "GenSigSwitchedByIgnition" SG_ 1413 SI_BUS_13 0;
BA_ "GenSigSendType" SG_ 1413 SI_BUS_14 3;
BA_ "GenSigStartValue" SG_ 1413 SI_BUS_14 1;
BA_ "GenSigSwitchedByIgnition" SG_ 1413 SI_BUS_14 0;
BA_ "GenSigSendType" SG_ 1413 SI_BUS_15 3;
BA_ "GenSigStartValue" SG_ 1413 SI_BUS_15 1;
BA_ "GenSigSwitchedByIgnition" SG_ 1413 SI_BUS_15 0;
BA_ "GenSigSendType" SG_ 1413 SI_Bus_Identifikation 0;
BA_ "GenSigSwitchedByIgnition" SG_ 1413 SI_Bus_Identifikation 0;
BA_ "GenSigSendType" SG_ 1413 SI_CAB_V14 3;
BA_ "GenSigSwitchedByIgnition" SG_ 1413 SI_CAB_V14 0;
BA_ "GenSigSendType" SG_ 1413 SI_Diagnose_Aktiv 3;
BA_ "GenSigSwitchedByIgnition" SG_ 1413 SI_Diagnose_Aktiv 0;
BA_ "GenSigSendType" SG_ 1413 SI_NWDF 3;
BA_ "GenSigSwitchedByIgnition" SG_ 1413 SI_NWDF 0;
BA_ "GenSigSendType" SG_ 1413 SI_NWDF_30 3;
BA_ "GenSigSwitchedByIgnition" SG_ 1413 SI_NWDF_30 0;
BA_ "GenSigSendType" SG_ 1413 SI_NWDF_gueltig 3;
BA_ "GenSigFuncType" SG_ 1413 SI_NWDF_gueltig 8;
BA_ "GenSigSwitchedByIgnition" SG_ 1413 SI_NWDF_gueltig 0;
BA_ "GenSigSendType" SG_ 1413 SI_P_Mode 3;
BA_ "GenSigSwitchedByIgnition" SG_ 1413 SI_P_Mode 0;
BA_ "GenSigSendType" SG_ 1413 SI_P_Mode_gueltig 3;
BA_ "GenSigSwitchedByIgnition" SG_ 1413 SI_P_Mode_gueltig 0;
BA_ "GenSigSendType" SG_ 1413 SI_QRS_Mode 3;
BA_ "GenSigSwitchedByIgnition" SG_ 1413 SI_QRS_Mode 0;
BA_ "GenSigSendType" SG_ 1413 SI_Sammel_SG_Fehler 0;
BA_ "GenSigStartValue" SG_ 1413 SI_Sammel_SG_Fehler 63;
BA_ "GenSigSwitchedByIgnition" SG_ 1413 SI_Sammel_SG_Fehler 0;
BA_ "GenSigSendType" SG_ 1413 SI_Sammelfehler 3;
BA_ "GenSigSwitchedByIgnition" SG_ 1413 SI_Sammelfehler 0;
BA_ "GenSigSendType" SG_ 1413 SI_T_Mode 3;
BA_ "GenSigSwitchedByIgnition" SG_ 1413 SI_T_Mode 0;
BA_ "GenSigSendType" SG_ 1413 SI_T_Schutz 3;
BA_ "GenSigSwitchedByIgnition" SG_ 1413 SI_T_Schutz 0;
BA_ "GenSigSendType" SG_ 2589283571 TLI_LSA1_Data_Age 3;
BA_ "GenSigStartValue" SG_ 2589283571 TLI_LSA1_Data_Age 4094;
BA_ "GenSigSwitchedByIgnition" SG_ 2589283571 TLI_LSA1_Data_Age 0;
BA_ "Fehlerwert" SG_ 2589283571 TLI_LSA1_Data_Age 4095;
BA_ "GenSigSendType" SG_ 2589283571 TLI_LSA1_Data_Source 3;
BA_ "GenSigStartValue" SG_ 2589283571 TLI_LSA1_Data_Source 3;
BA_ "GenSigSwitchedByIgnition" SG_ 2589283571 TLI_LSA1_Data_Source 0;
BA_ "Fehlerwert" SG_ 2589283571 TLI_LSA1_Data_Source 4;
BA_ "GenSigSendType" SG_ 2589283571 TLI_LSA1_Direction_E 3;
BA_ "GenSigStartValue" SG_ 2589283571 TLI_LSA1_Direction_E 2;
BA_ "GenSigSwitchedByIgnition" SG_ 2589283571 TLI_LSA1_Direction_E 0;
BA_ "Fehlerwert" SG_ 2589283571 TLI_LSA1_Direction_E 3;
BA_ "GenSigSendType" SG_ 2589283571 TLI_LSA1_Direction_N 3;
BA_ "GenSigStartValue" SG_ 2589283571 TLI_LSA1_Direction_N 2;
BA_ "GenSigSwitchedByIgnition" SG_ 2589283571 TLI_LSA1_Direction_N 0;
BA_ "Fehlerwert" SG_ 2589283571 TLI_LSA1_Direction_N 3;
BA_ "GenSigSendType" SG_ 2589283571 TLI_LSA1_Direction_NE 3;
BA_ "GenSigStartValue" SG_ 2589283571 TLI_LSA1_Direction_NE 2;
BA_ "GenSigSwitchedByIgnition" SG_ 2589283571 TLI_LSA1_Direction_NE 0;
BA_ "Fehlerwert" SG_ 2589283571 TLI_LSA1_Direction_NE 3;
BA_ "GenSigSendType" SG_ 2589283571 TLI_LSA1_Direction_NW 3;
BA_ "GenSigStartValue" SG_ 2589283571 TLI_LSA1_Direction_NW 2;
BA_ "GenSigSwitchedByIgnition" SG_ 2589283571 TLI_LSA1_Direction_NW 0;
BA_ "Fehlerwert" SG_ 2589283571 TLI_LSA1_Direction_NW 3;
BA_ "GenSigSendType" SG_ 2589283571 TLI_LSA1_Direction_SE 3;
BA_ "GenSigStartValue" SG_ 2589283571 TLI_LSA1_Direction_SE 2;
BA_ "GenSigSwitchedByIgnition" SG_ 2589283571 TLI_LSA1_Direction_SE 0;
BA_ "Fehlerwert" SG_ 2589283571 TLI_LSA1_Direction_SE 3;
BA_ "GenSigSendType" SG_ 2589283571 TLI_LSA1_Direction_SW 3;
BA_ "GenSigStartValue" SG_ 2589283571 TLI_LSA1_Direction_SW 2;
BA_ "GenSigSwitchedByIgnition" SG_ 2589283571 TLI_LSA1_Direction_SW 0;
BA_ "Fehlerwert" SG_ 2589283571 TLI_LSA1_Direction_SW 3;
BA_ "GenSigSendType" SG_ 2589283571 TLI_LSA1_Direction_U_Turn_NE 3;
BA_ "GenSigStartValue" SG_ 2589283571 TLI_LSA1_Direction_U_Turn_NE 2;
BA_ "GenSigSwitchedByIgnition" SG_ 2589283571 TLI_LSA1_Direction_U_Turn_NE 0;
BA_ "Fehlerwert" SG_ 2589283571 TLI_LSA1_Direction_U_Turn_NE 3;
BA_ "GenSigSendType" SG_ 2589283571 TLI_LSA1_Direction_U_Turn_NW 3;
BA_ "GenSigStartValue" SG_ 2589283571 TLI_LSA1_Direction_U_Turn_NW 2;
BA_ "GenSigSwitchedByIgnition" SG_ 2589283571 TLI_LSA1_Direction_U_Turn_NW 0;
BA_ "Fehlerwert" SG_ 2589283571 TLI_LSA1_Direction_U_Turn_NW 3;
BA_ "GenSigSendType" SG_ 2589283571 TLI_LSA1_Direction_W 3;
BA_ "GenSigStartValue" SG_ 2589283571 TLI_LSA1_Direction_W 2;
BA_ "GenSigSwitchedByIgnition" SG_ 2589283571 TLI_LSA1_Direction_W 0;
BA_ "Fehlerwert" SG_ 2589283571 TLI_LSA1_Direction_W 3;
BA_ "GenSigSendType" SG_ 2589283571 TLI_LSA1_Distance_Backlog 3;
BA_ "GenSigStartValue" SG_ 2589283571 TLI_LSA1_Distance_Backlog 510;
BA_ "GenSigSwitchedByIgnition" SG_ 2589283571 TLI_LSA1_Distance_Backlog 0;
BA_ "Fehlerwert" SG_ 2589283571 TLI_LSA1_Distance_Backlog 511;
BA_ "GenSigSendType" SG_ 2589283571 TLI_LSA1_Distance_Stop_Line 3;
BA_ "GenSigStartValue" SG_ 2589283571 TLI_LSA1_Distance_Stop_Line 8190;
BA_ "GenSigSwitchedByIgnition" SG_ 2589283571 TLI_LSA1_Distance_Stop_Line 0;
BA_ "Fehlerwert" SG_ 2589283571 TLI_LSA1_Distance_Stop_Line 8191;
BA_ "GenSigSendType" SG_ 2589283571 TLI_LSA1_GLOSA 3;
BA_ "GenSigStartValue" SG_ 2589283571 TLI_LSA1_GLOSA 254;
BA_ "GenSigSwitchedByIgnition" SG_ 2589283571 TLI_LSA1_GLOSA 0;
BA_ "Fehlerwert" SG_ 2589283571 TLI_LSA1_GLOSA 255;
BA_ "GenSigSendType" SG_ 2589283571 TLI_LSA1_GLOSA_Display 3;
BA_ "GenSigStartValue" SG_ 2589283571 TLI_LSA1_GLOSA_Display 254;
BA_ "GenSigSwitchedByIgnition" SG_ 2589283571 TLI_LSA1_GLOSA_Display 0;
BA_ "Fehlerwert" SG_ 2589283571 TLI_LSA1_GLOSA_Display 255;
BA_ "GenSigSendType" SG_ 2589283571 TLI_LSA1_GLOSA_Unit 3;
BA_ "GenSigStartValue" SG_ 2589283571 TLI_LSA1_GLOSA_Unit 2;
BA_ "GenSigSwitchedByIgnition" SG_ 2589283571 TLI_LSA1_GLOSA_Unit 0;
BA_ "Fehlerwert" SG_ 2589283571 TLI_LSA1_GLOSA_Unit 3;
BA_ "GenSigSendType" SG_ 2589283571 TLI_LSA1_Info_Backlog 3;
BA_ "GenSigStartValue" SG_ 2589283571 TLI_LSA1_Info_Backlog 2;
BA_ "GenSigSwitchedByIgnition" SG_ 2589283571 TLI_LSA1_Info_Backlog 0;
BA_ "Fehlerwert" SG_ 2589283571 TLI_LSA1_Info_Backlog 3;
BA_ "GenSigSendType" SG_ 2589283571 TLI_LSA1_TTG 3;
BA_ "GenSigStartValue" SG_ 2589283571 TLI_LSA1_TTG 254;
BA_ "GenSigSwitchedByIgnition" SG_ 2589283571 TLI_LSA1_TTG 0;
BA_ "Fehlerwert" SG_ 2589283571 TLI_LSA1_TTG 255;
BA_ "GenSigSendType" SG_ 2589283622 TLO_01_Zaehler 3;
BA_ "GenSigSwitchedByIgnition" SG_ 2589283622 TLO_01_Zaehler 0;
BA_ "GenSigSendType" SG_ 2589283622 TLO_HMI_Status 3;
BA_ "GenSigSwitchedByIgnition" SG_ 2589283622 TLO_HMI_Status 0;
BA_ "GenSigSendType" SG_ 2589283622 TLO_LSA1_PSD_Seg_Offset 3;
BA_ "GenSigStartValue" SG_ 2589283622 TLO_LSA1_PSD_Seg_Offset 255;
BA_ "GenSigSwitchedByIgnition" SG_ 2589283622 TLO_LSA1_PSD_Seg_Offset 0;
BA_ "GenSigSendType" SG_ 2589283622 TLO_LSA1_PSD_Segment_ID 3;
BA_ "GenSigSwitchedByIgnition" SG_ 2589283622 TLO_LSA1_PSD_Segment_ID 0;
BA_ "GenSigSendType" SG_ 2589283622 TLO_LSA1_Zeit1_CF 3;
BA_ "GenSigSwitchedByIgnition" SG_ 2589283622 TLO_LSA1_Zeit1_CF 0;
BA_ "GenSigSendType" SG_ 2589283622 TLO_LSA1_Zeit1_Pred 3;
BA_ "GenSigSwitchedByIgnition" SG_ 2589283622 TLO_LSA1_Zeit1_Pred 0;
BA_ "GenSigSendType" SG_ 2589283622 TLO_LSA1_Zeit1_Status 3;
BA_ "GenSigSwitchedByIgnition" SG_ 2589283622 TLO_LSA1_Zeit1_Status 0;
BA_ "GenSigSendType" SG_ 2589283622 TLO_LSA1_Zeit2_CF 3;
BA_ "GenSigSwitchedByIgnition" SG_ 2589283622 TLO_LSA1_Zeit2_CF 0;
BA_ "GenSigSendType" SG_ 2589283622 TLO_LSA1_Zeit2_Pred 3;
BA_ "GenSigSwitchedByIgnition" SG_ 2589283622 TLO_LSA1_Zeit2_Pred 0;
BA_ "GenSigSendType" SG_ 2589283622 TLO_LSA1_Zeit2_Status 3;
BA_ "GenSigSwitchedByIgnition" SG_ 2589283622 TLO_LSA1_Zeit2_Status 0;
BA_ "GenSigSendType" SG_ 2589283622 TLO_StartStoppInfo 3;
BA_ "GenSigSwitchedByIgnition" SG_ 2589283622 TLO_StartStoppInfo 0;
BA_ "GenSigSendType" SG_ 2589283623 TLO_02_Zaehler 3;
BA_ "GenSigSwitchedByIgnition" SG_ 2589283623 TLO_02_Zaehler 0;
BA_ "GenSigSendType" SG_ 2589283623 TLO_LSA1_Layout 3;
BA_ "GenSigSwitchedByIgnition" SG_ 2589283623 TLO_LSA1_Layout 0;
BA_ "GenSigSendType" SG_ 2589283623 TLO_LSA2_PSD_Seg_Offset 3;
BA_ "GenSigStartValue" SG_ 2589283623 TLO_LSA2_PSD_Seg_Offset 255;
BA_ "GenSigSwitchedByIgnition" SG_ 2589283623 TLO_LSA2_PSD_Seg_Offset 0;
BA_ "GenSigSendType" SG_ 2589283623 TLO_LSA2_PSD_Segment_ID 3;
BA_ "GenSigSwitchedByIgnition" SG_ 2589283623 TLO_LSA2_PSD_Segment_ID 0;
BA_ "GenSigSendType" SG_ 2589283623 TLO_LSA2_Zeit1_CF 3;
BA_ "GenSigSwitchedByIgnition" SG_ 2589283623 TLO_LSA2_Zeit1_CF 0;
BA_ "GenSigSendType" SG_ 2589283623 TLO_LSA2_Zeit1_Pred 3;
BA_ "GenSigSwitchedByIgnition" SG_ 2589283623 TLO_LSA2_Zeit1_Pred 0;
BA_ "GenSigSendType" SG_ 2589283623 TLO_LSA2_Zeit1_Status 3;
BA_ "GenSigSwitchedByIgnition" SG_ 2589283623 TLO_LSA2_Zeit1_Status 0;
BA_ "GenSigSendType" SG_ 2589283623 TLO_LSA2_Zeit2_CF 3;
BA_ "GenSigSwitchedByIgnition" SG_ 2589283623 TLO_LSA2_Zeit2_CF 0;
BA_ "GenSigSendType" SG_ 2589283623 TLO_LSA2_Zeit2_Pred 3;
BA_ "GenSigSwitchedByIgnition" SG_ 2589283623 TLO_LSA2_Zeit2_Pred 0;
BA_ "GenSigSendType" SG_ 2589283623 TLO_LSA2_Zeit2_Status 3;
BA_ "GenSigSwitchedByIgnition" SG_ 2589283623 TLO_LSA2_Zeit2_Status 0;
BA_ "GenSigSendType" SG_ 1447 bCall_active 3;
BA_ "GenSigSwitchedByIgnition" SG_ 1447 bCall_active 0;
BA_ "GenSigSendType" SG_ 1447 eCall_Funktionsstatus 0;
BA_ "GenSigSwitchedByIgnition" SG_ 1447 eCall_Funktionsstatus 0;
BA_ "GenSigSendType" SG_ 1447 eCall_Funktionsstatus_02 0;
BA_ "GenSigStartValue" SG_ 1447 eCall_Funktionsstatus_02 7;
BA_ "GenSigSwitchedByIgnition" SG_ 1447 eCall_Funktionsstatus_02 0;
BA_ "GenSigSendType" SG_ 1447 eCall_MCC 0;
BA_ "GenSigSwitchedByIgnition" SG_ 1447 eCall_MCC 0;
BA_ "GenSigSendType" SG_ 1447 eCall_Mute_Anf 3;
BA_ "GenSigSwitchedByIgnition" SG_ 1447 eCall_Mute_Anf 0;
BA_ "GenSigSendType" SG_ 1447 FaceRec_Enroll_Challenge_Request 3;
BA_ "GenSigSwitchedByIgnition" SG_ 1447 FaceRec_Enroll_Challenge_Request 0;
BA_ "GenSigSendType" SG_ 1447 FoD_Anz_Funktionsabschaltung 3;
BA_ "GenSigSwitchedByIgnition" SG_ 1447 FoD_Anz_Funktionsabschaltung 0;
BA_ "GenSigSendType" SG_ 1447 iCall_active 3;
BA_ "GenSigSwitchedByIgnition" SG_ 1447 iCall_active 0;
BA_ "GenSigSendType" SG_ 1447 MOD_Energie_Anf 0;
BA_ "GenSigSwitchedByIgnition" SG_ 1447 MOD_Energie_Anf 0;
BA_ "Fehlerwert" SG_ 1447 MOD_Energie_Anf 3;
BA_ "GenSigSendType" SG_ 1447 MOD_Request_ServiceKey 3;
BA_ "GenSigSwitchedByIgnition" SG_ 1447 MOD_Request_ServiceKey 0;
BA_ "GenSigSendType" SG_ 1447 ORU_KombiTimer 0;
BA_ "GenSigSwitchedByIgnition" SG_ 1447 ORU_KombiTimer 0;
BA_ "GenSigSendType" SG_ 1447 TM_Door_Lock 5;
BA_ "GenSigSwitchedByIgnition" SG_ 1447 TM_Door_Lock 0;
BA_ "GenSigSendType" SG_ 1447 TM_Door_Unlock 5;
BA_ "GenSigSwitchedByIgnition" SG_ 1447 TM_Door_Unlock 0;
BA_ "GenSigSendType" SG_ 1447 TM_Nur_Hupen 5;
BA_ "GenSigSwitchedByIgnition" SG_ 1447 TM_Nur_Hupen 0;
BA_ "GenSigSendType" SG_ 1447 TM_Panik_Alarm 5;
BA_ "GenSigSwitchedByIgnition" SG_ 1447 TM_Panik_Alarm 0;
BA_ "GenSigSendType" SG_ 1447 TM_Spiegel_Anklappen 5;
BA_ "GenSigSwitchedByIgnition" SG_ 1447 TM_Spiegel_Anklappen 0;
BA_ "GenSigSendType" SG_ 1447 TM_Warnblinken 5;
BA_ "GenSigSwitchedByIgnition" SG_ 1447 TM_Warnblinken 0;
BA_ "GenSigSendType" SG_ 1447 TM_ZV_Signatur 0;
BA_ "GenSigSwitchedByIgnition" SG_ 1447 TM_ZV_Signatur 0;
BA_ "GenSigSendType" SG_ 976 ASW_HMI_defekt 0;
BA_ "GenSigSwitchedByIgnition" SG_ 976 ASW_HMI_defekt 0;
BA_ "GenSigSendType" SG_ 976 ASW_wakeup 3;
BA_ "GenSigSwitchedByIgnition" SG_ 976 ASW_wakeup 0;
BA_ "GenSigSendType" SG_ 976 ASW_Warnung_aktiv_FS 3;
BA_ "GenSigSwitchedByIgnition" SG_ 976 ASW_Warnung_aktiv_FS 0;
BA_ "GenSigSendType" SG_ 976 FS_Status_eTAG 3;
BA_ "GenSigSwitchedByIgnition" SG_ 976 FS_Status_eTAG 0;
BA_ "Fehlerwert" SG_ 976 FS_Status_eTAG 3;
BA_ "GenSigSendType" SG_ 976 FT_BFS_Fond_Freigabe 3;
BA_ "GenSigSwitchedByIgnition" SG_ 976 FT_BFS_Fond_Freigabe 0;
BA_ "GenSigSendType" SG_ 976 FT_Daemmglas 3;
BA_ "GenSigSwitchedByIgnition" SG_ 976 FT_Daemmglas 0;
BA_ "GenSigSendType" SG_ 976 FT_FH_Bew_hoch 3;
BA_ "GenSigSwitchedByIgnition" SG_ 976 FT_FH_Bew_hoch 0;
BA_ "GenSigSendType" SG_ 976 FT_FH_Bew_tief 3;
BA_ "GenSigSwitchedByIgnition" SG_ 976 FT_FH_Bew_tief 0;
BA_ "GenSigSendType" SG_ 976 FT_FH_Block 3;
BA_ "GenSigSwitchedByIgnition" SG_ 976 FT_FH_Block 0;
BA_ "GenSigSendType" SG_ 976 FT_FH_Fang 3;
BA_ "GenSigSwitchedByIgnition" SG_ 976 FT_FH_Fang 0;
BA_ "GenSigSendType" SG_ 976 FT_FH_normiert 3;
BA_ "GenSigSwitchedByIgnition" SG_ 976 FT_FH_normiert 0;
BA_ "GenSigSendType" SG_ 976 FT_FH_Oeffnung 3;
BA_ "GenSigSwitchedByIgnition" SG_ 976 FT_FH_Oeffnung 0;
BA_ "GenSigSendType" SG_ 976 FT_FH_Pos_oben 3;
BA_ "GenSigSwitchedByIgnition" SG_ 976 FT_FH_Pos_oben 0;
BA_ "GenSigSendType" SG_ 976 FT_FH_S_AutoHoch 3;
BA_ "GenSigSwitchedByIgnition" SG_ 976 FT_FH_S_AutoHoch 0;
BA_ "GenSigSendType" SG_ 976 FT_FH_S_AutoTief 3;
BA_ "GenSigSwitchedByIgnition" SG_ 976 FT_FH_S_AutoTief 0;
BA_ "GenSigSendType" SG_ 976 FT_FH_S_ManHoch 3;
BA_ "GenSigSwitchedByIgnition" SG_ 976 FT_FH_S_ManHoch 0;
BA_ "GenSigSendType" SG_ 976 FT_FH_S_ManTief 3;
BA_ "GenSigSwitchedByIgnition" SG_ 976 FT_FH_S_ManTief 0;
BA_ "GenSigSendType" SG_ 976 FT_FH_Thermo 3;
BA_ "GenSigSwitchedByIgnition" SG_ 976 FT_FH_Thermo 0;
BA_ "GenSigSendType" SG_ 976 FT_gesafet 3;
BA_ "GenSigSwitchedByIgnition" SG_ 976 FT_gesafet 0;
BA_ "GenSigSendType" SG_ 976 FT_HD_Taste 3;
BA_ "GenSigSwitchedByIgnition" SG_ 976 FT_HD_Taste 0;
BA_ "GenSigSendType" SG_ 976 FT_HD_Taste_2 3;
BA_ "GenSigSwitchedByIgnition" SG_ 976 FT_HD_Taste_2 0;
BA_ "GenSigSendType" SG_ 976 FT_IRUE_Taste 3;
BA_ "GenSigSwitchedByIgnition" SG_ 976 FT_IRUE_Taste 0;
BA_ "GenSigSendType" SG_ 976 FT_Kisi_Fehler 3;
BA_ "GenSigSwitchedByIgnition" SG_ 976 FT_Kisi_Fehler 0;
BA_ "Fehlerwert" SG_ 976 FT_Kisi_Fehler 1;
BA_ "GenSigSendType" SG_ 976 FT_Kisi_li_aktiv 3;
BA_ "GenSigSwitchedByIgnition" SG_ 976 FT_Kisi_li_aktiv 0;
BA_ "GenSigSendType" SG_ 976 FT_Kisi_re_aktiv 3;
BA_ "GenSigSwitchedByIgnition" SG_ 976 FT_Kisi_re_aktiv 0;
BA_ "GenSigSendType" SG_ 976 FT_Kisi_Taster_li 3;
BA_ "GenSigSwitchedByIgnition" SG_ 976 FT_Kisi_Taster_li 0;
BA_ "GenSigSendType" SG_ 976 FT_Kisi_Taster_re 3;
BA_ "GenSigSwitchedByIgnition" SG_ 976 FT_Kisi_Taster_re 0;
BA_ "GenSigSendType" SG_ 976 FT_Lock_Taster 3;
BA_ "GenSigSwitchedByIgnition" SG_ 976 FT_Lock_Taster 0;
BA_ "GenSigSendType" SG_ 976 FT_Lock_Unlock_Taster 3;
BA_ "GenSigSwitchedByIgnition" SG_ 976 FT_Lock_Unlock_Taster 0;
BA_ "GenSigSendType" SG_ 976 FT_Oben_Block_erw 3;
BA_ "GenSigSwitchedByIgnition" SG_ 976 FT_Oben_Block_erw 0;
BA_ "GenSigSendType" SG_ 976 FT_Schliesstaster 3;
BA_ "GenSigSwitchedByIgnition" SG_ 976 FT_Schliesstaster 0;
BA_ "GenSigSendType" SG_ 976 FT_Schluesselschalter_auf 3;
BA_ "GenSigSwitchedByIgnition" SG_ 976 FT_Schluesselschalter_auf 0;
BA_ "GenSigSendType" SG_ 976 FT_Schluesselschalter_zu 3;
BA_ "GenSigSwitchedByIgnition" SG_ 976 FT_Schluesselschalter_zu 0;
BA_ "GenSigSendType" SG_ 976 FT_SP_ausgerastet 3;
BA_ "GenSigSwitchedByIgnition" SG_ 976 FT_SP_ausgerastet 0;
BA_ "GenSigSendType" SG_ 976 FT_Sp_Blk_def 3;
BA_ "GenSigSwitchedByIgnition" SG_ 976 FT_Sp_Blk_def 0;
BA_ "GenSigSendType" SG_ 976 FT_Sp_Heizung_Anf 0;
BA_ "GenSigSwitchedByIgnition" SG_ 976 FT_Sp_Heizung_Anf 0;
BA_ "GenSigSendType" SG_ 976 FT_SP_Heizung_Status 3;
BA_ "GenSigSwitchedByIgnition" SG_ 976 FT_SP_Heizung_Status 0;
BA_ "GenSigSendType" SG_ 976 FT_SP_ht_aktiv 3;
BA_ "GenSigSwitchedByIgnition" SG_ 976 FT_SP_ht_aktiv 0;
BA_ "GenSigSendType" SG_ 976 FT_SP_lr_aktiv 3;
BA_ "GenSigSwitchedByIgnition" SG_ 976 FT_SP_lr_aktiv 0;
BA_ "GenSigSendType" SG_ 976 FT_Sperrklinke 3;
BA_ "GenSigSwitchedByIgnition" SG_ 976 FT_Sperrklinke 0;
BA_ "GenSigSendType" SG_ 976 FT_SWA_Taster 3;
BA_ "GenSigSwitchedByIgnition" SG_ 976 FT_SWA_Taster 0;
BA_ "GenSigSendType" SG_ 976 FT_TAG_betaetigt 3;
BA_ "GenSigSwitchedByIgnition" SG_ 976 FT_TAG_betaetigt 0;
BA_ "GenSigSendType" SG_ 976 FT_TD_Taste 3;
BA_ "GenSigSwitchedByIgnition" SG_ 976 FT_TD_Taste 0;
BA_ "GenSigSendType" SG_ 976 FT_TD_Taste_Fehler 0;
BA_ "GenSigSwitchedByIgnition" SG_ 976 FT_TD_Taste_Fehler 0;
BA_ "GenSigSendType" SG_ 976 FT_TIG_betaetigt 3;
BA_ "GenSigSwitchedByIgnition" SG_ 976 FT_TIG_betaetigt 0;
BA_ "GenSigSendType" SG_ 976 FT_TSG_hinten_verbaut 3;
BA_ "GenSigSwitchedByIgnition" SG_ 976 FT_TSG_hinten_verbaut 0;
BA_ "GenSigSendType" SG_ 976 FT_Tuer_geoeffnet 3;
BA_ "GenSigSwitchedByIgnition" SG_ 976 FT_Tuer_geoeffnet 0;
BA_ "GenSigSendType" SG_ 976 FT_Tuerschloss_defekt 0;
BA_ "GenSigSwitchedByIgnition" SG_ 976 FT_Tuerschloss_defekt 0;
BA_ "GenSigSendType" SG_ 976 FT_UEKB_aktiviert 3;
BA_ "GenSigSwitchedByIgnition" SG_ 976 FT_UEKB_aktiviert 0;
BA_ "GenSigSendType" SG_ 976 FT_Unlock_Taster 3;
BA_ "GenSigSwitchedByIgnition" SG_ 976 FT_Unlock_Taster 0;
BA_ "GenSigSendType" SG_ 976 FT_Unten_Block_erw 3;
BA_ "GenSigSwitchedByIgnition" SG_ 976 FT_Unten_Block_erw 0;
BA_ "GenSigSendType" SG_ 976 FT_verriegelt 3;
BA_ "GenSigSwitchedByIgnition" SG_ 976 FT_verriegelt 0;
BA_ "GenSigSendType" SG_ 976 FT_Zuziehhilfe_aktiv 3;
BA_ "GenSigSwitchedByIgnition" SG_ 976 FT_Zuziehhilfe_aktiv 0;
BA_ "GenSigSendType" SG_ 976 SSR_Temp_Freigabe 0;
BA_ "GenSigSwitchedByIgnition" SG_ 976 SSR_Temp_Freigabe 0;
BA_ "GenSigSendType" SG_ 976 SWA_HMI_Diagnose 0;
BA_ "GenSigSwitchedByIgnition" SG_ 976 SWA_HMI_Diagnose 0;
BA_ "GenSigSendType" SG_ 997 eTAB_FS_Bowdenzug_Auswerfen 3;
BA_ "GenSigSwitchedByIgnition" SG_ 997 eTAB_FS_Bowdenzug_Auswerfen 0;
BA_ "GenSigSendType" SG_ 997 FS_Push_Tuergriff 3;
BA_ "GenSigSwitchedByIgnition" SG_ 997 FS_Push_Tuergriff 0;
BA_ "GenSigSendType" SG_ 997 FS_Status_eTAG_ext 3;
BA_ "GenSigStartValue" SG_ 997 FS_Status_eTAG_ext 3;
BA_ "GenSigSwitchedByIgnition" SG_ 997 FS_Status_eTAG_ext 0;
BA_ "Fehlerwert" SG_ 997 FS_Status_eTAG_ext 4;
BA_ "GenSigSendType" SG_ 997 FT_ASW_Warnton 0;
BA_ "GenSigSwitchedByIgnition" SG_ 997 FT_ASW_Warnton 0;
BA_ "Fehlerwert" SG_ 997 FT_ASW_Warnton 3;
BA_ "GenSigSendType" SG_ 997 FT_BFS_Tuer_Status 3;
BA_ "GenSigSwitchedByIgnition" SG_ 997 FT_BFS_Tuer_Status 0;
BA_ "Fehlerwert" SG_ 997 FT_BFS_Tuer_Status 3;
BA_ "GenSigSendType" SG_ 997 FT_Cargolock_bet 3;
BA_ "GenSigSwitchedByIgnition" SG_ 997 FT_Cargolock_bet 0;
BA_ "GenSigSendType" SG_ 997 FT_HBFS_Tuer_Status 3;
BA_ "GenSigSwitchedByIgnition" SG_ 997 FT_HBFS_Tuer_Status 0;
BA_ "Fehlerwert" SG_ 997 FT_HBFS_Tuer_Status 3;
BA_ "GenSigSendType" SG_ 997 FT_HFS_Tuer_Status 3;
BA_ "GenSigSwitchedByIgnition" SG_ 997 FT_HFS_Tuer_Status 0;
BA_ "Fehlerwert" SG_ 997 FT_HFS_Tuer_Status 3;
BA_ "GenSigSendType" SG_ 997 FT_kisi_asynchron 3;
BA_ "GenSigSwitchedByIgnition" SG_ 997 FT_kisi_asynchron 0;
BA_ "GenSigSendType" SG_ 997 FT_KiSi_Status_Soll_HBFS 0;
BA_ "GenSigSwitchedByIgnition" SG_ 997 FT_KiSi_Status_Soll_HBFS 0;
BA_ "GenSigSendType" SG_ 997 FT_KiSi_Status_Soll_HFS 0;
BA_ "GenSigSwitchedByIgnition" SG_ 997 FT_KiSi_Status_Soll_HFS 0;
BA_ "GenSigSendType" SG_ 997 FT_Kisi_Taster_li_02 3;
BA_ "GenSigSwitchedByIgnition" SG_ 997 FT_Kisi_Taster_li_02 0;
BA_ "GenSigSendType" SG_ 997 FT_Kisi_Taster_re_02 3;
BA_ "GenSigSwitchedByIgnition" SG_ 997 FT_Kisi_Taster_re_02 0;
BA_ "GenSigSendType" SG_ 997 FT_Lock_Taster_02 0;
BA_ "GenSigSwitchedByIgnition" SG_ 997 FT_Lock_Taster_02 0;
BA_ "GenSigSendType" SG_ 997 FT_Schluesselschalter_zu_02 0;
BA_ "GenSigSwitchedByIgnition" SG_ 997 FT_Schluesselschalter_zu_02 0;
BA_ "GenSigSendType" SG_ 997 FT_SP_Heizung_ein 3;
BA_ "GenSigSwitchedByIgnition" SG_ 997 FT_SP_Heizung_ein 0;
BA_ "GenSigSendType" SG_ 997 FT_TCR_Mode_aktiv 3;
BA_ "GenSigSwitchedByIgnition" SG_ 997 FT_TCR_Mode_aktiv 0;
BA_ "GenSigSendType" SG_ 997 FT_TD_Taste_Status 3;
BA_ "GenSigSwitchedByIgnition" SG_ 997 FT_TD_Taste_Status 0;
BA_ "GenSigSendType" SG_ 997 FT_Tuer_Status 3;
BA_ "GenSigSwitchedByIgnition" SG_ 997 FT_Tuer_Status 0;
BA_ "Fehlerwert" SG_ 997 FT_Tuer_Status 3;
BA_ "GenSigSendType" SG_ 997 FT_Tuer_Status_QBit 0;
BA_ "GenSigSwitchedByIgnition" SG_ 997 FT_Tuer_Status_QBit 0;
BA_ "GenSigSendType" SG_ 997 FT_Tueroeffnen_Warnung 3;
BA_ "GenSigSwitchedByIgnition" SG_ 997 FT_Tueroeffnen_Warnung 0;
BA_ "GenSigSendType" SG_ 997 SSA_FT_ASW_Status 3;
BA_ "GenSigSwitchedByIgnition" SG_ 997 SSA_FT_ASW_Status 0;
BA_ "GenSigSendType" SG_ 997 TBF_FS_Touch_Event 3;
BA_ "GenSigSwitchedByIgnition" SG_ 997 TBF_FS_Touch_Event 0;
BA_ "GenSigSendType" SG_ 997 TSG_FS_Spiegel_angeklappt 3;
BA_ "GenSigSwitchedByIgnition" SG_ 997 TSG_FS_Spiegel_angeklappt 0;
BA_ "GenSigSendType" SG_ 997 TSG_FT_02_BZ 0;
BA_ "GenSigFuncType" SG_ 997 TSG_FT_02_BZ 1;
BA_ "GenSigSwitchedByIgnition" SG_ 997 TSG_FT_02_BZ 0;
BA_ "GenSigSendType" SG_ 997 TSG_FT_02_CRC 0;
BA_ "GenSigFuncType" SG_ 997 TSG_FT_02_CRC 2;
BA_ "GenSigSwitchedByIgnition" SG_ 997 TSG_FT_02_CRC 0;
BA_ "GenSigSendType" SG_ 2589283396 TSK_vMax_EfficiencyMode1 0;
BA_ "GenSigStartValue" SG_ 2589283396 TSK_vMax_EfficiencyMode1 255;
BA_ "GenSigSendType" SG_ 2589283396 TSK_vMax_EfficiencyMode2 0;
BA_ "GenSigStartValue" SG_ 2589283396 TSK_vMax_EfficiencyMode2 255;
BA_ "GenSigSendType" SG_ 2589283396 TSK_vMax_StandardMode 0;
BA_ "GenSigStartValue" SG_ 2589283396 TSK_vMax_StandardMode 255;
BA_ "GenSigSendType" SG_ 1019 TSK_Ausrollkurve_Mux 0;
BA_ "GenSigSwitchedByIgnition" SG_ 1019 TSK_Ausrollkurve_Mux 0;
BA_ "GenSigSendType" SG_ 1019 TSK_Ausrollkurve_Reku 0;
BA_ "GenSigSwitchedByIgnition" SG_ 1019 TSK_Ausrollkurve_Reku 0;
BA_ "GenSigSendType" SG_ 1019 TSK_Ausrollkurve_Schrittweite 0;
BA_ "GenSigSwitchedByIgnition" SG_ 1019 TSK_Ausrollkurve_Schrittweite 0;
BA_ "GenSigStartValue" SG_ 1019 TSK_Ausrollkurve_Schub_Reku_01 127;
BA_ "GenSigSwitchedByIgnition" SG_ 1019 TSK_Ausrollkurve_Schub_Reku_01 0;
BA_ "GenSigStartValue" SG_ 1019 TSK_Ausrollkurve_Schub_Reku_02 127;
BA_ "GenSigSwitchedByIgnition" SG_ 1019 TSK_Ausrollkurve_Schub_Reku_02 0;
BA_ "GenSigStartValue" SG_ 1019 TSK_Ausrollkurve_Schub_Reku_03 127;
BA_ "GenSigSwitchedByIgnition" SG_ 1019 TSK_Ausrollkurve_Schub_Reku_03 0;
BA_ "GenSigStartValue" SG_ 1019 TSK_Ausrollkurve_Schub_Reku_04 127;
BA_ "GenSigSwitchedByIgnition" SG_ 1019 TSK_Ausrollkurve_Schub_Reku_04 0;
BA_ "GenSigStartValue" SG_ 1019 TSK_Ausrollkurve_Schub_Reku_05 127;
BA_ "GenSigSwitchedByIgnition" SG_ 1019 TSK_Ausrollkurve_Schub_Reku_05 0;
BA_ "GenSigStartValue" SG_ 1019 TSK_Ausrollkurve_Schub_Reku_06 127;
BA_ "GenSigSwitchedByIgnition" SG_ 1019 TSK_Ausrollkurve_Schub_Reku_06 0;
BA_ "GenSigStartValue" SG_ 1019 TSK_Ausrollkurve_Schub_Reku_07 127;
BA_ "GenSigSwitchedByIgnition" SG_ 1019 TSK_Ausrollkurve_Schub_Reku_07 0;
BA_ "GenSigStartValue" SG_ 1019 TSK_Ausrollkurve_Schub_Reku_08 127;
BA_ "GenSigSwitchedByIgnition" SG_ 1019 TSK_Ausrollkurve_Schub_Reku_08 0;
BA_ "GenSigStartValue" SG_ 1019 TSK_Ausrollkurve_Schub_Reku_09 127;
BA_ "GenSigSwitchedByIgnition" SG_ 1019 TSK_Ausrollkurve_Schub_Reku_09 0;
BA_ "GenSigStartValue" SG_ 1019 TSK_Ausrollkurve_Schub_Reku_10 127;
BA_ "GenSigSwitchedByIgnition" SG_ 1019 TSK_Ausrollkurve_Schub_Reku_10 0;
BA_ "GenSigStartValue" SG_ 1019 TSK_Ausrollkurve_Schub_Reku_11 127;
BA_ "GenSigSwitchedByIgnition" SG_ 1019 TSK_Ausrollkurve_Schub_Reku_11 0;
BA_ "GenSigStartValue" SG_ 1019 TSK_Ausrollkurve_Schub_Reku_12 127;
BA_ "GenSigSwitchedByIgnition" SG_ 1019 TSK_Ausrollkurve_Schub_Reku_12 0;
BA_ "GenSigStartValue" SG_ 1019 TSK_Ausrollkurve_Schub_Reku_13 127;
BA_ "GenSigSwitchedByIgnition" SG_ 1019 TSK_Ausrollkurve_Schub_Reku_13 0;
BA_ "GenSigStartValue" SG_ 1019 TSK_Ausrollkurve_Schub_Reku_14 127;
BA_ "GenSigSwitchedByIgnition" SG_ 1019 TSK_Ausrollkurve_Schub_Reku_14 0;
BA_ "GenSigStartValue" SG_ 1019 TSK_Ausrollkurve_Schub_Reku_15 127;
BA_ "GenSigSwitchedByIgnition" SG_ 1019 TSK_Ausrollkurve_Schub_Reku_15 0;
BA_ "GenSigStartValue" SG_ 1019 TSK_Ausrollkurve_Schub_Reku_16 127;
BA_ "GenSigSwitchedByIgnition" SG_ 1019 TSK_Ausrollkurve_Schub_Reku_16 0;
BA_ "GenSigStartValue" SG_ 1019 TSK_Ausrollkurve_Schub_Reku_17 127;
BA_ "GenSigSwitchedByIgnition" SG_ 1019 TSK_Ausrollkurve_Schub_Reku_17 0;
BA_ "GenSigStartValue" SG_ 1019 TSK_Ausrollkurve_Schub_Reku_18 127;
BA_ "GenSigSwitchedByIgnition" SG_ 1019 TSK_Ausrollkurve_Schub_Reku_18 0;
BA_ "GenSigStartValue" SG_ 1019 TSK_Ausrollkurve_Schub_Reku_19 127;
BA_ "GenSigSwitchedByIgnition" SG_ 1019 TSK_Ausrollkurve_Schub_Reku_19 0;
BA_ "GenSigStartValue" SG_ 1019 TSK_Ausrollkurve_Schub_Reku_20 127;
BA_ "GenSigSwitchedByIgnition" SG_ 1019 TSK_Ausrollkurve_Schub_Reku_20 0;
BA_ "GenSigStartValue" SG_ 1019 TSK_Ausrollkurve_Segeln_01 127;
BA_ "GenSigSwitchedByIgnition" SG_ 1019 TSK_Ausrollkurve_Segeln_01 0;
BA_ "GenSigStartValue" SG_ 1019 TSK_Ausrollkurve_Segeln_02 127;
BA_ "GenSigSwitchedByIgnition" SG_ 1019 TSK_Ausrollkurve_Segeln_02 0;
BA_ "GenSigStartValue" SG_ 1019 TSK_Ausrollkurve_Segeln_03 127;
BA_ "GenSigSwitchedByIgnition" SG_ 1019 TSK_Ausrollkurve_Segeln_03 0;
BA_ "GenSigStartValue" SG_ 1019 TSK_Ausrollkurve_Segeln_04 127;
BA_ "GenSigSwitchedByIgnition" SG_ 1019 TSK_Ausrollkurve_Segeln_04 0;
BA_ "GenSigStartValue" SG_ 1019 TSK_Ausrollkurve_Segeln_05 127;
BA_ "GenSigSwitchedByIgnition" SG_ 1019 TSK_Ausrollkurve_Segeln_05 0;
BA_ "GenSigStartValue" SG_ 1019 TSK_Ausrollkurve_Segeln_06 127;
BA_ "GenSigSwitchedByIgnition" SG_ 1019 TSK_Ausrollkurve_Segeln_06 0;
BA_ "GenSigStartValue" SG_ 1019 TSK_Ausrollkurve_Segeln_07 127;
BA_ "GenSigSwitchedByIgnition" SG_ 1019 TSK_Ausrollkurve_Segeln_07 0;
BA_ "GenSigStartValue" SG_ 1019 TSK_Ausrollkurve_Segeln_08 127;
BA_ "GenSigSwitchedByIgnition" SG_ 1019 TSK_Ausrollkurve_Segeln_08 0;
BA_ "GenSigStartValue" SG_ 1019 TSK_Ausrollkurve_Segeln_09 127;
BA_ "GenSigSwitchedByIgnition" SG_ 1019 TSK_Ausrollkurve_Segeln_09 0;
BA_ "GenSigStartValue" SG_ 1019 TSK_Ausrollkurve_Segeln_10 127;
BA_ "GenSigSwitchedByIgnition" SG_ 1019 TSK_Ausrollkurve_Segeln_10 0;
BA_ "GenSigStartValue" SG_ 1019 TSK_Ausrollkurve_Segeln_11 127;
BA_ "GenSigSwitchedByIgnition" SG_ 1019 TSK_Ausrollkurve_Segeln_11 0;
BA_ "GenSigStartValue" SG_ 1019 TSK_Ausrollkurve_Segeln_12 127;
BA_ "GenSigSwitchedByIgnition" SG_ 1019 TSK_Ausrollkurve_Segeln_12 0;
BA_ "GenSigStartValue" SG_ 1019 TSK_Ausrollkurve_Segeln_13 127;
BA_ "GenSigSwitchedByIgnition" SG_ 1019 TSK_Ausrollkurve_Segeln_13 0;
BA_ "GenSigStartValue" SG_ 1019 TSK_Ausrollkurve_Segeln_14 127;
BA_ "GenSigSwitchedByIgnition" SG_ 1019 TSK_Ausrollkurve_Segeln_14 0;
BA_ "GenSigStartValue" SG_ 1019 TSK_Ausrollkurve_Segeln_15 127;
BA_ "GenSigSwitchedByIgnition" SG_ 1019 TSK_Ausrollkurve_Segeln_15 0;
BA_ "GenSigStartValue" SG_ 1019 TSK_Ausrollkurve_Segeln_16 127;
BA_ "GenSigSwitchedByIgnition" SG_ 1019 TSK_Ausrollkurve_Segeln_16 0;
BA_ "GenSigStartValue" SG_ 1019 TSK_Ausrollkurve_Segeln_17 127;
BA_ "GenSigSwitchedByIgnition" SG_ 1019 TSK_Ausrollkurve_Segeln_17 0;
BA_ "GenSigStartValue" SG_ 1019 TSK_Ausrollkurve_Segeln_18 127;
BA_ "GenSigSwitchedByIgnition" SG_ 1019 TSK_Ausrollkurve_Segeln_18 0;
BA_ "GenSigStartValue" SG_ 1019 TSK_Ausrollkurve_Segeln_19 127;
BA_ "GenSigSwitchedByIgnition" SG_ 1019 TSK_Ausrollkurve_Segeln_19 0;
BA_ "GenSigStartValue" SG_ 1019 TSK_Ausrollkurve_Segeln_20 127;
BA_ "GenSigSwitchedByIgnition" SG_ 1019 TSK_Ausrollkurve_Segeln_20 0;
BA_ "GenSigSendType" SG_ 1019 TSK_Ausrollkurve_Zaehler 0;
BA_ "GenSigSwitchedByIgnition" SG_ 1019 TSK_Ausrollkurve_Zaehler 0;
BA_ "GenSigSendType" SG_ 2463978710 OPS_ComfortReadyStatus 4;
BA_ "GenSigSwitchedByIgnition" SG_ 2463978710 OPS_ComfortReadyStatus 0;
BA_ "Fehlerwert" SG_ 2463978710 OPS_ComfortReadyStatus 3;
BA_ "GenSigSendType" SG_ 2463978710 OPS_DriverPresenceStatus 4;
BA_ "GenSigSwitchedByIgnition" SG_ 2463978710 OPS_DriverPresenceStatus 0;
BA_ "Fehlerwert" SG_ 2463978710 OPS_DriverPresenceStatus 15;
BA_ "GenSigSendType" SG_ 2463978710 OPS_OccupantPresenceStatus 4;
BA_ "GenSigSwitchedByIgnition" SG_ 2463978710 OPS_OccupantPresenceStatus 0;
BA_ "Fehlerwert" SG_ 2463978710 OPS_OccupantPresenceStatus 7;
BA_ "GenSigSendType" SG_ 2463978710 OPS_QBit_DriverPresence 4;
BA_ "GenSigStartValue" SG_ 2463978710 OPS_QBit_DriverPresence 1;
BA_ "GenSigSwitchedByIgnition" SG_ 2463978710 OPS_QBit_DriverPresence 0;
BA_ "GenSigSendType" SG_ 2463978710 OPS_SafeDriverPresence_available 4;
BA_ "GenSigSwitchedByIgnition" SG_ 2463978710 OPS_SafeDriverPresence_available 0;
BA_ "GenSigSendType" SG_ 2463978710 OPS_SafeDriverPresenceStatus 4;
BA_ "GenSigSwitchedByIgnition" SG_ 2463978710 OPS_SafeDriverPresenceStatus 0;
BA_ "Fehlerwert" SG_ 2463978710 OPS_SafeDriverPresenceStatus 3;
BA_ "GenSigSendType" SG_ 2463978710 UserStateServer_01_BZ 0;
BA_ "GenSigFuncType" SG_ 2463978710 UserStateServer_01_BZ 1;
BA_ "GenSigSwitchedByIgnition" SG_ 2463978710 UserStateServer_01_BZ 0;
BA_ "GenSigSendType" SG_ 2463978710 UserStateServer_01_CRC 0;
BA_ "GenSigFuncType" SG_ 2463978710 UserStateServer_01_CRC 2;
BA_ "GenSigSwitchedByIgnition" SG_ 2463978710 UserStateServer_01_CRC 0;
BA_ "GenSigSendType" SG_ 995 VD_SpannungsAnf 3;
BA_ "GenSigSwitchedByIgnition" SG_ 995 VD_SpannungsAnf 0;
BA_ "GenSigActiveRepetitions" SG_ 995 VS_BFS_AutoHoch 5;
BA_ "GenSigSendType" SG_ 995 VS_BFS_AutoHoch 4;
BA_ "GenSigSwitchedByIgnition" SG_ 995 VS_BFS_AutoHoch 0;
BA_ "GenSigActiveRepetitions" SG_ 995 VS_BFS_AutoTief 5;
BA_ "GenSigSendType" SG_ 995 VS_BFS_AutoTief 4;
BA_ "GenSigSwitchedByIgnition" SG_ 995 VS_BFS_AutoTief 0;
BA_ "GenSigActiveRepetitions" SG_ 995 VS_BFS_ManHoch 5;
BA_ "GenSigSendType" SG_ 995 VS_BFS_ManHoch 4;
BA_ "GenSigSwitchedByIgnition" SG_ 995 VS_BFS_ManHoch 0;
BA_ "GenSigActiveRepetitions" SG_ 995 VS_BFS_ManTief 5;
BA_ "GenSigSendType" SG_ 995 VS_BFS_ManTief 4;
BA_ "GenSigSwitchedByIgnition" SG_ 995 VS_BFS_ManTief 0;
BA_ "GenSigSendType" SG_ 995 VS_Buzzer 3;
BA_ "GenSigSwitchedByIgnition" SG_ 995 VS_Buzzer 0;
BA_ "GenSigSendType" SG_ 995 VS_FH_BT_Langhub 3;
BA_ "GenSigSwitchedByIgnition" SG_ 995 VS_FH_BT_Langhub 0;
BA_ "GenSigSendType" SG_ 995 VS_FH_FT_Langhub 3;
BA_ "GenSigSwitchedByIgnition" SG_ 995 VS_FH_FT_Langhub 0;
BA_ "GenSigSendType" SG_ 995 VS_FH_HBFS_Langhub 3;
BA_ "GenSigSwitchedByIgnition" SG_ 995 VS_FH_HBFS_Langhub 0;
BA_ "GenSigSendType" SG_ 995 VS_FH_HFS_Langhub 3;
BA_ "GenSigSwitchedByIgnition" SG_ 995 VS_FH_HFS_Langhub 0;
BA_ "GenSigActiveRepetitions" SG_ 995 VS_FS_AutoHoch 5;
BA_ "GenSigSendType" SG_ 995 VS_FS_AutoHoch 4;
BA_ "GenSigSwitchedByIgnition" SG_ 995 VS_FS_AutoHoch 0;
BA_ "GenSigActiveRepetitions" SG_ 995 VS_FS_AutoTief 5;
BA_ "GenSigSendType" SG_ 995 VS_FS_AutoTief 4;
BA_ "GenSigSwitchedByIgnition" SG_ 995 VS_FS_AutoTief 0;
BA_ "GenSigActiveRepetitions" SG_ 995 VS_FS_ManHoch 5;
BA_ "GenSigSendType" SG_ 995 VS_FS_ManHoch 4;
BA_ "GenSigSwitchedByIgnition" SG_ 995 VS_FS_ManHoch 0;
BA_ "GenSigActiveRepetitions" SG_ 995 VS_FS_ManTief 5;
BA_ "GenSigSendType" SG_ 995 VS_FS_ManTief 4;
BA_ "GenSigSwitchedByIgnition" SG_ 995 VS_FS_ManTief 0;
BA_ "GenSigSendType" SG_ 995 VS_Hardtop 3;
BA_ "GenSigSwitchedByIgnition" SG_ 995 VS_Hardtop 0;
BA_ "GenSigActiveRepetitions" SG_ 995 VS_HBFS_AutoHoch 5;
BA_ "GenSigSendType" SG_ 995 VS_HBFS_AutoHoch 4;
BA_ "GenSigSwitchedByIgnition" SG_ 995 VS_HBFS_AutoHoch 0;
BA_ "GenSigActiveRepetitions" SG_ 995 VS_HBFS_AutoTief 5;
BA_ "GenSigSendType" SG_ 995 VS_HBFS_AutoTief 4;
BA_ "GenSigSwitchedByIgnition" SG_ 995 VS_HBFS_AutoTief 0;
BA_ "GenSigActiveRepetitions" SG_ 995 VS_HBFS_ManHoch 5;
BA_ "GenSigSendType" SG_ 995 VS_HBFS_ManHoch 4;
BA_ "GenSigSwitchedByIgnition" SG_ 995 VS_HBFS_ManHoch 0;
BA_ "GenSigActiveRepetitions" SG_ 995 VS_HBFS_ManTief 5;
BA_ "GenSigSendType" SG_ 995 VS_HBFS_ManTief 4;
BA_ "GenSigSwitchedByIgnition" SG_ 995 VS_HBFS_ManTief 0;
BA_ "GenSigSendType" SG_ 995 VS_HD_sperren 3;
BA_ "GenSigSwitchedByIgnition" SG_ 995 VS_HD_sperren 0;
BA_ "GenSigSendType" SG_ 995 VS_Heckschloss_auf 3;
BA_ "GenSigSwitchedByIgnition" SG_ 995 VS_Heckschloss_auf 0;
BA_ "GenSigActiveRepetitions" SG_ 995 VS_HFS_AutoHoch 5;
BA_ "GenSigSendType" SG_ 995 VS_HFS_AutoHoch 4;
BA_ "GenSigSwitchedByIgnition" SG_ 995 VS_HFS_AutoHoch 0;
BA_ "GenSigActiveRepetitions" SG_ 995 VS_HFS_AutoTief 5;
BA_ "GenSigSendType" SG_ 995 VS_HFS_AutoTief 4;
BA_ "GenSigSwitchedByIgnition" SG_ 995 VS_HFS_AutoTief 0;
BA_ "GenSigActiveRepetitions" SG_ 995 VS_HFS_ManHoch 5;
BA_ "GenSigSendType" SG_ 995 VS_HFS_ManHoch 4;
BA_ "GenSigSwitchedByIgnition" SG_ 995 VS_HFS_ManHoch 0;
BA_ "GenSigActiveRepetitions" SG_ 995 VS_HFS_ManTief 5;
BA_ "GenSigSendType" SG_ 995 VS_HFS_ManTief 4;
BA_ "GenSigSwitchedByIgnition" SG_ 995 VS_HFS_ManTief 0;
BA_ "GenSigSendType" SG_ 995 VS_HHS_enable 3;
BA_ "GenSigSwitchedByIgnition" SG_ 995 VS_HHS_enable 0;
BA_ "GenSigSendType" SG_ 995 VS_Lampe_Blk 3;
BA_ "GenSigSwitchedByIgnition" SG_ 995 VS_Lampe_Blk 0;
BA_ "GenSigSendType" SG_ 995 VS_StartStopp_Info 3;
BA_ "GenSigSwitchedByIgnition" SG_ 995 VS_StartStopp_Info 0;
BA_ "Fehlerwert" SG_ 995 VS_StartStopp_Info 3;
BA_ "GenSigSendType" SG_ 995 VS_VD_Bew_auf 3;
BA_ "GenSigSwitchedByIgnition" SG_ 995 VS_VD_Bew_auf 0;
BA_ "GenSigSendType" SG_ 995 VS_VD_Bew_zu 3;
BA_ "GenSigSwitchedByIgnition" SG_ 995 VS_VD_Bew_zu 0;
BA_ "GenSigSendType" SG_ 995 VS_VD_entriegelt 3;
BA_ "GenSigSwitchedByIgnition" SG_ 995 VS_VD_entriegelt 0;
BA_ "GenSigSendType" SG_ 995 VS_VD_Fehler 3;
BA_ "GenSigSwitchedByIgnition" SG_ 995 VS_VD_Fehler 0;
BA_ "GenSigSendType" SG_ 995 VS_VD_offen_ver 3;
BA_ "GenSigSwitchedByIgnition" SG_ 995 VS_VD_offen_ver 0;
BA_ "GenSigSendType" SG_ 995 VS_VD_zu_ver 3;
BA_ "GenSigSwitchedByIgnition" SG_ 995 VS_VD_zu_ver 0;
BA_ "GenSigSendType" SG_ 995 VS_VD_Zwischenposition 3;
BA_ "GenSigSwitchedByIgnition" SG_ 995 VS_VD_Zwischenposition 0;
BA_ "GenSigSendType" SG_ 995 VS_VDKD_auf 3;
BA_ "GenSigSwitchedByIgnition" SG_ 995 VS_VDKD_auf 0;
BA_ "GenSigSendType" SG_ 995 VS_Verdeck_Anf 3;
BA_ "GenSigSwitchedByIgnition" SG_ 995 VS_Verdeck_Anf 0;
BA_ "GenSigSendType" SG_ 995 VS_Windschott_nicht_abgelegt 3;
BA_ "GenSigSwitchedByIgnition" SG_ 995 VS_Windschott_nicht_abgelegt 0;
BA_ "GenSigSendType" SG_ 995 VSG_Meldungen 3;
BA_ "GenSigSwitchedByIgnition" SG_ 995 VSG_Meldungen 0;
BA_ "GenSigSwitchedByIgnition" SG_ 1716 KS_Geheimnis_1 0;
BA_ "GenSigSwitchedByIgnition" SG_ 1716 KS_Geheimnis_2 0;
BA_ "GenSigSwitchedByIgnition" SG_ 1716 KS_Geheimnis_3 0;
BA_ "GenSigSwitchedByIgnition" SG_ 1716 KS_Geheimnis_4 0;
BA_ "GenSigSendType" SG_ 1716 VIN_01_MUX 0;
BA_ "GenSigSwitchedByIgnition" SG_ 1716 VIN_01_MUX 0;
BA_ "GenSigStartValue" SG_ 1716 VIN_1 45;
BA_ "GenSigSwitchedByIgnition" SG_ 1716 VIN_1 0;
BA_ "GenSigStartValue" SG_ 1716 VIN_10 45;
BA_ "GenSigSwitchedByIgnition" SG_ 1716 VIN_10 0;
BA_ "GenSigStartValue" SG_ 1716 VIN_11 45;
BA_ "GenSigSwitchedByIgnition" SG_ 1716 VIN_11 0;
BA_ "GenSigStartValue" SG_ 1716 VIN_12 45;
BA_ "GenSigSwitchedByIgnition" SG_ 1716 VIN_12 0;
BA_ "GenSigStartValue" SG_ 1716 VIN_13 45;
BA_ "GenSigSwitchedByIgnition" SG_ 1716 VIN_13 0;
BA_ "GenSigStartValue" SG_ 1716 VIN_14 45;
BA_ "GenSigSwitchedByIgnition" SG_ 1716 VIN_14 0;
BA_ "GenSigStartValue" SG_ 1716 VIN_15 45;
BA_ "GenSigSwitchedByIgnition" SG_ 1716 VIN_15 0;
BA_ "GenSigStartValue" SG_ 1716 VIN_16 45;
BA_ "GenSigSwitchedByIgnition" SG_ 1716 VIN_16 0;
BA_ "GenSigStartValue" SG_ 1716 VIN_17 45;
BA_ "GenSigSwitchedByIgnition" SG_ 1716 VIN_17 0;
BA_ "GenSigStartValue" SG_ 1716 VIN_2 45;
BA_ "GenSigSwitchedByIgnition" SG_ 1716 VIN_2 0;
BA_ "GenSigStartValue" SG_ 1716 VIN_3 45;
BA_ "GenSigSwitchedByIgnition" SG_ 1716 VIN_3 0;
BA_ "GenSigStartValue" SG_ 1716 VIN_4 45;
BA_ "GenSigSwitchedByIgnition" SG_ 1716 VIN_4 0;
BA_ "GenSigStartValue" SG_ 1716 VIN_5 45;
BA_ "GenSigSwitchedByIgnition" SG_ 1716 VIN_5 0;
BA_ "GenSigStartValue" SG_ 1716 VIN_6 45;
BA_ "GenSigSwitchedByIgnition" SG_ 1716 VIN_6 0;
BA_ "GenSigStartValue" SG_ 1716 VIN_7 45;
BA_ "GenSigSwitchedByIgnition" SG_ 1716 VIN_7 0;
BA_ "GenSigStartValue" SG_ 1716 VIN_8 45;
BA_ "GenSigSwitchedByIgnition" SG_ 1716 VIN_8 0;
BA_ "GenSigStartValue" SG_ 1716 VIN_9 45;
BA_ "GenSigSwitchedByIgnition" SG_ 1716 VIN_9 0;
BA_REL_ "GenSigTimeoutTime" BU_SG_REL_ Gateway_Max SG_ 2589283396 TSK_vMax_EfficiencyMode1 5000;
BA_REL_ "GenSigTimeoutTime" BU_SG_REL_ Gateway_Max SG_ 2589283396 TSK_vMax_EfficiencyMode2 5000;
BA_REL_ "GenSigTimeoutTime" BU_SG_REL_ Gateway_Max SG_ 2589283396 TSK_vMax_StandardMode 5000;
BA_REL_ "GenSigTimeoutTime" BU_SG_REL_ Getriebe_DQ SG_ 1413 SI_P_Mode_gueltig 5000;
BA_REL_ "GenSigTimeoutTime" BU_SG_REL_ Getriebe_DQ SG_ 1413 SI_QRS_Mode 5000;
BA_REL_ "GenSigTimeoutTime" BU_SG_REL_ Getriebe_DQ SG_ 1413 SI_T_Mode 5000;
BA_REL_ "GenSigTimeoutTime" BU_SG_REL_ Getriebe_DQ SG_ 1413 SI_NWDF 5000;
BA_REL_ "GenSigTimeoutTime" BU_SG_REL_ Getriebe_DQ SG_ 1413 SI_NWDF_gueltig 5000;
BA_REL_ "GenSigTimeoutTime" BU_SG_REL_ Getriebe_DQ SG_ 1413 SI_T_Schutz 5000;
BA_REL_ "GenSigTimeoutTime" BU_SG_REL_ Getriebe_DQ SG_ 1413 SI_P_Mode 5000;
BA_REL_ "GenSigTimeoutTime" BU_SG_REL_ Getriebe_DQ SG_ 1413 SI_BUS_02 5000;
BA_REL_ "GenSigTimeoutTime" BU_SG_REL_ Getriebe_DQ SG_ 1413 SI_BUS_03 5000;
BA_REL_ "GenSigTimeoutTime" BU_SG_REL_ Getriebe_DQ SG_ 1413 SI_BUS_06 5000;
BA_REL_ "GenSigTimeoutTime" BU_SG_REL_ Getriebe_DQ SG_ 2463978710 UserStateServer_01_CRC 1000;
BA_REL_ "GenSigTimeoutTime" BU_SG_REL_ Getriebe_DQ SG_ 2463978710 UserStateServer_01_BZ 1000;
BA_REL_ "GenSigTimeoutTime" BU_SG_REL_ Getriebe_DQ SG_ 2463978710 OPS_SafeDriverPresenceStatus 1000;
BA_REL_ "GenSigTimeoutTime" BU_SG_REL_ Getriebe_DQ SG_ 2463978710 OPS_SafeDriverPresence_available 1000;
BA_REL_ "GenSigTimeoutTime" BU_SG_REL_ Motor_konv SG_ 2264486920 RHP_01_CRC 500;
BA_REL_ "GenSigTimeoutTime" BU_SG_REL_ Motor_konv SG_ 2264486920 RHP_01_BZ 500;
BA_REL_ "GenSigTimeoutTime" BU_SG_REL_ Motor_konv SG_ 2264486920 RHP_pos_Sollbeschl_Grad 500;
BA_REL_ "GenSigTimeoutTime" BU_SG_REL_ Motor_konv SG_ 2264486920 RHP_neg_Sollbeschl_Grad 500;
BA_REL_ "GenSigTimeoutTime" BU_SG_REL_ Motor_konv SG_ 2264486920 RHP_Sollbeschleunigung 500;
BA_REL_ "GenSigTimeoutTime" BU_SG_REL_ Motor_konv SG_ 2264486920 RHP_zul_Regelabw_oben 500;
BA_REL_ "GenSigTimeoutTime" BU_SG_REL_ Motor_konv SG_ 2264486920 RHP_zul_Regelabw_unten 500;
BA_REL_ "GenSigTimeoutTime" BU_SG_REL_ Motor_konv SG_ 2264486920 RHP_TSK_Status 500;
BA_REL_ "GenSigTimeoutTime" BU_SG_REL_ Motor_konv SG_ 2264486920 RHP_Minimale_Bremsung 500;
BA_REL_ "GenSigTimeoutTime" BU_SG_REL_ Motor_konv SG_ 2264486920 RHP_StartStopp_Info 500;
BA_REL_ "GenSigTimeoutTime" BU_SG_REL_ Motor_konv SG_ 2264486920 RHP_nachtr_Stopp_Anf 500;
BA_REL_ "GenSigTimeoutTime" BU_SG_REL_ Motor_konv SG_ 2264486920 RHP_Freilaufstrategie_TSK 500;
BA_REL_ "GenSigTimeoutTime" BU_SG_REL_ Motor_konv SG_ 2264486920 RHP_Status_Function 500;
BA_REL_ "GenSigTimeoutTime" BU_SG_REL_ Motor_konv SG_ 980 BH_Blinker_li 5000;
BA_REL_ "GenSigTimeoutTime" BU_SG_REL_ Motor_konv SG_ 980 BH_Blinker_re 5000;
BA_REL_ "GenSigTimeoutTime" BU_SG_REL_ Motor_konv SG_ 1313 STH_Zusatzheizung 2000;
BA_REL_ "GenSigTimeoutTime" BU_SG_REL_ Motor_konv SG_ 1313 STH_LED 2000;
BA_REL_ "GenSigTimeoutTime" BU_SG_REL_ Motor_konv SG_ 1313 STH_Pumpe_ein 2000;
BA_REL_ "GenSigTimeoutTime" BU_SG_REL_ Motor_konv SG_ 1313 STH_EKP_Anst 2000;
BA_REL_ "GenSigTimeoutTime" BU_SG_REL_ Motor_konv SG_ 1313 STH_Ventil_Status 2000;
BA_REL_ "GenSigTimeoutTime" BU_SG_REL_ Motor_konv SG_ 1313 STH_Fehler_ElWaPu 2000;
BA_REL_ "GenSigTimeoutTime" BU_SG_REL_ Motor_konv SG_ 1313 STH_Waermeeintrag 2000;
BA_REL_ "GenSigTimeoutTime" BU_SG_REL_ Motor_konv SG_ 1313 STH_Pumpen_Anf_extern 2000;
BA_REL_ "GenSigTimeoutTime" BU_SG_REL_ Motor_konv SG_ 1313 STH_Wassertemp 2000;
BA_REL_ "GenSigTimeoutTime" BU_SG_REL_ Motor_konv SG_ 1313 STH_Motorvorwaermung 2000;
BA_REL_ "GenSigTimeoutTime" BU_SG_REL_ Motor_konv SG_ 1313 STH_war_aktiv 2000;
BA_REL_ "GenSigTimeoutTime" BU_SG_REL_ Motor_konv SG_ 1413 SI_P_Mode_gueltig 5000;
BA_REL_ "GenSigTimeoutTime" BU_SG_REL_ Motor_konv SG_ 1413 SI_QRS_Mode 5000;
BA_REL_ "GenSigTimeoutTime" BU_SG_REL_ Motor_konv SG_ 1413 SI_T_Mode 5000;
BA_REL_ "GenSigTimeoutTime" BU_SG_REL_ Motor_konv SG_ 1413 SI_T_Schutz 5000;
BA_REL_ "GenSigTimeoutTime" BU_SG_REL_ Motor_konv SG_ 1413 SI_P_Mode 5000;
BA_REL_ "GenSigTimeoutTime" BU_SG_REL_ Motor_konv SG_ 1413 SI_BUS_03 5000;
BA_REL_ "GenSigTimeoutTime" BU_SG_REL_ Motor_konv SG_ 1413 SI_CAB_V14 5000;
BA_REL_ "GenSigTimeoutTime" BU_SG_REL_ Motor_konv SG_ 2589283571 TLI_LSA1_Info_Backlog 5000;
BA_REL_ "GenSigTimeoutTime" BU_SG_REL_ Motor_konv SG_ 2589283571 TLI_LSA1_GLOSA_Unit 5000;
BA_REL_ "GenSigTimeoutTime" BU_SG_REL_ Motor_konv SG_ 2589283571 TLI_LSA1_TTG 5000;
BA_REL_ "GenSigTimeoutTime" BU_SG_REL_ Motor_konv SG_ 2589283571 TLI_LSA1_GLOSA 5000;
BA_REL_ "GenSigTimeoutTime" BU_SG_REL_ Motor_konv SG_ 2589283571 TLI_LSA1_GLOSA_Display 5000;
BA_REL_ "GenSigTimeoutTime" BU_SG_REL_ Motor_konv SG_ 2589283571 TLI_LSA1_Data_Age 5000;
BA_REL_ "GenSigTimeoutTime" BU_SG_REL_ Motor_konv SG_ 2589283571 TLI_LSA1_Data_Source 5000;
BA_REL_ "GenSigTimeoutTime" BU_SG_REL_ Motor_konv SG_ 2589283571 TLI_LSA1_Distance_Backlog 5000;
BA_REL_ "GenSigTimeoutTime" BU_SG_REL_ Motor_konv SG_ 2589283571 TLI_LSA1_Distance_Stop_Line 5000;
BA_REL_ "GenSigTimeoutTime" BU_SG_REL_ Motor_konv SG_ 2589283571 TLI_LSA1_Direction_N 5000;
BA_REL_ "GenSigTimeoutTime" BU_SG_REL_ Motor_konv SG_ 2589283571 TLI_LSA1_Direction_NE 5000;
BA_REL_ "GenSigTimeoutTime" BU_SG_REL_ Motor_konv SG_ 2589283571 TLI_LSA1_Direction_E 5000;
BA_REL_ "GenSigTimeoutTime" BU_SG_REL_ Motor_konv SG_ 2589283571 TLI_LSA1_Direction_SE 5000;
BA_REL_ "GenSigTimeoutTime" BU_SG_REL_ Motor_konv SG_ 2589283571 TLI_LSA1_Direction_SW 5000;
BA_REL_ "GenSigTimeoutTime" BU_SG_REL_ Motor_konv SG_ 2589283571 TLI_LSA1_Direction_W 5000;
BA_REL_ "GenSigTimeoutTime" BU_SG_REL_ Motor_konv SG_ 2589283571 TLI_LSA1_Direction_NW 5000;
BA_REL_ "GenSigTimeoutTime" BU_SG_REL_ Motor_konv SG_ 2589283571 TLI_LSA1_Direction_U_Turn_NE 5000;
BA_REL_ "GenSigTimeoutTime" BU_SG_REL_ Motor_konv SG_ 2589283571 TLI_LSA1_Direction_U_Turn_NW 5000;
BA_REL_ "GenSigTimeoutTime" BU_SG_REL_ Motor_konv SG_ 2589283622 TLO_01_Zaehler 5000;
BA_REL_ "GenSigTimeoutTime" BU_SG_REL_ Motor_konv SG_ 2589283622 TLO_LSA1_Zeit1_CF 5000;
BA_REL_ "GenSigTimeoutTime" BU_SG_REL_ Motor_konv SG_ 2589283622 TLO_LSA1_Zeit1_Pred 5000;
BA_REL_ "GenSigTimeoutTime" BU_SG_REL_ Motor_konv SG_ 2589283622 TLO_LSA1_Zeit1_Status 5000;
BA_REL_ "GenSigTimeoutTime" BU_SG_REL_ Motor_konv SG_ 2589283622 TLO_LSA1_Zeit2_Pred 5000;
BA_REL_ "GenSigTimeoutTime" BU_SG_REL_ Motor_konv SG_ 2589283622 TLO_LSA1_Zeit2_Status 5000;
BA_REL_ "GenSigTimeoutTime" BU_SG_REL_ Motor_konv SG_ 2589283622 TLO_LSA1_Zeit2_CF 5000;
BA_REL_ "GenSigTimeoutTime" BU_SG_REL_ Motor_konv SG_ 2589283622 TLO_HMI_Status 5000;
BA_REL_ "GenSigTimeoutTime" BU_SG_REL_ Motor_konv SG_ 2589283622 TLO_LSA1_PSD_Segment_ID 5000;
BA_REL_ "GenSigTimeoutTime" BU_SG_REL_ Motor_konv SG_ 2589283622 TLO_StartStoppInfo 5000;
BA_REL_ "GenSigTimeoutTime" BU_SG_REL_ Motor_konv SG_ 2589283622 TLO_LSA1_PSD_Seg_Offset 5000;
BA_REL_ "GenSigTimeoutTime" BU_SG_REL_ Motor_konv SG_ 2589283623 TLO_02_Zaehler 5000;
BA_REL_ "GenSigTimeoutTime" BU_SG_REL_ Motor_konv SG_ 2589283623 TLO_LSA2_Zeit1_CF 5000;
BA_REL_ "GenSigTimeoutTime" BU_SG_REL_ Motor_konv SG_ 2589283623 TLO_LSA2_Zeit1_Pred 5000;
BA_REL_ "GenSigTimeoutTime" BU_SG_REL_ Motor_konv SG_ 2589283623 TLO_LSA2_Zeit1_Status 5000;
BA_REL_ "GenSigTimeoutTime" BU_SG_REL_ Motor_konv SG_ 2589283623 TLO_LSA2_Zeit2_Pred 5000;
BA_REL_ "GenSigTimeoutTime" BU_SG_REL_ Motor_konv SG_ 2589283623 TLO_LSA2_Zeit2_Status 5000;
BA_REL_ "GenSigTimeoutTime" BU_SG_REL_ Motor_konv SG_ 2589283623 TLO_LSA2_Zeit2_CF 5000;
BA_REL_ "GenSigTimeoutTime" BU_SG_REL_ Motor_konv SG_ 2589283623 TLO_LSA1_Layout 5000;
BA_REL_ "GenSigTimeoutTime" BU_SG_REL_ Motor_konv SG_ 2589283623 TLO_LSA2_PSD_Segment_ID 5000;
BA_REL_ "GenSigTimeoutTime" BU_SG_REL_ Motor_konv SG_ 2589283623 TLO_LSA2_PSD_Seg_Offset 5000;
BA_REL_ "GenSigTimeoutTime" BU_SG_REL_ Motor_konv SG_ 997 TSG_FT_02_CRC 1000;
BA_REL_ "GenSigTimeoutTime" BU_SG_REL_ Motor_konv SG_ 997 TSG_FT_02_BZ 1000;
BA_REL_ "GenSigTimeoutTime" BU_SG_REL_ Motor_konv SG_ 997 FT_Tuer_Status 1000;
BA_REL_ "GenSigTimeoutTime" BU_SG_REL_ Motor_konv SG_ 2463978710 UserStateServer_01_CRC 1000;
BA_REL_ "GenSigTimeoutTime" BU_SG_REL_ Motor_konv SG_ 2463978710 UserStateServer_01_BZ 1000;
BA_REL_ "GenSigTimeoutTime" BU_SG_REL_ Motor_konv SG_ 2463978710 OPS_SafeDriverPresenceStatus 1000;
BA_REL_ "GenSigTimeoutTime" BU_SG_REL_ Motor_konv SG_ 2463978710 OPS_SafeDriverPresence_available 1000;
BA_REL_ "GenSigTimeoutTime" BU_SG_REL_ Motor_konv SG_ 1716 VIN_01_MUX 2000;
BA_REL_ "GenSigTimeoutTime" BU_SG_REL_ Motor_konv SG_ 1716 VIN_4 2000;
BA_REL_ "GenSigTimeoutTime" BU_SG_REL_ Motor_konv SG_ 1716 VIN_11 2000;
BA_REL_ "GenSigTimeoutTime" BU_SG_REL_ Motor_konv SG_ 1716 VIN_5 2000;
BA_REL_ "GenSigTimeoutTime" BU_SG_REL_ Motor_konv SG_ 1716 VIN_12 2000;
BA_REL_ "GenSigTimeoutTime" BU_SG_REL_ Motor_konv SG_ 1716 VIN_6 2000;
BA_REL_ "GenSigTimeoutTime" BU_SG_REL_ Motor_konv SG_ 1716 VIN_13 2000;
BA_REL_ "GenSigTimeoutTime" BU_SG_REL_ Motor_konv SG_ 1716 VIN_7 2000;
BA_REL_ "GenSigTimeoutTime" BU_SG_REL_ Motor_konv SG_ 1716 VIN_14 2000;
BA_REL_ "GenSigTimeoutTime" BU_SG_REL_ Motor_konv SG_ 1716 VIN_1 2000;
BA_REL_ "GenSigTimeoutTime" BU_SG_REL_ Motor_konv SG_ 1716 VIN_8 2000;
BA_REL_ "GenSigTimeoutTime" BU_SG_REL_ Motor_konv SG_ 1716 VIN_15 2000;
BA_REL_ "GenSigTimeoutTime" BU_SG_REL_ Motor_konv SG_ 1716 VIN_2 2000;
BA_REL_ "GenSigTimeoutTime" BU_SG_REL_ Motor_konv SG_ 1716 VIN_9 2000;
BA_REL_ "GenSigTimeoutTime" BU_SG_REL_ Motor_konv SG_ 1716 VIN_16 2000;
BA_REL_ "GenSigTimeoutTime" BU_SG_REL_ Motor_konv SG_ 1716 VIN_3 2000;
BA_REL_ "GenSigTimeoutTime" BU_SG_REL_ Motor_konv SG_ 1716 VIN_10 2000;
BA_REL_ "GenSigTimeoutTime" BU_SG_REL_ Motor_konv SG_ 1716 VIN_17 2000;
VAL_ 1527 RW_Tendenz 0 "keine_Tendenz" 1 "konstant" 2 "steigend" 3 "sinkend" ;
VAL_ 1527 RW_Texte 0 "kein_Text" 1 "Text_1" 2 "Text_2" 3 "Text_3" ;
VAL_ 1527 RW_Reservewarnung_aktiv 0 "inaktiv" 1 "aktiv" ;
VAL_ 1527 RW_Reichweite_Einheit_Anzeige 0 "km" 1 "miles" ;
VAL_ 1527 RW_Gesamt_Reichweite_Anzeige 2045 "nicht_verbaut" 2046 "Init" 2047 "Fehler" ;
VAL_ 1527 RW_Primaer_Reichweite_Anzeige 2045 "nicht_verbaut" 2046 "Init" 2047 "Fehler" ;
VAL_ 1527 RW_Sekundaer_Reichweite_Anzeige 2045 "nicht_verbaut" 2046 "Init" 2047 "Fehler" ;
VAL_ 1527 RW_Sekundaer_Reichweite 2045 "nicht_verbaut" 2046 "Init" 2047 "Fehler" ;
VAL_ 1527 RW_Sek_Reichweitenv_Einheit 0 "Liter_pro_100km" 1 "kWh_pro_100km" 2 "Kg_pro_100km" 3 "nicht_verbaut" ;
VAL_ 1527 RW_Sek_Reichweitenverbrauch 2047 "Init" ;
VAL_ 2264486920 RHP_QFK_AnfStat 1 "Init" 2 "Bereit" 4 "Eingriff" 13 "Eingriff_HandsOff" ;
VAL_ 2264486920 RHP_TV_Trigger 0 "No_Request" 1 "Request" ;
VAL_ 2264486920 RHP_QFK_KruemmSoll_VZ 0 "positiv" 1 "negativ" ;
VAL_ 2264486920 RHP_Status_Long 0 "off" 1 "standby" 2 "active" 3 "reserve" 4 "driver_override" 5 "reserve" 6 "reserve" 7 "failure" ;
VAL_ 2264486920 RHP_Ruckfreigabe 0 "keine_Freigabe" 1 "Freigabe" ;
VAL_ 2264486920 RHP_Warnruckeln_Anf 0 "keine_Anforderung" 1 "schwaches_Warnruckeln" 2 "mittleres_Warnruckeln" 3 "starkes_Warnruckeln" ;
VAL_ 2264486920 RHP_Anf_ASIL 0 "QM" 1 "A" 2 "B" 3 "C" ;
VAL_ 2264486920 RHP_Anforderung_HMS 0 "keine_Anforderung" 1 "halten" 2 "parken" 3 "halten_Standby" 4 "anfahren" 5 "loesen_ueber_Rampe" 7 "HMS_uebernehmen" ;
VAL_ 2264486920 RHP_Sollbeschleunigung 2046 "Neutralwert" 2047 "Fehler" ;
VAL_ 2264486920 RHP_TSK_Status 0 "off" 1 "init" 2 "standby" 3 "active" 4 "driver_override" 5 "shutdown" 6 "reversible_failure" 7 "irreversible_failure" ;
VAL_ 2264486920 RHP_Minimale_Bremsung 0 "Anf_Min_Bremsung_nicht_aktiv" 1 "Anf_Min_Bremsung_aktiv" ;
VAL_ 2264486920 RHP_Uss_Anforderung 0 "UltraschallsensorenAus" 1 "UltraschallsensorenAn" ;
VAL_ 2264486920 RHP_Verz_Anf 1023 "keine_Anforderung" ;
VAL_ 2264486920 RHP_Verz_Freigabe 0 "Verzoegerung_nicht_freigeben" 1 "Verzoegerung_freigeben" ;
VAL_ 2264486920 RHP_Status_Lat 0 "off" 1 "standby" 2 "active" 3 "reserve" 4 "driver_oversteer" 5 "reserve" 6 "reserve" 7 "failure" ;
VAL_ 2264486920 RHP_StartStopp_Info 0 "Motorlauf_langfristig_nicht_notwendig_Stoppfreigabe" 1 "Motoranlauf_nicht_zwingend_notwendig_Stoppverbot_keine_Startanforderung" 2 "Motoranlauf_zwingend_notwendig_Startanforderung" 3 "Systemfehler" ;
VAL_ 2264486920 RHP_nachtr_Stopp_Anf 0 "nicht_angefordert" 1 "angefordert" ;
VAL_ 2264486920 RHP_Freilaufstrategie_TSK 0 "Freilaufstr_nicht_angefordert" 1 "Freilaufstr_angefordert" ;
VAL_ 2264486920 RHP_SCAM_HeatingRequest 0 "init" 1 "not_ready" 2 "no_heating_request" 3 "heating_request" ;
VAL_ 2264486920 RHP_Fahrzeughupe_Anf 0 "Keine_Anforderung" 1 "Anforderung_Fahrzeughupe" ;
VAL_ 2264486920 RHP_HOS 0 "not_active" 1 "hands_on" 2 "hands_off" 3 "hands_on_request" ;
VAL_ 2264486920 RHP_Status_Function 0 "off" 1 "standby" 2 "ready" 3 "active" 4 "reserve" 5 "reserve" 6 "reserve" 7 "failure" ;
VAL_ 2264486920 RHP_EA_AnfStat 0 "init" 1 "ready" 2 "interference_PHASE3" ;
VAL_ 2264486920 RHP_QFK_KrSoll_VZ 0 "positiv" 1 "negativ" ;
VAL_ 2264486920 RHP_Warnblinken 0 "kein_Blinken" 1 "Warnblinken_Taster" ;
VAL_ 2264486920 RHP_Innenraumlicht_Anf 0 "Innenraumbeleuchtung_ausschalten" 1 "Innenraumbeleuchtung_einschalten" ;
VAL_ 2264486920 RHP_Spurwechsel_Ready 0 "nicht_moeglich" 1 "links_moeglich" 2 "rechts_moeglich" 3 "links_rechts_moeglich" 4 "links_blinken" 5 "rechts_blinken" ;
VAL_ 2264486920 RHP_RBF_Available 0 "Init" 1 "Available" 2 "NotAvailable" 3 "Reserved" ;
VAL_ 2264486920 RHP_PreCrash_Anf 0 "keine_Anforderung" 1 "Aktionsgenerierte_Warnung_1" 2 "Aktionsgenerierte_Warnung_2" 3 "Aktionsgenerierte_Warnung_3" 4 "Aktionsgenerierte_Warnung_4" 5 "Aktionsgenerierte_Warnung_5" 6 "Aktionsgenerierte_Warnung_6" 7 "Aktionsgenerierte_Warnung_7" ;
VAL_ 2264486920 RHP_EA_PreCrash 0 "Keine_Anforderung" 1 "Aktionsgenerierte_Warnung_1" 2 "Aktionsgenerierte_Warnung_2" 3 "Aktionsgenerierte_Warnung_3" 4 "Aktionsgenerierte_Warnung_4" 5 "Aktionsgenerierte_Warnung_5" 6 "Aktionsgenerierte_Warnung_6" 7 "Aktionsgenerierte_Warnung_7" ;
VAL_ 2264486920 RHP_Parking_St 0 "None" 1 "Slot_detect" 2 "Guidance" 3 "Abort" ;
VAL_ 2264486920 RHP_EA_Innenraumlicht 0 "Innenraumbeleuchtun_ausschalten" 1 "Innenraumbeleuchtung_einschalten" ;
VAL_ 2264486920 RHP_EA_eCall 0 "Keine_Anforderung" 1 "Ausloesen_eCall" ;
VAL_ 2264486920 RHP_OPSEnable 0 "Initial" 1 "Not_enable" 2 "Enable" ;
VAL_ 2264486920 RHP_eCall_Anf 0 "Keine_Anforderung" 1 "Ausloesen_eCall" ;
VAL_ 2264486920 RHP_EA_Tueren 0 "Keine_Anforderung" 1 "Tueren_entriegeln" ;
VAL_ 2463978815 SBM_Veto_Fahrstufe_extern 0 "kein_Veto" 1 "Randbedingungen_nicht_erfuellt" 2 "reserviert" 3 "Fehler" ;
VAL_ 2463978815 SBM_FahrerAkt_Schaltbetaetigung 0 "nicht_betaetigt" 1 "Schaltbetaetigung_betaetigt" ;
VAL_ 2463978815 SBM_FahrerAkt_P_Taste 0 "nicht_betaetigt" 1 "P_Taste_betaetigt" ;
VAL_ 2463978815 SBM_FahrerAkt_Lenkradpaddle 0 "nicht_betaetigt" 1 "Lenkradpaddle_betaetigt" ;
VAL_ 980 BH_Blinker_li 0 "nicht_betaetigt" 1 "Blinkerhebel_Pos_li_betaetigt" ;
VAL_ 980 BH_Blinker_re 0 "nicht_betaetigt" 1 "Blinkerhebel_Pos_re_betaetigt" ;
VAL_ 980 BH_Lichthupe 0 "nicht_betaetigt" 1 "Blinkerhebel in Richtung Lichthupe betaetigt" ;
VAL_ 980 BH_Fernlicht 0 "nicht_betaetigt" 1 "Blinkerhebel_in_Richtung_Fernlicht_betaetigt" ;
VAL_ 980 WH_Tipwischen 0 "nicht_betaetigt" 1 "betaetigt" ;
VAL_ 980 WH_Intervall 0 "aus" 1 "Wischerhebel in Stellung Intervall" ;
VAL_ 980 WH_WischerStufe1 0 "aus" 1 "Wischerhebel in Stufe Wischen 1" ;
VAL_ 980 WH_WischerStufe2 0 "aus" 1 "Wischerhebel in Stufe Wischen 2" ;
VAL_ 980 WH_Frontwaschen 0 "aus" 1 "Wischerhebel in Stellung Wisch Wasch vorne" ;
VAL_ 980 WH_Heckintervall 0 "nicht_betaetigt" 1 "Wischerhebel in Stellung Heckintervall" ;
VAL_ 980 WH_Heckwaschen 0 "nicht_betaetigt" 1 "Wischerhebel in Stellung Wisch Wasch hinten" ;
VAL_ 980 WH_Intervallstufen 0 "Init / Default" 1 "Intervallstufe 1" 5 "Intervallstufe 2" 9 "Intervallstufe 3" 13 "Intervallstufe 4" 15 "Fehler" ;
VAL_ 980 FAS_Taster 0 "nicht_betaetigt" 1 "betaetigt" ;
VAL_ 980 FAS_Taster_Fehler 0 "kein_Fehler" 1 "Fehler" ;
VAL_ 980 SMLS_Hupe 0 "nicht_betaetigt" 1 "Hupe_gedrueckt" ;
VAL_ 980 LRH_On_Off 0 "LRH_aus__keine Anzeige" 1 "LRH_aus" 2 "LRH_ein" 3 "Fehler" ;
VAL_ 980 LSS_Tastencode 0 "Key_Released__No_Key" 4 "Up" 5 "Down" 7 "OK__ThumbWheel_Button" ;
VAL_ 980 LRH_aktiv 0 "inaktiv" 1 "aktiv" ;
VAL_ 980 SMLS_P_verriegelt 0 "Init" 1 "nicht_verriegelt" 2 "verriegelt" 3 "Fehler" ;
VAL_ 980 SMLS_P_verriegelt_plausibel 0 "unplausibel" 1 "plausibel" ;
VAL_ 980 WH_SRA 0 "SRA_Aus" 1 "SRA_Ein" ;
VAL_ 980 WH_Wischer_Fehler 0 "kein_Fehler" 1 "Fehler" ;
VAL_ 980 BH_Blinker_Fehler 0 "kein_Fehler" 1 "Fehler" ;
VAL_ 980 SMLS_PTT 0 "nicht_betaetigt" 1 "PTT_gedrueckt" ;
VAL_ 980 WH_Tipwischen_lang 0 "nicht_betaetigt" 1 "betaetigt" ;
VAL_ 2589283756 SOK_ungeschuetzte_Zeit 0 "Init" ;
VAL_ 1313 STH_Funk_ein 0 "kein Funkbefehl zum Einschalten" 1 "Funkbefehl zum Einschalten erhalten" ;
VAL_ 1313 STH_Funk_aus 0 "kein Funkbefehl" 1 "Funkbefehl zum Ausschalten erhalten" ;
VAL_ 1313 STH_Zusatzheizung 0 "Zuheizer aus" 1 "Zuheizer ein" ;
VAL_ 1313 STH_LED 0 "keine Rückmeldung" 1 "Rueckmeldung Standheizung in Betrieb" ;
VAL_ 1313 STH_Geblaese 0 "kein Einschaltbefehl an die Klimaanlage, Gebläse" 1 "Einschaltbefehl an die Klimaanlage, Gebläse" ;
VAL_ 1313 STH_EKP_Anst 0 "EKP nicht ansteuern" 1 "EKP ansteuern" ;
VAL_ 1313 STH_Start_folgt 0 "kein_Start_folgt" 1 "Start_folgt" ;
VAL_ 1313 STH_Ventil_Status 0 "Ventil_offen__grosser_Kreislauf" 1 "Ventil_geschlossen__kleiner_Kreislauf" ;
VAL_ 1313 STH_Fehler_ElWaPu 0 "kein_Fehler" 1 "Fehler" ;
VAL_ 1313 STH_Pumpen_Anf_extern 0 "nicht_angefordert" 1 "angefordert" ;
VAL_ 1313 STH_KL_HUP 0 "Aus" 1 "Ein" ;
VAL_ 1313 STH_Fehlerstatus 0 "kein_Fehler" 1 "Unterspannung" 2 "Tankfuellstand_zu_gering" 3 "Fehler_Betrieb_verhindert" 4 "Heizgeraet_verriegelt" 5 "Fehler_Betrieb_nicht_verhindert" 6 "Emissionsüberschreitung" ;
VAL_ 1313 STH_Wassertemp 254 "Init" 255 "Fehler" ;
VAL_ 1313 STH_Texte 0 "keine_Anzeige" 1 "Batteriemanagementeinschraenkung" 2 "Kraftstoffmangel" 3 "interner_Systemfehler" 4 "Heizzeitueberschreitung" ;
VAL_ 1313 STH_Motorvorwaermung 0 "keine Motorvorwärmung erfolgt" 1 "Aufheizung mit Motorvorwärmung erfolgt" ;
VAL_ 1313 STH_Servicemode 0 "Servicemode nicht aktiv" 1 "Servicemode aktiv" ;
VAL_ 1313 STH_war_aktiv 0 "war inaktiv" 1 "Standheizung war letzte halbe Stunde aktiv" ;
VAL_ 1313 STH_KVS_Ueberlauf 0 "kein Überlauf" 1 "Kraftstoffverbrauchssignal, mindestens ein Überlauf hat stattgefunden" ;
VAL_ 1313 STH_SH_ZH 0 "Heizgeraet_WZH" 1 "Heizgeraet_ZH" ;
VAL_ 1413 SI_Sammel_SG_Fehler 61 "Reserviert" 62 "Overflow" 63 "ungueltig" ;
VAL_ 1413 SI_P_Mode_gueltig 0 "dezentraler_Produktionsmode" 1 "zentraler_Produktionsmode" ;
VAL_ 1413 SI_Diagnose_Aktiv 0 "inaktiv" 1 "aktiv" ;
VAL_ 1413 SI_QRS_Mode 0 "QRS_Messmodus_nicht_aktiv" 1 "QRS_Messmodus_aktiv" ;
VAL_ 1413 SI_T_Mode 0 "Transportmodus_nicht_aktiv" 1 "Transportmodus_aktiv" ;
VAL_ 1413 SI_NWDF 0 "Ueberwachung_nicht_freigegeben" 1 "Ueberwachung_freigegeben" ;
VAL_ 1413 SI_NWDF_gueltig 0 "NWDF_wird_nicht_unterstuetzt" 1 "NWDF_wird_unterstuetzt" ;
VAL_ 1413 SI_Sammelfehler 0 "kein_Sammelfehler" 1 "Sammelfehler" ;
VAL_ 1413 GW_KD_Fehler 0 "kein_KD_Fehler" 1 "KD_Fehler" ;
VAL_ 1413 SI_T_Schutz 0 "Transportschutz_nicht_aktiv" 1 "Transportschutz_aktiv" ;
VAL_ 1413 SI_P_Mode 0 "inaktiv" 1 "aktiv" ;
VAL_ 1413 SI_BUS_01 0 "keine_Busruhe" 1 "Busruhe" ;
VAL_ 1413 SI_BUS_02 0 "keine_Busruhe" 1 "Busruhe" ;
VAL_ 1413 SI_BUS_03 0 "keine_Busruhe" 1 "Busruhe" ;
VAL_ 1413 SI_BUS_04 0 "keine_Busruhe" 1 "Busruhe" ;
VAL_ 1413 SI_BUS_05 0 "keine_Busruhe" 1 "Busruhe" ;
VAL_ 1413 SI_BUS_06 0 "keine_Busruhe" 1 "Busruhe" ;
VAL_ 1413 SI_BUS_07 0 "keine_Busruhe" 1 "Busruhe" ;
VAL_ 1413 SI_BUS_08 0 "keine_Busruhe" 1 "Busruhe" ;
VAL_ 1413 SI_BUS_09 0 "keine_Busruhe" 1 "Busruhe" ;
VAL_ 1413 SI_BUS_10 0 "keine_Busruhe" 1 "Busruhe" ;
VAL_ 1413 SI_BUS_11 0 "keine_Busruhe" 1 "Busruhe" ;
VAL_ 1413 SI_BUS_12 0 "keine_Busruhe" 1 "Busruhe" ;
VAL_ 1413 SI_BUS_13 0 "keine_Busruhe" 1 "Busruhe" ;
VAL_ 1413 SI_BUS_14 0 "keine_Busruhe" 1 "Busruhe" ;
VAL_ 1413 SI_BUS_15 0 "keine_Busruhe" 1 "Busruhe" ;
VAL_ 1413 SI_NWDF_30 0 "Ueberwachung_nicht_freigegeben" 1 "Ueberwachung_freigegeben" ;
VAL_ 1413 SI_Bus_Identifikation 16 "CAN_Diagnose" 17 "CAN_Antrieb" 18 "CAN_Komfort" 19 "CAN_Infotainment" 20 "CAN_Fahrwerk" 21 "CAN_Extended" 22 "CAN_Hybrid" 23 "CAN_Lade" 24 "CAN_Kombi" 25 "CAN_Komfort_2" 26 "CAN_AFS" 27 "CAN_MIB" 28 "CAN_Batterie_BMC" 29 "CAN_Motor" 31 "CAN_Airbag_Sicherheitssysteme" 33 "CAN_FahrerAssistenzSysteme" 34 "CAN_Migration" 35 "CAN_Connect" 36 "CAN_AnzeigeBedienung" 37 "CAN_ElectricalVehicle" 40 "CAN_Telematik" 41 "CAN_MFL" 42 "CAN_FahrerAssistenzSysteme_2" 43 "CAN_FahrerAssistenzSysteme_3" 47 "CAN_Komfort_3" 48 "FlexRay_A" 49 "FlexRay_B" 97 "VLAN_FAS" 98 "VLAN_Infotainment" 99 "VLAN_Connect" 100 "VLAN_Komfort" 101 "VLAN_Antrieb" 102 "VLAN_Diagnose" 103 "VLAN_Internet" 104 "VLAN_Gateway" 105 "VLAN_Remote_FC" 106 "VLAN_Connect_2" 107 "VLAN_Licht" 108 "VLAN_Charge" 109 "VLAN_Cockpit" 110 "VLAN_Connect_3" 111 "VLAN_IoT" 112 "VLAN_CarPerformance" 113 "VLAN_ConMod" 114 "VLAN_FAS2" 176 "HCP1_CANFD01" 177 "HCP1_CANFD02" 178 "HCP1_CANFD03" 179 "HCP1_CANFD04" 180 "HCP1_CANFD05" 181 "HCP1_CANFD06" 182 "HCP1_CANFD07" 183 "HCP1_CANFD08" 186 "HCP4_CANFD03" 187 "HCP4_CANFD04" 188 "HCP1_CANFD09" 189 "HCP4_CANFD06" 190 "HCP4_CANFD07" 191 "HCP4_CANFD08" 192 "HCP4_CANFD09" 193 "HCP4_CANFD10" 194 "HCP1_CANFD10" 195 "ICAS1_CANFD2_HCP5_CANFD02" 196 "HCP1_CANFD11" 197 "WU_HCP1_CANFD" 199 "WU_HCP2_CANFD" 200 "WU_HCP3_CANFD" 201 "WU_HCP4_CANFD" 202 "HCP3_CANFD02" 204 "ESC_CANFD" 205 "HCP4_CANFD11" 206 "HCP4_CANFD12" 207 "CAN_Innenraumsensorik" 212 "WU_ConMod_CANFD" 213 "WU_PASD_CANFD" 215 "CAN_MobileDeviceKey" 217 "CAN_Tuerantrieb_VL" 218 "CAN_Tuerantrieb_VR" 219 "CAN_Tuerantrieb_HL" 220 "CAN_Tuerantrieb_HR" ;
VAL_ 1413 SI_CAB_V14 0 "Init" 1 "CAB_01_Antrieb" 2 "CAB_02_Hybrid_Laden" 4 "CAB_03_Fahrwerk" 8 "CAB_04_Fahrerassistenz" 16 "CAB_05_Komfort" 32 "CAB_06_Anzeige" 64 "CAB_07_Connect" 128 "CAB_08_MIB" 256 "CAB_09_Standheizung" 1024 "CAB_11_VLAN_Fahrerassistenz" 2048 "CAB_12_VLAN_Komfort" 4096 "CAB_13_VLAN_Connect" 8192 "CAB_14_VLAN_Infotainment" 16384 "CAB_15_Laden" 32768 "CAB_16_Licht" ;
VAL_ 2589283571 TLI_LSA1_Info_Backlog 0 "keine_Information" 1 "Rueckstau_vorhanden" 2 "Init" 3 "Fehler" ;
VAL_ 2589283571 TLI_LSA1_GLOSA_Unit 0 "kmh" 1 "mph" 2 "Init" 3 "Fehler" ;
VAL_ 2589283571 TLI_LSA1_TTG 252 "groesser_4min" 253 "groesser_5min" 254 "Init" 255 "Fehler" ;
VAL_ 2589283571 TLI_LSA1_GLOSA 253 "groesser_200" 254 "Init" 255 "Fehler" ;
VAL_ 2589283571 TLI_LSA1_GLOSA_Display 253 "groesser_200" 254 "Init" 255 "Fehler" ;
VAL_ 2589283571 TLI_LSA1_Data_Age 4093 "groesser_400s" 4094 "Init" 4095 "Fehler" ;
VAL_ 2589283571 TLI_LSA1_Data_Source 0 "Car2X" 1 "Backend" 2 "Hybrid" 3 "Init" 4 "Fehler" ;
VAL_ 2589283571 TLI_LSA1_Distance_Backlog 509 "Wert_nicht_bekannt" 510 "Init" 511 "Fehler" ;
VAL_ 2589283571 TLI_LSA1_Distance_Stop_Line 8189 "Wert_nicht_bekannt" 8190 "Init" 8191 "Fehler" ;
VAL_ 2589283571 TLI_LSA1_Direction_N 0 "allowed" 1 "not_allowed" 2 "Init" 3 "Fehler" ;
VAL_ 2589283571 TLI_LSA1_Direction_NE 0 "allowed" 1 "not_allowed" 2 "Init" 3 "Fehler" ;
VAL_ 2589283571 TLI_LSA1_Direction_E 0 "allowed" 1 "not_allowed" 2 "Init" 3 "Fehler" ;
VAL_ 2589283571 TLI_LSA1_Direction_SE 0 "allowed" 1 "not_allowed" 2 "Init" 3 "Fehler" ;
VAL_ 2589283571 TLI_LSA1_Direction_SW 0 "allowed" 1 "not_allowed" 2 "Init" 3 "Fehler" ;
VAL_ 2589283571 TLI_LSA1_Direction_W 0 "allowed" 1 "not_allowed" 2 "Init" 3 "Fehler" ;
VAL_ 2589283571 TLI_LSA1_Direction_NW 0 "allowed" 1 "not_allowed" 2 "Init" 3 "Fehler" ;
VAL_ 2589283571 TLI_LSA1_Direction_U_Turn_NE 0 "allowed" 1 "not_allowed" 2 "Init" 3 "Fehler" ;
VAL_ 2589283571 TLI_LSA1_Direction_U_Turn_NW 0 "allowed" 1 "not_allowed" 2 "Init" 3 "Fehler" ;
VAL_ 2589283622 TLO_LSA1_Zeit1_Pred 0 "Init" ;
VAL_ 2589283622 TLO_LSA1_Zeit1_Status 0 "UNAVAILABLE" 1 "STOP_THEN_PROCEED" 2 "STOP_AND_REMAIN" 3 "PRE_MOVEMENT" 4 "PERMISSIVE_MOVEMENT_ALLOWED" 5 "PROTECTED_MOVEMENT_ALLOWED" 6 "PERMISSIVE_CLEARANCE" 7 "PROTECTED_CLEARANCE" 8 "CAUTION_CONFLICTING_TRAFFIC" ;
VAL_ 2589283622 TLO_LSA1_Zeit2_Pred 0 "Init" ;
VAL_ 2589283622 TLO_LSA1_Zeit2_Status 0 "UNAVAILABLE" 1 "STOP_THEN_PROCEED" 2 "STOP_AND_REMAIN" 3 "PRE_MOVEMENT" 4 "PERMISSIVE_MOVEMENT_ALLOWED" 5 "PROTECTED_MOVEMENT_ALLOWED" 6 "PERMISSIVE_CLEARANCE" 7 "PROTECTED_CLEARANCE" 8 "CAUTION_CONFLICTING_TRAFFIC" ;
VAL_ 2589283622 TLO_HMI_Status 0 "Init" 1 "Active__Funktion_Verbindung_iO" 2 "Standby_Normal_Mode__Warten_auf_neue_Daten" 3 "SwitchedOff__Durch_Fahrer_deaktiviert" 4 "FilteredOut__Nicht_angezeigter_Hinweis" 5 "ActiveFunktionVerbindung_iO_A_Gl" 6 "ActiveFunktionVerbindung_iO_A_Tg" ;
VAL_ 2589283622 TLO_LSA1_PSD_Segment_ID 0 "Init" ;
VAL_ 2589283622 TLO_StartStoppInfo 0 "Motorlauf_nicht_notwendig_(Stoppfreigabe)" 1 "Motoranlauf_nicht_zwingend_notwendig_(Stoppverbot,keine_Startanforderung)" 2 "Motoranlauf_zwingend_notwendig_(Startanforderung)" 3 "Systemfehler" ;
VAL_ 2589283622 TLO_LSA1_PSD_Seg_Offset 255 "Init" ;
VAL_ 2589283623 TLO_LSA2_Zeit1_Pred 0 "Init" ;
VAL_ 2589283623 TLO_LSA2_Zeit1_Status 0 "UNAVAILABLE" 1 "STOP_THEN_PROCEED" 2 "STOP_AND_REMAIN" 3 "PRE_MOVEMENT" 4 "PERMISSIVE_MOVEMENT_ALLOWED" 5 "PROTECTED_MOVEMENT_ALLOWED" 6 "PERMISSIVE_CLEARANCE" 7 "PROTECTED_CLEARANCE" 8 "CAUTION_CONFLICTING_TRAFFIC" ;
VAL_ 2589283623 TLO_LSA2_Zeit2_Pred 0 "Init" ;
VAL_ 2589283623 TLO_LSA2_Zeit2_Status 0 "UNAVAILABLE" 1 "STOP_THEN_PROCEED" 2 "STOP_AND_REMAIN" 3 "PRE_MOVEMENT" 4 "PERMISSIVE_MOVEMENT_ALLOWED" 5 "PROTECTED_MOVEMENT_ALLOWED" 6 "PERMISSIVE_CLEARANCE" 7 "PROTECTED_CLEARANCE" 8 "CAUTION_CONFLICTING_TRAFFIC" ;
VAL_ 2589283623 TLO_LSA1_Layout 0 "vertical_layout_red_top" 1 "horizontal_layout_red_left" 2 "horizontal_layout_red_right" 3 "reserved" ;
VAL_ 2589283623 TLO_LSA2_PSD_Segment_ID 0 "Init" ;
VAL_ 2589283623 TLO_LSA2_PSD_Seg_Offset 255 "Init" ;
VAL_ 1447 ORU_KombiTimer 0 "ORU_Inaktiv" 1 "ORU_Start" ;
VAL_ 1447 MOD_Energie_Anf 0 "Keine_Anforderung" 1 "Anforderung_NV" 2 "Anforderung_HV_Nutzung_Erlaubt" 3 "Fehler" ;
VAL_ 1447 FaceRec_Enroll_Challenge_Request 0 "SEND_NOTHING" 1 "SEND_CHALLENGE" ;
VAL_ 1447 eCall_Mute_Anf 0 "kein_mute" 1 "mute" ;
VAL_ 1447 FoD_Anz_Funktionsabschaltung 0 "Init" 1 "Popup_aufschalten" ;
VAL_ 1447 iCall_active 0 "inaktiv" 1 "aktiv" ;
VAL_ 1447 bCall_active 0 "bcall_inactive" 1 "bcall_active" ;
VAL_ 1447 MOD_Request_ServiceKey 0 "Init" 1 "Aktuallisierungsanfrage" ;
VAL_ 1447 eCall_Funktionsstatus_02 0 "kein_Fehler" 1 "Manueller_Notruf_aktiv" 2 "Automatischer_Notruf_aktiv" 7 "Init" ;
VAL_ 1447 eCall_Funktionsstatus 0 "kein_Fehler" 1 "Fkt_eingeschraenkt" 2 "Fkt_eingeschraenkt_service" 3 "Fkt_nicht_verfuegbar" 4 "Fkt_Service" 5 "Fkt_deaktiviert" 6 "Fkt_aktiviert" 7 "init" ;
VAL_ 1447 TM_Spiegel_Anklappen 0 "Init" 1 "Spiegel_anklappen" ;
VAL_ 1447 TM_Nur_Hupen 0 "inaktiv" 1 "aktiv" ;
VAL_ 1447 TM_Door_Lock 0 "Init" 1 "door_lock" ;
VAL_ 1447 TM_Door_Unlock 0 "Init" 1 "door_unlock" ;
VAL_ 1447 TM_Warnblinken 0 "Init" 1 "Warnblinken_on" ;
VAL_ 1447 TM_Panik_Alarm 0 "Init" 1 "panik_alarm_on" ;
VAL_ 1447 TM_ZV_Signatur 0 "Init" ;
VAL_ 976 FT_Tuer_geoeffnet 0 "geschlossen" 1 "Tuer_offen" ;
VAL_ 976 FT_verriegelt 0 "Init" 1 "verriegelt" ;
VAL_ 976 FT_gesafet 0 "Init" 1 "gesafet" ;
VAL_ 976 FT_Schluesselschalter_auf 0 "Init" 1 "Schluesselschalter_auf_betaetigt" ;
VAL_ 976 FT_Schluesselschalter_zu 1 "Schluesselschalter zu betaetigt" ;
VAL_ 976 FT_Unlock_Taster 0 "Init" 1 "Unlock_Taster_betaetigt" ;
VAL_ 976 FT_Lock_Taster 0 "Init" 1 "Lock_Taster_betaetigt" ;
VAL_ 976 FT_Sperrklinke 0 "Schloss_in_Vorraste_und_Hauptraste" 1 "Tuer_auf_oder_Tuer_Position_zwischen_Vor_und_Hauptraste" ;
VAL_ 976 FT_TAG_betaetigt 0 "nicht_betaetigt" 1 "betaetigt" ;
VAL_ 976 FT_TIG_betaetigt 0 "nicht_betaetigt" 1 "betaetigt" ;
VAL_ 976 FT_IRUE_Taste 0 "Init" 1 "IRUE_Taste_betaetigt" ;
VAL_ 976 FT_HD_Taste 0 "nicht_betaetigt" 1 "Heckdeckeltaste_betaetigt" ;
VAL_ 976 FT_TD_Taste_Fehler 0 "iO" 1 "defekt" ;
VAL_ 976 FT_TD_Taste 0 "Init" 1 "Tankdeckel_Taster_betaetigt" ;
VAL_ 976 SSR_Temp_Freigabe 0 "SSR_Deaktiviert" 1 "SSR_Freigegeben" ;
VAL_ 976 FT_HD_Taste_2 0 "Taste_nicht_gedrueckt" 1 "Taste_gedrueckt" ;
VAL_ 976 FT_Lock_Unlock_Taster 0 "nicht_betaetigt" 1 "betaetigt" ;
VAL_ 976 FT_TSG_hinten_verbaut 0 "nicht verbaut" 1 "verbaut" ;
VAL_ 976 FT_Sp_Blk_def 0 "iO" 1 "defekt" ;
VAL_ 976 FT_FH_S_ManHoch 0 "Init" 1 "FH_Schalter_man_hoch_betaetigt" ;
VAL_ 976 FT_FH_S_AutoHoch 0 "Init" 1 "FH_Schalter_auto_hoch_betaetigt" ;
VAL_ 976 FT_FH_S_ManTief 0 "Init" 1 "FH_Schalter_man_tief_betaetigt" ;
VAL_ 976 FT_FH_S_AutoTief 0 "Init" 1 "FH_Schalter_auto_tief_betaetigt" ;
VAL_ 976 FT_FH_Bew_hoch 0 "Init" 1 "FH_in_Bewegung_hoch" ;
VAL_ 976 FT_FH_Bew_tief 0 "Init" 1 "FH_in_Bewegung_tief" ;
VAL_ 976 FT_FH_Fang 0 "ausserhalb_Fangbereich" 1 "innerhalb_Fangbereich" ;
VAL_ 976 FT_FH_Block 0 "Init" 1 "Fenster_Block" ;
VAL_ 976 FT_FH_Thermo 0 "Init" 1 "Thermoschutz_aktiv" ;
VAL_ 976 FT_UEKB_aktiviert 0 "Init" 1 "UEKB_aktiv" ;
VAL_ 976 ASW_HMI_defekt 0 "iO" 1 "defekt" ;
VAL_ 976 FT_FH_normiert 0 "Init" 1 "Fenster_normiert" ;
VAL_ 976 FT_Schliesstaster 1 "Schliesstaster_betaetigt" ;
VAL_ 976 FT_Zuziehhilfe_aktiv 0 "Init" 1 "Zuziehilfe_aktiv" ;
VAL_ 976 FT_SP_ausgerastet 0 "Init" 1 "Spiegel_ausgerastet" ;
VAL_ 976 FT_SP_lr_aktiv 0 "Init" 1 "Spiegel_xAchse_aktiv" ;
VAL_ 976 FT_SP_ht_aktiv 0 "Init" 1 "Spiegel_yAchse_aktiv" ;
VAL_ 976 ASW_wakeup 0 "Sleep" 1 "Wakeup" ;
VAL_ 976 FT_Oben_Block_erw 0 "Fensterheber_nicht_in_Blockerwar" 1 "Fensterheber_in_Blockerwartung_o" ;
VAL_ 976 FT_Unten_Block_erw 0 "Fensterheber_nicht_in_Blockerwar" 1 "Fensterheber_in_Blockerwartung_u" ;
VAL_ 976 FT_Kisi_li_aktiv 0 "inaktiv" 1 "aktiv" ;
VAL_ 976 FT_Kisi_re_aktiv 0 "inaktiv" 1 "aktiv" ;
VAL_ 976 FT_Kisi_Taster_li 0 "nicht_betaetigt" 1 "betaetigt" ;
VAL_ 976 FT_Kisi_Taster_re 0 "nicht_betaetigt" 1 "betaetigt" ;
VAL_ 976 FT_BFS_Fond_Freigabe 0 "Init" 1 "Freigabe_fuer_Fondbedienung_BFS" ;
VAL_ 976 FT_Kisi_Fehler 0 "kein_Fehler" 1 "Fehler" ;
VAL_ 976 FT_Daemmglas 0 "Normalglas_verbaut" 1 "Daemmglas_verbaut" ;
VAL_ 976 FT_SP_Heizung_Status 0 "Init" 1 "Status_Spiegelheizung_ein" ;
VAL_ 976 ASW_Warnung_aktiv_FS 0 "nicht_angefordert" 1 "angefordert" ;
VAL_ 976 FT_FH_Pos_oben 1 "Scheibe oben (nach Absenken auf Position) " ;
VAL_ 976 FT_Tuerschloss_defekt 0 "Tuerschloss_funktionsfaehig" 1 "Tuerschloss_defekt" ;
VAL_ 976 FT_SWA_Taster 0 "Taster_nicht_betaetigt" 1 "Taster_betaetigt" ;
VAL_ 976 SWA_HMI_Diagnose 0 "kein_Fehler_erkannt" 1 "Fehler_Taster_erkannt" 2 "Fehler_LED_erkannt" 3 "Fehler_LED_und_Taster_erkannt" ;
VAL_ 976 FS_Status_eTAG 0 "Init" 1 "Griff_ausgefahren" 2 "Griff_eingefahren" 3 "Fehler" ;
VAL_ 997 FT_Tuer_Status 0 "Init" 1 "Tuer_geschlossen" 2 "Tuer_offen" 3 "Fehler" ;
VAL_ 997 FT_Tuer_Status_QBit 0 "Status_Tuerkontakt_sicher" 1 "Status_Tuerkontakt_unsicher" ;
VAL_ 997 FT_Lock_Taster_02 0 "nicht_betaetigt" 1 "betaetigt" ;
VAL_ 997 FT_Schluesselschalter_zu_02 0 "nicht_betaetigt" 1 "betaetigt" ;
VAL_ 997 FT_BFS_Tuer_Status 0 "Init" 1 "Tuer_geschlossen" 2 "Tuer_offen" 3 "Fehler" ;
VAL_ 997 FT_HBFS_Tuer_Status 0 "Init" 1 "Tuer_geschlossen" 2 "Tuer_offen" 3 "Fehler" ;
VAL_ 997 FT_HFS_Tuer_Status 0 "Init" 1 "Tuer_geschlossen" 2 "Tuer_offen" 3 "Fehler" ;
VAL_ 997 FT_Tueroeffnen_Warnung 0 "Tuerwarnung_nicht_aktiv" 1 "Tuerwarnung_aktiv" ;
VAL_ 997 FT_SP_Heizung_ein 0 "Aus" 1 "Ein" ;
VAL_ 997 FT_Kisi_Taster_li_02 0 "nicht_betaetigt" 1 "betaetigt" ;
VAL_ 997 FT_Kisi_Taster_re_02 0 "nicht_betaetigt" 1 "betaetigt" ;
VAL_ 997 FT_TD_Taste_Status 0 "kein_Fehler" 1 "Kurzschluss_nach_Minus" 2 "Kurzschluss_nach_Plus" 3 "Leitungsunterbrechung" ;
VAL_ 997 FT_TCR_Mode_aktiv 0 "TCR_Mode_deaktiv" 1 "TCR_Mode_aktiv" ;
VAL_ 997 TBF_FS_Touch_Event 0 "nicht_betaetigt" 1 "Tippen" 2 "Wischen" 3 "Geste" 4 "Doppeltippen" 5 "Longpress_1" 6 "Longpress_2" 7 "reserviert" 8 "reserviert" 9 "reserviert" 10 "reserviert" 11 "reserviert" 12 "reserviert" 13 "reserviert" 14 "reserviert" 15 "reserviert" ;
VAL_ 997 FT_KiSi_Status_Soll_HBFS 0 "inaktiv" 1 "aktiv" ;
VAL_ 997 FT_KiSi_Status_Soll_HFS 0 "inaktiv" 1 "aktiv" ;
VAL_ 997 FS_Push_Tuergriff 0 "nicht_erkannt" 1 "erkannt" ;
VAL_ 997 TSG_FS_Spiegel_angeklappt 0 "Spiegel_ausgeklappt" 1 "Spiegel_eingeklappt" ;
VAL_ 997 FT_Cargolock_bet 0 "nicht_betaetigt" 1 "betaetigt" ;
VAL_ 997 FT_kisi_asynchron 0 "nicht_aktiv" 1 "aktiv" ;
VAL_ 997 eTAB_FS_Bowdenzug_Auswerfen 0 "nicht_auswerfen" 1 "auswerfen" ;
VAL_ 997 FS_Status_eTAG_ext 0 "Griff_eingefahren" 1 "Griff_ausgefahren" 2 "Griff_verfaehrt" 3 "init" 4 "Fehler" ;
VAL_ 997 FT_ASW_Warnton 0 "kein_warnton" 1 "warnton_links" 2 "warnton_rechts" 3 "Fehler" ;
VAL_ 997 SSA_FT_ASW_Status 0 "Init" 1 "InfoStufe_aktiv" 2 "Warnstufe_aktiv" ;
VAL_ 2589283396 TSK_vMax_EfficiencyMode1 254 "kein_Limit_aktiv" 255 "Init" ;
VAL_ 2589283396 TSK_vMax_EfficiencyMode2 254 "kein_Limit_aktiv" 255 "Init" ;
VAL_ 2589283396 TSK_vMax_StandardMode 254 "kein_Limit_aktiv" 255 "Init" ;
VAL_ 1019 TSK_Ausrollkurve_Schub_Reku_01 127 "Init" ;
VAL_ 1019 TSK_Ausrollkurve_Schub_Reku_05 127 "Init" ;
VAL_ 1019 TSK_Ausrollkurve_Schub_Reku_09 127 "Init" ;
VAL_ 1019 TSK_Ausrollkurve_Schub_Reku_13 127 "Init" ;
VAL_ 1019 TSK_Ausrollkurve_Schub_Reku_17 127 "Init" ;
VAL_ 1019 TSK_Ausrollkurve_Schub_Reku_02 127 "Init" ;
VAL_ 1019 TSK_Ausrollkurve_Schub_Reku_06 127 "Init" ;
VAL_ 1019 TSK_Ausrollkurve_Schub_Reku_10 127 "Init" ;
VAL_ 1019 TSK_Ausrollkurve_Schub_Reku_14 127 "Init" ;
VAL_ 1019 TSK_Ausrollkurve_Schub_Reku_18 127 "Init" ;
VAL_ 1019 TSK_Ausrollkurve_Schub_Reku_03 127 "Init" ;
VAL_ 1019 TSK_Ausrollkurve_Schub_Reku_07 127 "Init" ;
VAL_ 1019 TSK_Ausrollkurve_Schub_Reku_11 127 "Init" ;
VAL_ 1019 TSK_Ausrollkurve_Schub_Reku_15 127 "Init" ;
VAL_ 1019 TSK_Ausrollkurve_Schub_Reku_19 127 "Init" ;
VAL_ 1019 TSK_Ausrollkurve_Schub_Reku_04 127 "Init" ;
VAL_ 1019 TSK_Ausrollkurve_Schub_Reku_08 127 "Init" ;
VAL_ 1019 TSK_Ausrollkurve_Schub_Reku_12 127 "Init" ;
VAL_ 1019 TSK_Ausrollkurve_Schub_Reku_16 127 "Init" ;
VAL_ 1019 TSK_Ausrollkurve_Schub_Reku_20 127 "Init" ;
VAL_ 1019 TSK_Ausrollkurve_Segeln_01 127 "Init" ;
VAL_ 1019 TSK_Ausrollkurve_Segeln_05 127 "Init" ;
VAL_ 1019 TSK_Ausrollkurve_Segeln_09 127 "Init" ;
VAL_ 1019 TSK_Ausrollkurve_Segeln_13 127 "Init" ;
VAL_ 1019 TSK_Ausrollkurve_Segeln_17 127 "Init" ;
VAL_ 1019 TSK_Ausrollkurve_Segeln_02 127 "Init" ;
VAL_ 1019 TSK_Ausrollkurve_Segeln_06 127 "Init" ;
VAL_ 1019 TSK_Ausrollkurve_Segeln_10 127 "Init" ;
VAL_ 1019 TSK_Ausrollkurve_Segeln_14 127 "Init" ;
VAL_ 1019 TSK_Ausrollkurve_Segeln_18 127 "Init" ;
VAL_ 1019 TSK_Ausrollkurve_Segeln_03 127 "Init" ;
VAL_ 1019 TSK_Ausrollkurve_Segeln_07 127 "Init" ;
VAL_ 1019 TSK_Ausrollkurve_Segeln_11 127 "Init" ;
VAL_ 1019 TSK_Ausrollkurve_Segeln_15 127 "Init" ;
VAL_ 1019 TSK_Ausrollkurve_Segeln_19 127 "Init" ;
VAL_ 1019 TSK_Ausrollkurve_Segeln_04 127 "Init" ;
VAL_ 1019 TSK_Ausrollkurve_Segeln_08 127 "Init" ;
VAL_ 1019 TSK_Ausrollkurve_Segeln_12 127 "Init" ;
VAL_ 1019 TSK_Ausrollkurve_Segeln_16 127 "Init" ;
VAL_ 1019 TSK_Ausrollkurve_Segeln_20 127 "Init" ;
VAL_ 1019 TSK_Ausrollkurve_Reku 0 "Rekuperation_nicht_beruecksichtigt" 1 "Rekuperation_beruecksichtigt" ;
VAL_ 1019 TSK_Ausrollkurve_Schrittweite 0 "Normale_Schrittweite" 1 "Grosse_Schrittweite" ;
VAL_ 2463978710 OPS_ComfortReadyStatus 0 "Init" 1 "aktiv" 2 "inaktiv" 3 "Fehler" ;
VAL_ 2463978710 OPS_OccupantPresenceStatus 0 "Init" 1 "OccupantAbsent" 2 "reserviert" 3 "OccupantEntryExit" 4 "reserviert" 5 "OccupantPresent" 6 "OccupantPresentVerified" 7 "Fehler" ;
VAL_ 2463978710 OPS_DriverPresenceStatus 0 "Init" 1 "reserviert" 2 "DriverAbsent" 3 "reserviert" 4 "DriverEntry" 5 "reserviert" 6 "DriverPresent" 7 "reserviert" 8 "DriverPresentVerified" 9 "reserviert" 10 "reserviert" 11 "DriverExitIntent" 12 "reserviert" 13 "DriverExit" 14 "reserviert" 15 "Fehler" ;
VAL_ 2463978710 OPS_QBit_DriverPresence 0 "gueltiger_Wert" 1 "Ersatz_Init_oder_Fehlerwert" ;
VAL_ 2463978710 OPS_SafeDriverPresenceStatus 0 "Init" 1 "Driver_Safe_Present" 2 "Driver_Not_Safe_Present" 3 "Fehler" ;
VAL_ 2463978710 OPS_SafeDriverPresence_available 0 "Verfuegbar" 1 "Verfuegbar_eingeschr_Performance" ;
VAL_ 995 VS_VD_zu_ver 1 "Zustand des Verdecks verriegelt und geschlossen" ;
VAL_ 995 VS_VD_entriegelt 0 "Init" 1 "Zustand_des_Verdeck_entriegelt" ;
VAL_ 995 VS_VD_offen_ver 0 "Init" 1 "Verdeck_verriegelt_und_offen" ;
VAL_ 995 VS_VD_Zwischenposition 0 "Init" 1 "Verdeck_in_Zwischenposition" ;
VAL_ 995 VS_VD_Bew_auf 1 "Verdeck in Bewegung auf" ;
VAL_ 995 VS_VD_Bew_zu 1 "Verdeck in Bewegung zu" ;
VAL_ 995 VS_Verdeck_Anf 0 "init_nicht_aktiv" 1 "aktiv" ;
VAL_ 995 VS_Hardtop 0 "Init" 1 "Hardtop_montiert" ;
VAL_ 995 VS_VD_Fehler 0 "Init" 1 "Fehlerzustand Verdeck" ;
VAL_ 995 VS_Lampe_Blk 0 "Kontrollleuchte_inaktiv" 1 "Kontrollleuchte_aktiv" ;
VAL_ 995 VS_HD_sperren 0 "HD Entriegelung freigegeben" 1 "HD Entriegelung gesperrt" ;
VAL_ 995 VS_HHS_enable 0 "Init" 1 "Freigabe HHS" ;
VAL_ 995 VD_SpannungsAnf 0 "keine_Anforderung" 1 "Anforderung_Stufe1" 2 "Anforderung_Stufe2" 3 "Anforderung_Stufe3" ;
VAL_ 995 VS_VDKD_auf 0 "VDKD_nicht_vollst_auf" 1 "VDKD_vollstaendig_auf" ;
VAL_ 995 VS_FS_AutoHoch 0 "Keine_Verfahranforderung" 1 "Automatischer_Hochlauf" ;
VAL_ 995 VS_FS_AutoTief 0 "Keine_Verfahranforderung" 1 "Automatischer_Tieflauf" ;
VAL_ 995 VS_FS_ManHoch 0 "Keine_Verfahranforderung" 1 "Manueller_Hochlauf" ;
VAL_ 995 VS_FS_ManTief 0 "Keine_Verfahranforderung" 1 "Manueller_Tieflauf" ;
VAL_ 995 VS_BFS_AutoHoch 0 "Keine_Verfahranforderung" 1 "Automatischer_Hochlauf" ;
VAL_ 995 VS_BFS_AutoTief 0 "Keine_Verfahranforderung" 1 "Automatischer_Tieflauf" ;
VAL_ 995 VS_BFS_ManHoch 0 "Keine_Verfahranforderung" 1 "Manueller_Hochlauf" ;
VAL_ 995 VS_BFS_ManTief 0 "Keine_Verfahranforderung" 1 "Manueller_Tieflauf" ;
VAL_ 995 VS_HFS_AutoHoch 0 "Keine_Verfahranforderung" 1 "Automatischer_Hochlauf" ;
VAL_ 995 VS_HFS_AutoTief 0 "Keine_Verfahranforderung" 1 "Automatischer_Tieflauf" ;
VAL_ 995 VS_HFS_ManHoch 0 "Keine_Verfahranforderung" 1 "Manueller_Hochlauf" ;
VAL_ 995 VS_HFS_ManTief 0 "Keine_Verfahranforderung" 1 "Manueller_Tieflauf" ;
VAL_ 995 VS_HBFS_AutoHoch 0 "Keine_Verfahranforderung" 1 "Automatischer_Hochlauf" ;
VAL_ 995 VS_HBFS_AutoTief 0 "Keine_Verfahranforderung" 1 "Automatischer_Tieflauf" ;
VAL_ 995 VS_HBFS_ManHoch 0 "Keine_Verfahranforderung" 1 "Manueller_Hochlauf" ;
VAL_ 995 VS_HBFS_ManTief 0 "Keine_Verfahranforderung" 1 "Manueller_Tieflauf" ;
VAL_ 995 VS_FH_FT_Langhub 0 "Init" ;
VAL_ 995 VS_Windschott_nicht_abgelegt 0 "inaktiv" 1 "aktiv" ;
VAL_ 995 VS_FH_BT_Langhub 0 "Init" ;
VAL_ 995 VS_FH_HFS_Langhub 0 "Init" ;
VAL_ 995 VS_Heckschloss_auf 0 "kein_Oeffnen" 1 "Heckschloss_oeffnen" ;
VAL_ 995 VS_FH_HBFS_Langhub 0 "Init" ;
VAL_ 995 VSG_Meldungen 0 "keine_Meldung" ;
VAL_ 995 VS_StartStopp_Info 0 "Stoppfreigabe" 1 "Stoppverbot" 2 "Startanforderung" 3 "Fehler" ;
